VERSION "HNNBNNNYNNNNNNNNNNNNNNNNNNNNNNNNNNNNNNNNNN/4/%%%/4/'%**4NNN///"

NS_ :

BS_:

BU_: BAP_Tester BedienDisp_mi BedienDisp_vo_mi CDI ConMod_CD DashCAM Gateway_Max ICC_IO_Node LSH OCU RDK_RS3 Sound_MIB_ab_Gen3 STH ZR_MIB_EINSTIEG_ab_Gen3 ZR_MIB_OPTION_ab_Gen3 ZR_MIB_TOP_ab_Gen3

BO_ 2536735504 BAP_SecEvents2_FSG_01: 8 ZR_MIB_EINSTIEG_ab_Gen3
 SG_ BAP_SecEvents2_FSG_01_Header : 0|64@1+ (1.0,0.0) [0.0|18446744073709551615] ""  Gateway_Max,OCU

BO_ 2536706560 BAP_SIA_ASG_01: 8 ZR_MIB_EINSTIEG_ab_Gen3
 SG_ BAP_SIA_ASG_01_Header : 0|8@1+ (1.0,0.0) [0.0|255] ""  Gateway_Max

BO_ 2536706561 BAP_SIA_ASG_02: 8 OCU
 SG_ BAP_SIA_ASG_02_Header : 0|8@1+ (1.0,0.0) [0.0|255] ""  Gateway_Max

BO_ 2536706576 BAP_SIA_FSG_01: 8 Gateway_Max
 SG_ BAP_SIA_FSG_01_Header : 0|8@1+ (1.0,0.0) [0.0|255] ""  OCU,ZR_MIB_EINSTIEG_ab_Gen3,ZR_MIB_OPTION_ab_Gen3,ZR_MIB_TOP_ab_Gen3

BO_ 2536706048 BAP_Sitz1_ASG_01: 8 ZR_MIB_EINSTIEG_ab_Gen3
 SG_ BAP_Sitz1_ASG_01_Header : 0|64@1+ (1.0,0.0) [0.0|18446744073709551615] ""  Gateway_Max

BO_ 2536706049 BAP_Sitz1_ASG_02: 8 OCU
 SG_ BAP_Sitz1_ASG_02_Header : 0|8@1+ (1,0) [0|255] "Unit_None"  Gateway_Max

BO_ 2536706064 BAP_Sitz1_FSG_01: 8 Gateway_Max
 SG_ BAP_Sitz1_FSG_01_Header : 0|8@1+ (1.0,0.0) [0.0|255] ""  OCU,ZR_MIB_EINSTIEG_ab_Gen3,ZR_MIB_OPTION_ab_Gen3,ZR_MIB_TOP_ab_Gen3

BO_ 2536710144 BAP_Sitz2_ASG_01: 8 ZR_MIB_EINSTIEG_ab_Gen3
 SG_ BAP_Sitz2_ASG_01_Header : 0|8@1+ (1.0,0.0) [0.0|255] ""  Gateway_Max

BO_ 2536710160 BAP_Sitz2_FSG_01: 8 Gateway_Max
 SG_ BAP_Sitz2_FSG_01_Header : 0|8@1+ (1.0,0.0) [0.0|255] ""  ZR_MIB_EINSTIEG_ab_Gen3,ZR_MIB_OPTION_ab_Gen3,ZR_MIB_TOP_ab_Gen3

BO_ 2536736000 BAP_SLCView_ASG_01: 8 ZR_MIB_EINSTIEG_ab_Gen3
 SG_ BAP_SLCView_ASG_01_Header : 0|64@1+ (1.0,0.0) [0.0|18446744073709551615] ""  Gateway_Max

BO_ 2536736016 BAP_SLCView_FSG_01: 8 Gateway_Max
 SG_ BAP_SLCView_FSG_01_Header : 0|64@1+ (1.0,0.0) [0.0|18446744073709551615] ""  ZR_MIB_EINSTIEG_ab_Gen3,ZR_MIB_OPTION_ab_Gen3

BO_ 2536720896 BAP_Statistics_ASG_01: 8 ZR_MIB_EINSTIEG_ab_Gen3
 SG_ BAP_Statistics_ASG_01_Header : 0|8@1+ (1,0) [0|255] "Unit_None"  Gateway_Max

BO_ 2536720912 BAP_Statistics_FSG_01: 8 Gateway_Max
 SG_ BAP_Statistics_FSG_01_Header : 0|8@1+ (1,0) [0|255] "Unit_None"  ZR_MIB_EINSTIEG_ab_Gen3,ZR_MIB_OPTION_ab_Gen3,ZR_MIB_TOP_ab_Gen3

BO_ 2536721152 BAP_Sunroof_ASG_01: 8 ZR_MIB_OPTION_ab_Gen3
 SG_ BAP_Sunroof_ASG_01_Header : 0|8@1+ (1,0) [0|255] "Unit_None"  Gateway_Max

BO_ 2536721168 BAP_Sunroof_FSG_01: 8 Gateway_Max
 SG_ BAP_Sunroof_FSG_01_Header : 0|8@1+ (1,0) [0|255] "Unit_None"  ZR_MIB_OPTION_ab_Gen3

BO_ 2536708608 BAP_SWA_ASG_01: 8 ZR_MIB_EINSTIEG_ab_Gen3
 SG_ BAP_SWA_ASG_01_Header : 0|8@1+ (1.0,0.0) [0.0|255] ""  Gateway_Max

BO_ 2536708610 BAP_SWA_ASG_03: 8 OCU
 SG_ BAP_SWA_ASG_03_Header : 0|8@1+ (1,0) [0|255] "Unit_None"  Gateway_Max

BO_ 2536708624 BAP_SWA_FSG_01: 8 Gateway_Max
 SG_ BAP_SWA_FSG_01_Header : 0|8@1+ (1.0,0.0) [0.0|255] ""  OCU,ZR_MIB_EINSTIEG_ab_Gen3,ZR_MIB_OPTION_ab_Gen3,ZR_MIB_TOP_ab_Gen3

BO_ 2536712448 BAP_Telefon2_ASG_01: 8 Gateway_Max
 SG_ BAP_Telefon2_ASG_01_Header : 0|8@1+ (1.0,0.0) [0.0|255] ""  ZR_MIB_OPTION_ab_Gen3,ZR_MIB_TOP_ab_Gen3

BO_ 2536712449 BAP_Telefon2_ASG_02: 8 Gateway_Max
 SG_ BAP_Telefon2_ASG_02_Header : 0|8@1+ (1,0) [0|255] "Unit_None"  ZR_MIB_OPTION_ab_Gen3

BO_ 2536712464 BAP_Telefon2_FSG_01: 8 ZR_MIB_OPTION_ab_Gen3
 SG_ BAP_Telefon2_FSG_01_Header : 0|8@1+ (1.0,0.0) [0.0|255] ""  Gateway_Max

BO_ 2536712465 BAP_Telefon2_FSG_02: 8 ZR_MIB_OPTION_ab_Gen3
 SG_ BAP_Telefon2_FSG_02_Header : 0|8@1+ (1,0) [0|255] "Unit_None"  Gateway_Max

BO_ 2536712192 BAP_Telefon_ASG_01: 8 Gateway_Max
 SG_ BAP_Telefon_ASG_01_Header : 0|8@1+ (1.0,0.0) [0.0|255] ""  ZR_MIB_EINSTIEG_ab_Gen3,ZR_MIB_OPTION_ab_Gen3,ZR_MIB_TOP_ab_Gen3

BO_ 2536712193 BAP_Telefon_ASG_02: 8 Gateway_Max
 SG_ BAP_Telefon_ASG_02_Header : 0|8@1+ (1.0,0.0) [0.0|255] ""  ZR_MIB_EINSTIEG_ab_Gen3,ZR_MIB_OPTION_ab_Gen3,ZR_MIB_TOP_ab_Gen3

BO_ 2536712194 BAP_Telefon_ASG_03: 8 Gateway_Max
 SG_ BAP_Telefon_ASG_03_Header : 0|8@1+ (1,0) [0|255] "Unit_None"  ZR_MIB_EINSTIEG_ab_Gen3,ZR_MIB_OPTION_ab_Gen3,ZR_MIB_TOP_ab_Gen3

BO_ 2536712195 BAP_Telefon_ASG_04: 8 Gateway_Max
 SG_ BAP_Telefon_ASG_04_Header : 0|8@1+ (1,0) [0|255] "Unit_None"  ZR_MIB_EINSTIEG_ab_Gen3,ZR_MIB_OPTION_ab_Gen3,ZR_MIB_TOP_ab_Gen3

BO_ 2536712208 BAP_Telefon_FSG_01: 8 ZR_MIB_EINSTIEG_ab_Gen3
 SG_ BAP_Telefon_FSG_01_Header : 0|8@1+ (1.0,0.0) [0.0|255] ""  Gateway_Max

BO_ 2536712209 BAP_Telefon_FSG_02: 8 ZR_MIB_EINSTIEG_ab_Gen3
 SG_ BAP_Telefon_FSG_02_Header : 0|8@1+ (1.0,0.0) [0.0|255] ""  Gateway_Max

BO_ 2536726273 BAP_TPA_ASG_02: 8 ZR_MIB_EINSTIEG_ab_Gen3
 SG_ BAP_TPA_ASG_02_Header : 0|64@1+ (1.0,0.0) [0.0|18446744073709551615] ""  Gateway_Max

BO_ 2536726288 BAP_TPA_FSG_01: 8 Gateway_Max
 SG_ BAP_TPA_FSG_01_Header : 0|64@1+ (1.0,0.0) [0.0|18446744073709551615] ""  ZR_MIB_EINSTIEG_ab_Gen3,ZR_MIB_OPTION_ab_Gen3,ZR_MIB_TOP_ab_Gen3

BO_ 2536715776 BAP_TrailerAssist_ASG_01: 8 ZR_MIB_EINSTIEG_ab_Gen3
 SG_ BAP_TrailerAssist_ASG_01_Header : 0|8@1+ (1.0,0.0) [0.0|255] ""  Gateway_Max

BO_ 2536715792 BAP_TrailerAssist_FSG_01: 8 Gateway_Max
 SG_ BAP_TrailerAssist_FSG_01_Header : 0|8@1+ (1.0,0.0) [0.0|255] ""  ZR_MIB_EINSTIEG_ab_Gen3,ZR_MIB_OPTION_ab_Gen3

BO_ 2536706304 BAP_Uhrzeit_ASG_01: 8 ZR_MIB_EINSTIEG_ab_Gen3
 SG_ BAP_Uhrzeit_ASG_01_Header : 0|8@1+ (1.0,0.0) [0.0|255] ""  Gateway_Max

BO_ 2536706308 BAP_Uhrzeit_ASG_05: 8 OCU
 SG_ BAP_Uhrzeit_ASG_05_Header : 0|8@1+ (1.0,0.0) [0.0|255] ""  Gateway_Max

BO_ 2536706320 BAP_Uhrzeit_FSG_01: 8 Gateway_Max
 SG_ BAP_Uhrzeit_FSG_01_Header : 0|8@1+ (1.0,0.0) [0.0|255] ""  OCU,ZR_MIB_EINSTIEG_ab_Gen3,ZR_MIB_OPTION_ab_Gen3,ZR_MIB_TOP_ab_Gen3

BO_ 2536710400 BAP_VZA_ASG_01: 8 ZR_MIB_EINSTIEG_ab_Gen3
 SG_ BAP_VZA_ASG_01_Header : 0|8@1+ (1.0,0.0) [0.0|255] ""  Gateway_Max

BO_ 2536710403 BAP_VZA_ASG_04: 8 OCU
 SG_ BAP_VZA_ASG_04_Header : 0|8@1+ (1,0) [0|255] "Unit_None"  Gateway_Max

BO_ 2536710416 BAP_VZA_FSG_01: 8 Gateway_Max
 SG_ BAP_VZA_FSG_01_Header : 0|8@1+ (1.0,0.0) [0.0|255] ""  OCU,ZR_MIB_EINSTIEG_ab_Gen3,ZR_MIB_OPTION_ab_Gen3,ZR_MIB_TOP_ab_Gen3

BO_ 2536705024 BAP_Wiper_ASG_01: 8 ZR_MIB_EINSTIEG_ab_Gen3
 SG_ BAP_Wiper_ASG_01_Header : 0|8@1+ (1.0,0.0) [0.0|255] ""  Gateway_Max

BO_ 2536705025 BAP_Wiper_ASG_02: 8 OCU
 SG_ BAP_Wiper_ASG_02_Header : 0|8@1+ (1,0) [0|255] "Unit_None"  Gateway_Max

BO_ 2536705040 BAP_Wiper_FSG_01: 8 Gateway_Max
 SG_ BAP_Wiper_FSG_01_Header : 0|8@1+ (1.0,0.0) [0.0|255] ""  OCU,ZR_MIB_EINSTIEG_ab_Gen3,ZR_MIB_OPTION_ab_Gen3,ZR_MIB_TOP_ab_Gen3

BO_ 1626 BCM_01: 8 Gateway_Max
 SG_ BCM_Bremsbelag_Sensor : 12|1@1+ (1.0,0.0) [0.0|1] ""  OCU
 SG_ BCM_Bremsfluessigkeit_Sensor : 13|1@1+ (1.0,0.0) [0.0|1] ""  OCU
 SG_ BCM1_Licht_Warn : 14|1@1+ (1.0,0.0) [0.0|1] ""  BedienDisp_vo_mi,OCU
 SG_ BCM_Waschwasser_Sensor : 15|1@1+ (1.0,0.0) [0.0|1] ""  OCU
 SG_ BCM_Kuehlmittel_Sensor : 16|1@1+ (1.0,0.0) [0.0|1] ""  OCU
 SG_ BCM1_Kl_15_HW_erkannt : 17|1@1+ (1.0,0.0) [0.0|1] ""  Vector__XXX
 SG_ BCM1_Kl_15_Sig_HW_erkannt : 18|1@1+ (1.0,0.0) [0.0|1] ""  Vector__XXX
 SG_ BCM_Kuehlmittel_Sensor_02 : 19|1@1+ (1.0,0.0) [0.0|1] ""  Vector__XXX
 SG_ BCM1_Hinweis_Lichtnachlauf : 20|1@1+ (1.0,0.0) [0.0|1] ""  Vector__XXX
 SG_ BCM_Offroad_Taste : 21|1@1+ (1.0,0.0) [0.0|1] ""  Vector__XXX
 SG_ BCM_Charisma_Taste2 : 22|1@1+ (1.0,0.0) [0.0|1] ""  Vector__XXX
 SG_ BCM_Hybrid_StSt_Taste_Fehler : 23|1@1+ (1.0,0.0) [0.0|1] ""  Vector__XXX
 SG_ BCM_Hybrid_StartStopp_Taste : 24|1@1+ (1.0,0.0) [0.0|1] ""  Vector__XXX
 SG_ BCM1_Warnblink_Taster : 25|1@1+ (1.0,0.0) [0.0|1] ""  Vector__XXX
 SG_ BCM1_Valet_Parking_Taster : 26|1@1+ (1.0,0.0) [0.0|1] ""  Vector__XXX
 SG_ BCM1_LDS_Stellung : 27|3@1+ (1.0,0.0) [0.0|7] ""  OCU
 SG_ BCM1_Rueckfahrlicht_Schalter : 30|1@1+ (1.0,0.0) [0.0|1] ""  OCU
 SG_ BCM1_MH_Schalter : 31|1@1+ (1.0,0.0) [0.0|1] ""  OCU,ZR_MIB_EINSTIEG_ab_Gen3,ZR_MIB_OPTION_ab_Gen3
 SG_ BCM1_MH_WIV_Schalter : 32|1@1+ (1.0,0.0) [0.0|1] ""  Vector__XXX
 SG_ BCM_Eco_Charisma_Taste : 33|1@1+ (1.0,0.0) [0.0|1] ""  Vector__XXX
 SG_ BCM1_NV_Taster : 34|1@1+ (1.0,0.0) [0.0|1] ""  Vector__XXX
 SG_ BCM1_AFS_Lampe : 35|1@1+ (1.0,0.0) [0.0|1] ""  Vector__XXX
 SG_ BCM1_Reisemodus_Texte : 36|2@1+ (1.0,0.0) [0.0|3] ""  Vector__XXX
 SG_ BCM1_Lichtwarn_Texte : 38|2@1+ (1.0,0.0) [0.0|3] ""  Vector__XXX
 SG_ Gong_TFL_Umschaltung : 40|1@1+ (1.0,0.0) [0.0|1] ""  Vector__XXX
 SG_ BCM_ValetTaster_Fkts_LED : 42|1@1+ (1.0,0.0) [0.0|1] ""  ZR_MIB_EINSTIEG_ab_Gen3,ZR_MIB_OPTION_ab_Gen3,ZR_MIB_TOP_ab_Gen3
 SG_ LRH_Taster : 43|1@1+ (1.0,0.0) [0.0|1] ""  OCU
 SG_ APS_Tongeber_defekt : 44|1@1+ (1.0,0.0) [0.0|1] ""  Vector__XXX
 SG_ BCM1_EasyEntry_Status : 45|1@1+ (1.0,0.0) [0.0|1] ""  Vector__XXX
 SG_ BCM1_Lenksaeule_aktiv : 46|1@1+ (1.0,0.0) [0.0|1] ""  Vector__XXX
 SG_ BCM1_Spannungs_Anf : 47|2@1+ (1.0,0.0) [0.0|3] ""  Vector__XXX
 SG_ DWA_Alarmquelle : 49|5@1+ (1.0,0.0) [0.0|31] ""  OCU
 SG_ DWA_Einschraenkung : 54|1@1+ (1.0,0.0) [0.0|1] ""  Vector__XXX
 SG_ BCM_HBFS_EOE_aktiv : 56|1@1+ (1.0,0.0) [0.0|1] ""  Vector__XXX
 SG_ BCM_HFS_EOE_aktiv : 57|1@1+ (1.0,0.0) [0.0|1] ""  Vector__XXX
 SG_ BCM_Anf_AAW_MoLaWa : 58|2@1+ (1.0,0.0) [0.0|3] ""  Vector__XXX
 SG_ BCM_Handbremse_Hinweis : 60|1@1+ (1.0,0.0) [0.0|1] ""  Vector__XXX
 SG_ BCM_Waehlhebel_P_Hinweis : 61|1@1+ (1.0,0.0) [0.0|1] ""  Vector__XXX
 SG_ BCM1_Fahrlicht_Hinweis : 62|1@1+ (1.0,0.0) [0.0|1] ""  Vector__XXX
 SG_ BCM_HDF_betaetigt : 63|1@1+ (1.0,0.0) [0.0|1] ""  Vector__XXX

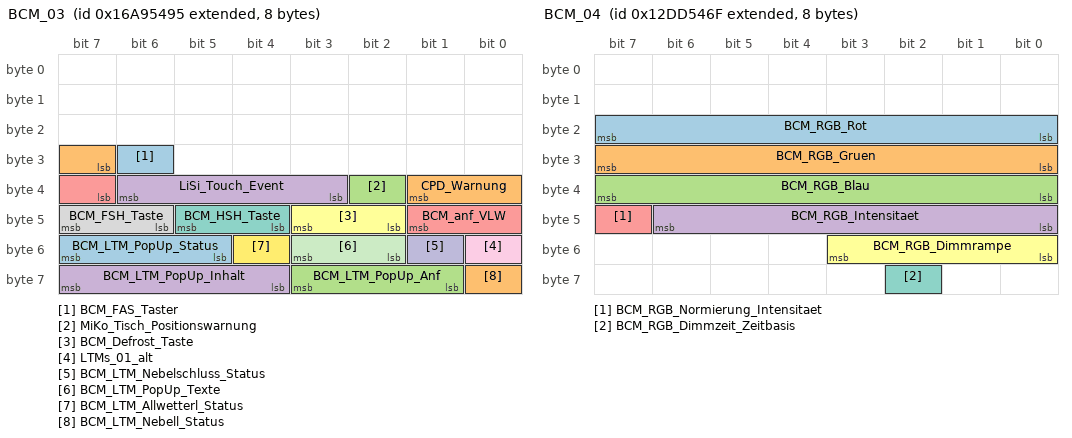
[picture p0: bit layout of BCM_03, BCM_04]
BO_ 2527679637 BCM_03: 8 Gateway_Max
 SG_ BCM_FAS_Taster : 30|1@1+ (1.0,0.0) [0.0|1] ""  ZR_MIB_TOP_ab_Gen3
 SG_ CPD_Warnung : 31|3@1+ (1.0,0.0) [0.0|7] ""  Vector__XXX
 SG_ MiKo_Tisch_Positionswarnung : 34|1@1+ (1.0,0.0) [0.0|1] ""  Vector__XXX
 SG_ LiSi_Touch_Event : 35|4@1+ (1.0,0.0) [0.0|15] ""  ICC_IO_Node,ZR_MIB_EINSTIEG_ab_Gen3,ZR_MIB_OPTION_ab_Gen3,ZR_MIB_TOP_ab_Gen3
 SG_ BCM_anf_VLW : 39|3@1+ (1.0,0.0) [0.0|7] ""  Vector__XXX
 SG_ BCM_Defrost_Taste : 42|2@1+ (1.0,0.0) [0.0|3] ""  Vector__XXX
 SG_ BCM_HSH_Taste : 44|2@1+ (1.0,0.0) [0.0|3] ""  Vector__XXX
 SG_ BCM_FSH_Taste : 46|2@1+ (1.0,0.0) [0.0|3] ""  Vector__XXX
 SG_ LTMs_01_alt : 48|1@1+ (1.0,0.0) [0.0|1] ""  Vector__XXX
 SG_ BCM_LTM_Nebelschluss_Status : 49|1@1+ (1.0,0.0) [0.0|1] ""  Vector__XXX
 SG_ BCM_LTM_PopUp_Texte : 50|2@1+ (1.0,0.0) [0.0|3] ""  Vector__XXX
 SG_ BCM_LTM_Allwetterl_Status : 52|1@1+ (1.0,0.0) [0.0|1] ""  Vector__XXX
 SG_ BCM_LTM_PopUp_Status : 53|3@1+ (1.0,0.0) [0.0|7] ""  Vector__XXX
 SG_ BCM_LTM_Nebell_Status : 56|1@1+ (1.0,0.0) [0.0|1] ""  Vector__XXX
 SG_ BCM_LTM_PopUp_Anf : 57|3@1+ (1.0,0.0) [0.0|7] ""  Vector__XXX
 SG_ BCM_LTM_PopUp_Inhalt : 60|4@1+ (1.0,0.0) [0.0|15] ""  Vector__XXX

BO_ 2463978607 BCM_04: 8 Gateway_Max
 SG_ BCM_RGB_Rot : 16|8@1+ (1,0) [0|255] ""  BedienDisp_mi,BedienDisp_vo_mi,CDI,ZR_MIB_EINSTIEG_ab_Gen3,ZR_MIB_OPTION_ab_Gen3,ZR_MIB_TOP_ab_Gen3
 SG_ BCM_RGB_Gruen : 24|8@1+ (1,0) [0|255] ""  BedienDisp_mi,BedienDisp_vo_mi,CDI,ZR_MIB_EINSTIEG_ab_Gen3,ZR_MIB_OPTION_ab_Gen3,ZR_MIB_TOP_ab_Gen3
 SG_ BCM_RGB_Blau : 32|8@1+ (1,0) [0|255] ""  BedienDisp_mi,BedienDisp_vo_mi,CDI,ZR_MIB_EINSTIEG_ab_Gen3,ZR_MIB_OPTION_ab_Gen3,ZR_MIB_TOP_ab_Gen3
 SG_ BCM_RGB_Intensitaet : 40|7@1+ (1,0) [0|100] "Unit_PerCent"  BedienDisp_mi,BedienDisp_vo_mi
 SG_ BCM_RGB_Normierung_Intensitaet : 47|1@1+ (1.0,0.0) [0.0|1] ""  Vector__XXX
 SG_ BCM_RGB_Dimmrampe : 48|4@1+ (0.25,0) [0.00|3.75] "Unit_Secon"  BedienDisp_mi,BedienDisp_vo_mi
 SG_ BCM_RGB_Dimmzeit_Zeitbasis : 58|1@1+ (1.0,0.0) [0.0|1] ""  BedienDisp_mi,BedienDisp_vo_mi

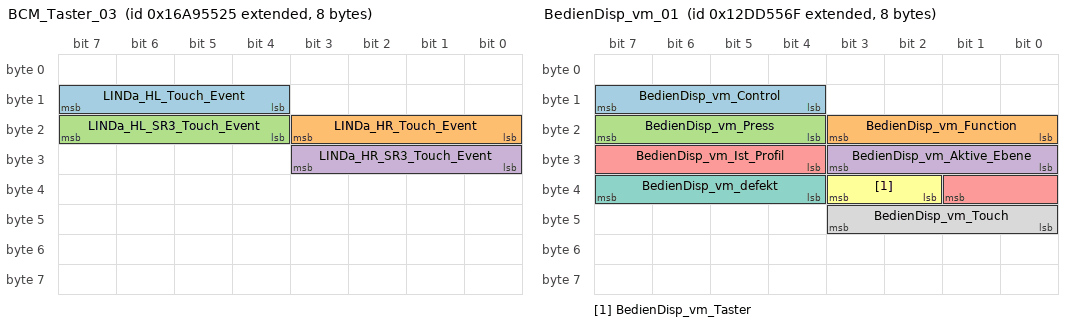
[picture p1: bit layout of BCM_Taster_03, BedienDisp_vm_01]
BO_ 2527679781 BCM_Taster_03: 8 Gateway_Max
 SG_ LINDa_HL_Touch_Event : 12|4@1+ (1.0,0.0) [0.0|15] ""  ICC_IO_Node,ZR_MIB_EINSTIEG_ab_Gen3,ZR_MIB_OPTION_ab_Gen3,ZR_MIB_TOP_ab_Gen3
 SG_ LINDa_HR_Touch_Event : 16|4@1+ (1.0,0.0) [0.0|15] ""  ICC_IO_Node,ZR_MIB_EINSTIEG_ab_Gen3,ZR_MIB_OPTION_ab_Gen3,ZR_MIB_TOP_ab_Gen3
 SG_ LINDa_HL_SR3_Touch_Event : 20|4@1+ (1.0,0.0) [0.0|15] ""  ICC_IO_Node,ZR_MIB_EINSTIEG_ab_Gen3,ZR_MIB_OPTION_ab_Gen3,ZR_MIB_TOP_ab_Gen3
 SG_ LINDa_HR_SR3_Touch_Event : 24|4@1+ (1.0,0.0) [0.0|15] ""  ICC_IO_Node,ZR_MIB_EINSTIEG_ab_Gen3,ZR_MIB_OPTION_ab_Gen3,ZR_MIB_TOP_ab_Gen3

BO_ 2463978882 BedienDisp_hbfs_01: 8 Gateway_Max
 SG_ BedienDisp_hbfs_01_CRC : 0|8@1+ (1,0) [0|255] ""  Vector__XXX
 SG_ BedienDisp_hbfs_01_BZ : 8|4@1+ (1,0) [0|15] ""  Vector__XXX
 SG_ BedienDisp_hbfs_control_vol : 12|4@1+ (1.0,0.0) [0.0|15] ""  ZR_MIB_OPTION_ab_Gen3
 SG_ BedienDisp_hbfs_fader : 16|4@1+ (1.0,0.0) [0.0|15] ""  Vector__XXX
 SG_ BedienDisp_hbfs_surround : 20|4@1+ (1.0,0.0) [0.0|15] ""  ZR_MIB_OPTION_ab_Gen3
 SG_ BedienDisp_hbfs_sound : 24|4@1+ (1.0,0.0) [0.0|15] ""  Vector__XXX
 SG_ BedienDisp_hbfs_Lordose_hoch : 28|1@1+ (1.0,0.0) [0.0|1] ""  Vector__XXX
 SG_ BedienDisp_hbfs_Lordose_runter : 29|1@1+ (1.0,0.0) [0.0|1] ""  Vector__XXX
 SG_ BedienDisp_hbfs_Lordose_vor : 30|1@1+ (1.0,0.0) [0.0|1] ""  Vector__XXX
 SG_ BedienDisp_hbfs_Lordose_zurueck : 31|1@1+ (1.0,0.0) [0.0|1] ""  Vector__XXX
 SG_ BedienDisp_hbfs_touch : 32|4@1+ (1.0,0.0) [0.0|15] ""  ZR_MIB_OPTION_ab_Gen3
 SG_ BedienDisp_hbfs_sound_fokus : 36|4@1+ (1.0,0.0) [0.0|15] ""  ZR_MIB_OPTION_ab_Gen3
 SG_ BedienDisp_hbfs_surround_02 : 40|7@1+ (1,0) [0|100] "Unit_None"  Vector__XXX
 SG_ BedienDisp_hbfs_control_vol_02 : 47|7@1+ (1,0) [0|100] "Unit_None"  ZR_MIB_OPTION_ab_Gen3
 SG_ BedienDisp_HBFSFo_Bestaetigung : 54|2@1+ (1.0,0.0) [0.0|3] ""  Vector__XXX
 SG_ BedienDisp_HBFSFo_Stoerung : 56|2@1+ (1.0,0.0) [0.0|3] ""  Vector__XXX
 SG_ BedienDisp_hbfs_UseCase_Pos : 58|3@1+ (1.0,0.0) [0.0|7] ""  Vector__XXX

BO_ 2463978886 BedienDisp_hbfs_02: 8 Gateway_Max
 SG_ BedienDisp_hbfs_02_CRC : 0|8@1+ (1,0) [0|255] ""  Vector__XXX
 SG_ BedienDisp_hbfs_02_BZ : 8|4@1+ (1,0) [0|15] ""  Vector__XXX
 SG_ BedienDisp_hbfs_Sitz_Laengs : 12|3@1+ (1.0,0.0) [0.0|7] ""  Vector__XXX
 SG_ BedienDisp_hbfs_Sitz_Hoehe : 15|2@1+ (1.0,0.0) [0.0|3] ""  Vector__XXX
 SG_ BedienDisp_hbfs_Sitz_Neigung : 17|3@1+ (1.0,0.0) [0.0|7] ""  Vector__XXX
 SG_ BedienDisp_hbfs_Sitz_Bein : 20|3@1+ (1.0,0.0) [0.0|7] ""  Vector__XXX
 SG_ BedienDisp_hbfs_Sitz_Lehne : 23|3@1+ (1.0,0.0) [0.0|7] ""  Vector__XXX
 SG_ BedienDisp_hbfs_Sitz_Lehnekopf : 26|2@1+ (1.0,0.0) [0.0|3] ""  Vector__XXX
 SG_ BedienDisp_hbfs_Sitz_Kopf : 28|3@1+ (1.0,0.0) [0.0|7] ""  Vector__XXX
 SG_ BedienDisp_hbfs_Sitz_Arm : 31|3@1+ (1.0,0.0) [0.0|7] ""  Vector__XXX
 SG_ BedienDisp_hbfs_Seat_SetReset : 34|2@1+ (1.0,0.0) [0.0|3] ""  Vector__XXX
 SG_ BedienDisp_hbfs_Seat_Storage : 36|3@1+ (1.0,0.0) [0.0|7] ""  Vector__XXX
 SG_ BedienDisp_hbfs_Mem_Start : 39|2@1+ (1.0,0.0) [0.0|3] ""  Vector__XXX
 SG_ BedienDisp_hbfs_Cargo_Pos : 41|2@1+ (1.0,0.0) [0.0|3] ""  Vector__XXX
 SG_ BedienDisp_hbfs_Normal_Pos : 43|2@1+ (1.0,0.0) [0.0|3] ""  Vector__XXX
 SG_ BedienDisp_hbfs_BF_Hoehe : 45|2@1+ (1.0,0.0) [0.0|3] ""  Vector__XXX
 SG_ BedienDisp_hbfs_BF_Laengs : 47|3@1+ (1.0,0.0) [0.0|7] ""  Vector__XXX
 SG_ BedienDisp_hbfs_BF_Lehne : 50|3@1+ (1.0,0.0) [0.0|7] ""  Vector__XXX
 SG_ BedienDisp_hbfs_Memo_Pos : 53|3@1+ (1.0,0.0) [0.0|7] ""  Vector__XXX
 SG_ BedienDisp_hbfs_Sitz_Stop : 56|2@1+ (1.0,0.0) [0.0|3] ""  Vector__XXX
 SG_ BedienDisp_hbfs_Komfor_Pos : 58|3@1+ (1.0,0.0) [0.0|7] ""  Vector__XXX

BO_ 2463978881 BedienDisp_hfs_01: 8 Gateway_Max
 SG_ BedienDisp_hfs_01_CRC : 0|8@1+ (1,0) [0|255] ""  Vector__XXX
 SG_ BedienDisp_hfs_01_BZ : 8|4@1+ (1,0) [0|15] ""  Vector__XXX
 SG_ BedienDisp_hfs_control_vol : 12|4@1+ (1.0,0.0) [0.0|15] ""  ZR_MIB_OPTION_ab_Gen3
 SG_ BedienDisp_hfs_fader : 16|4@1+ (1.0,0.0) [0.0|15] ""  Vector__XXX
 SG_ BedienDisp_hfs_surround : 20|4@1+ (1.0,0.0) [0.0|15] ""  ZR_MIB_OPTION_ab_Gen3
 SG_ BedienDisp_hfs_sound : 24|4@1+ (1.0,0.0) [0.0|15] ""  Vector__XXX
 SG_ BedienDisp_hfs_Lordose_hoch : 28|1@1+ (1.0,0.0) [0.0|1] ""  Vector__XXX
 SG_ BedienDisp_hfs_Lordose_runter : 29|1@1+ (1.0,0.0) [0.0|1] ""  Vector__XXX
 SG_ BedienDisp_hfs_Lordose_vor : 30|1@1+ (1.0,0.0) [0.0|1] ""  Vector__XXX
 SG_ BedienDisp_hfs_Lordose_zurueck : 31|1@1+ (1.0,0.0) [0.0|1] ""  Vector__XXX
 SG_ BedienDisp_hfs_touch : 32|4@1+ (1.0,0.0) [0.0|15] ""  ZR_MIB_OPTION_ab_Gen3
 SG_ BedienDisp_hfs_sound_fokus : 36|4@1+ (1.0,0.0) [0.0|15] ""  ZR_MIB_OPTION_ab_Gen3
 SG_ BedienDisp_hfs_surround_02 : 40|7@1+ (1,0) [0|100] "Unit_None"  Vector__XXX
 SG_ BedienDisp_hfs_control_vol_02 : 47|7@1+ (1,0) [0|100] "Unit_None"  ZR_MIB_OPTION_ab_Gen3
 SG_ BedienDisp_HFSFo_Bestaetigung : 54|2@1+ (1.0,0.0) [0.0|3] ""  Vector__XXX
 SG_ BedienDisp_HFSFo_Stoerung : 56|2@1+ (1.0,0.0) [0.0|3] ""  Vector__XXX
 SG_ BedienDisp_hfs_UseCase_Pos : 58|3@1+ (1.0,0.0) [0.0|7] ""  Vector__XXX

BO_ 2463978885 BedienDisp_hfs_02: 8 Gateway_Max
 SG_ BedienDisp_hfs_02_CRC : 0|8@1+ (1,0) [0|255] ""  Vector__XXX
 SG_ BedienDisp_hfs_02_BZ : 8|4@1+ (1,0) [0|15] ""  Vector__XXX
 SG_ BedienDisp_hfs_Sitz_Laengs : 12|3@1+ (1.0,0.0) [0.0|7] ""  Vector__XXX
 SG_ BedienDisp_hfs_Sitz_Hoehe : 15|2@1+ (1.0,0.0) [0.0|3] ""  Vector__XXX
 SG_ BedienDisp_hfs_Sitz_Neigung : 17|3@1+ (1.0,0.0) [0.0|7] ""  Vector__XXX
 SG_ BedienDisp_hfs_Sitz_Bein : 20|3@1+ (1.0,0.0) [0.0|7] ""  Vector__XXX
 SG_ BedienDisp_hfs_Sitz_Lehne : 23|3@1+ (1.0,0.0) [0.0|7] ""  Vector__XXX
 SG_ BedienDisp_hfs_Sitz_Lehnekopf : 26|2@1+ (1.0,0.0) [0.0|3] ""  Vector__XXX
 SG_ BedienDisp_hfs_Sitz_Kopf : 28|3@1+ (1.0,0.0) [0.0|7] ""  Vector__XXX
 SG_ BedienDisp_hfs_Sitz_Arm : 31|3@1+ (1.0,0.0) [0.0|7] ""  Vector__XXX
 SG_ BedienDisp_hfs_Seat_SetReset : 34|2@1+ (1.0,0.0) [0.0|3] ""  Vector__XXX
 SG_ BedienDisp_hfs_Seat_Storage : 36|3@1+ (1.0,0.0) [0.0|7] ""  Vector__XXX
 SG_ BedienDisp_hfs_Mem_Start : 39|2@1+ (1.0,0.0) [0.0|3] ""  Vector__XXX
 SG_ BedienDisp_hfs_Cargo_Pos : 41|2@1+ (1.0,0.0) [0.0|3] ""  Vector__XXX
 SG_ BedienDisp_hfs_Normal_Pos : 43|2@1+ (1.0,0.0) [0.0|3] ""  Vector__XXX
 SG_ BedienDisp_hfs_BF_Hoehe : 45|2@1+ (1.0,0.0) [0.0|3] ""  Vector__XXX
 SG_ BedienDisp_hfs_BF_Laengs : 47|3@1+ (1.0,0.0) [0.0|7] ""  Vector__XXX
 SG_ BedienDisp_hfs_BF_Lehne : 50|3@1+ (1.0,0.0) [0.0|7] ""  Vector__XXX
 SG_ BedienDisp_hfs_Memo_Pos : 53|3@1+ (1.0,0.0) [0.0|7] ""  Vector__XXX
 SG_ BedienDisp_hfs_Sitz_Stop : 56|2@1+ (1.0,0.0) [0.0|3] ""  Vector__XXX
 SG_ BedienDisp_hfs_Komfor_Pos : 58|3@1+ (1.0,0.0) [0.0|7] ""  Vector__XXX

BO_ 2463978863 BedienDisp_vm_01: 8 BedienDisp_vo_mi
 SG_ BedienDisp_vm_Control : 12|4@1+ (1.0,0.0) [0.0|15] ""  Gateway_Max,ZR_MIB_OPTION_ab_Gen3
 SG_ BedienDisp_vm_Function : 16|4@1+ (1.0,0.0) [0.0|15] ""  Gateway_Max,ZR_MIB_OPTION_ab_Gen3
 SG_ BedienDisp_vm_Press : 20|4@1+ (1.0,0.0) [0.0|15] ""  Gateway_Max,ZR_MIB_OPTION_ab_Gen3
 SG_ BedienDisp_vm_Aktive_Ebene : 24|4@1+ (1.0,0.0) [0.0|15] ""  Gateway_Max
 SG_ BedienDisp_vm_Ist_Profil : 28|6@1+ (1.0,0.0) [0.0|63] ""  Gateway_Max
 SG_ BedienDisp_vm_Taster : 34|2@1+ (1.0,0.0) [0.0|3] ""  Gateway_Max
 SG_ BedienDisp_vm_defekt : 36|4@1+ (1.0,0.0) [0.0|15] ""  Gateway_Max
 SG_ BedienDisp_vm_Touch : 40|4@1+ (1.0,0.0) [0.0|15] ""  Gateway_Max

BO_ 1635 BEM_02: 8 Gateway_Max
 SG_ NVEM_Abschaltstufe : 0|2@1+ (1.0,0.0) [0.0|3] ""  BedienDisp_vo_mi,CDI,ICC_IO_Node,LSH,OCU,STH,ZR_MIB_EINSTIEG_ab_Gen3,ZR_MIB_OPTION_ab_Gen3,ZR_MIB_TOP_ab_Gen3
 SG_ BEM_STH_Zielzeit : 3|4@1+ (5,0) [0|60] "Unit_Minut"  ICC_IO_Node,OCU,ZR_MIB_EINSTIEG_ab_Gen3,ZR_MIB_OPTION_ab_Gen3,ZR_MIB_TOP_ab_Gen3
 SG_ BEM_MMI_Vorwarnung : 7|1@1+ (1.0,0.0) [0.0|1] ""  ICC_IO_Node,ZR_MIB_EINSTIEG_ab_Gen3,ZR_MIB_OPTION_ab_Gen3,ZR_MIB_TOP_ab_Gen3
 SG_ BEM_HL_Kontingentierung : 8|6@1+ (50,-1000) [-1000|1000] "Unit_Watt"  ICC_IO_Node,ZR_MIB_EINSTIEG_ab_Gen3,ZR_MIB_OPTION_ab_Gen3,ZR_MIB_TOP_ab_Gen3
 SG_ NVEM_Freigabe_ZusBatt_Laden : 14|1@1+ (1.0,0.0) [0.0|1] ""  ICC_IO_Node,OCU,ZR_MIB_EINSTIEG_ab_Gen3,ZR_MIB_OPTION_ab_Gen3,ZR_MIB_TOP_ab_Gen3
 SG_ NVEM_Anf_SD_schalten : 15|1@1+ (1.0,0.0) [0.0|1] ""  ICC_IO_Node,ZR_MIB_EINSTIEG_ab_Gen3,ZR_MIB_OPTION_ab_Gen3,ZR_MIB_TOP_ab_Gen3
 SG_ BEM_Generatordiagnose : 16|2@1+ (1.0,0.0) [0.0|3] ""  ICC_IO_Node,ZR_MIB_EINSTIEG_ab_Gen3,ZR_MIB_OPTION_ab_Gen3,ZR_MIB_TOP_ab_Gen3
 SG_ BEM_Red_Innengeblaese : 18|2@1+ (1.0,0.0) [0.0|3] ""  ICC_IO_Node,OCU,ZR_MIB_EINSTIEG_ab_Gen3,ZR_MIB_OPTION_ab_Gen3,ZR_MIB_TOP_ab_Gen3
 SG_ BEM_STH_Einschaltverbot : 20|1@1+ (1.0,0.0) [0.0|1] ""  ICC_IO_Node,LSH,OCU,STH,ZR_MIB_EINSTIEG_ab_Gen3,ZR_MIB_OPTION_ab_Gen3,ZR_MIB_TOP_ab_Gen3
 SG_ BEM_HL_Regelung_Status : 21|3@1+ (1.0,0.0) [0.0|7] ""  ICC_IO_Node,LSH,OCU,STH,ZR_MIB_EINSTIEG_ab_Gen3,ZR_MIB_OPTION_ab_Gen3,ZR_MIB_TOP_ab_Gen3
 SG_ BEM_Ladezustand : 24|4@1+ (10,0) [0|100] "Unit_PerCent"  ICC_IO_Node,OCU,ZR_MIB_EINSTIEG_ab_Gen3,ZR_MIB_OPTION_ab_Gen3,ZR_MIB_TOP_ab_Gen3
 SG_ BEM_Batteriediagnose : 28|3@1+ (1.0,0.0) [0.0|7] ""  ICC_IO_Node,ZR_MIB_EINSTIEG_ab_Gen3,ZR_MIB_OPTION_ab_Gen3,ZR_MIB_TOP_ab_Gen3
 SG_ MIB_Stromsparmodus : 31|1@1+ (1.0,0.0) [0.0|1] ""  ICC_IO_Node,ZR_MIB_EINSTIEG_ab_Gen3,ZR_MIB_OPTION_ab_Gen3,ZR_MIB_TOP_ab_Gen3
 SG_ BEM_DFM : 32|5@1+ (3.225,0.025) [0.025|100.000] ""  ICC_IO_Node,OCU,ZR_MIB_EINSTIEG_ab_Gen3,ZR_MIB_OPTION_ab_Gen3,ZR_MIB_TOP_ab_Gen3
 SG_ BEM_REK_aktiv : 37|1@1+ (1.0,0.0) [0.0|1] ""  ICC_IO_Node,ZR_MIB_EINSTIEG_ab_Gen3,ZR_MIB_OPTION_ab_Gen3,ZR_MIB_TOP_ab_Gen3
 SG_ BEM_EMLIN_ungueltig : 38|1@1+ (1.0,0.0) [0.0|1] ""  ICC_IO_Node,OCU,ZR_MIB_EINSTIEG_ab_Gen3,ZR_MIB_OPTION_ab_Gen3,ZR_MIB_TOP_ab_Gen3
 SG_ BEM_Batt_Ab : 39|1@1+ (1.0,0.0) [0.0|1] ""  ICC_IO_Node,LSH,OCU,STH,ZR_MIB_EINSTIEG_ab_Gen3,ZR_MIB_OPTION_ab_Gen3,ZR_MIB_TOP_ab_Gen3
 SG_ BEM_UBDM : 40|8@1+ (0.05,5) [5.05|17.70] "Unit_Volt"  ICC_IO_Node,OCU,ZR_MIB_EINSTIEG_ab_Gen3,ZR_MIB_OPTION_ab_Gen3,ZR_MIB_TOP_ab_Gen3
 SG_ BEM_UGenSoll : 48|6@1+ (0.1,10.6) [10.6|16.0] "Unit_Volt"  ICC_IO_Node,ZR_MIB_EINSTIEG_ab_Gen3,ZR_MIB_OPTION_ab_Gen3,ZR_MIB_TOP_ab_Gen3
 SG_ BEM_Anf_KL15_schalten : 54|2@1+ (1.0,0.0) [0.0|3] ""  ICC_IO_Node,OCU,ZR_MIB_EINSTIEG_ab_Gen3,ZR_MIB_OPTION_ab_Gen3,ZR_MIB_TOP_ab_Gen3
 SG_ NVEM_Batterie_Service : 56|2@1+ (1.0,0.0) [0.0|3] ""  ICC_IO_Node,ZR_MIB_EINSTIEG_ab_Gen3,ZR_MIB_OPTION_ab_Gen3,ZR_MIB_TOP_ab_Gen3
 SG_ NVEM_Freigabe_OnlineUpdate : 58|1@1+ (1.0,0.0) [0.0|1] ""  ICC_IO_Node,OCU,ZR_MIB_EINSTIEG_ab_Gen3,ZR_MIB_OPTION_ab_Gen3,ZR_MIB_TOP_ab_Gen3
 SG_ NVEM_Freigabe_ORU4 : 59|2@1+ (1.0,0.0) [0.0|3] ""  ICC_IO_Node,ZR_MIB_EINSTIEG_ab_Gen3,ZR_MIB_OPTION_ab_Gen3,ZR_MIB_TOP_ab_Gen3
 SG_ NVEM_Verbraucherabsch_Anz : 61|1@1+ (1.0,0.0) [0.0|1] ""  ICC_IO_Node,ZR_MIB_EINSTIEG_ab_Gen3,ZR_MIB_OPTION_ab_Gen3,ZR_MIB_TOP_ab_Gen3

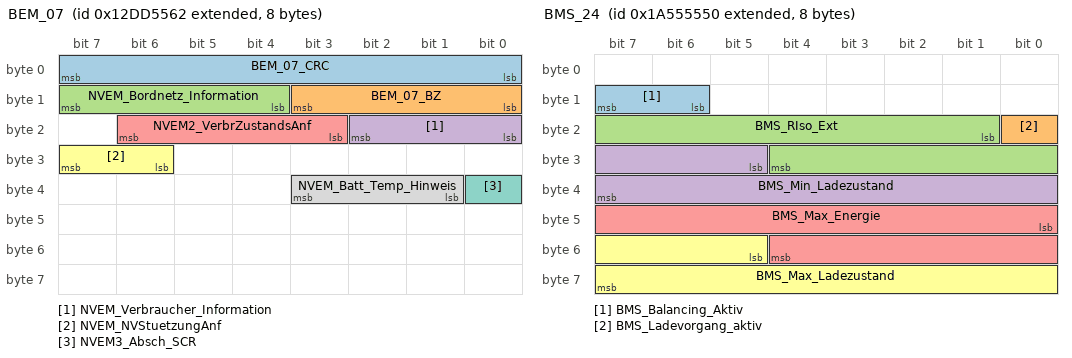
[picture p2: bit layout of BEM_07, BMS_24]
BO_ 2463978850 BEM_07: 8 Gateway_Max
 SG_ BEM_07_CRC : 0|8@1+ (1,0) [0|255] ""  Vector__XXX
 SG_ BEM_07_BZ : 8|4@1+ (1,0) [0|15] ""  Vector__XXX
 SG_ NVEM_Bordnetz_Information : 12|4@1+ (1.0,0.0) [0.0|15] ""  Vector__XXX
 SG_ NVEM_Verbraucher_Information : 16|3@1+ (1.0,0.0) [0.0|7] ""  CDI,OCU,ZR_MIB_EINSTIEG_ab_Gen3,ZR_MIB_OPTION_ab_Gen3,ZR_MIB_TOP_ab_Gen3
 SG_ NVEM2_VerbrZustandsAnf : 19|4@1+ (1.0,0.0) [0.0|15] ""  Vector__XXX
 SG_ NVEM_NVStuetzungAnf : 30|2@1+ (1.0,0.0) [0.0|3] ""  Vector__XXX
 SG_ NVEM3_Absch_SCR : 32|1@1+ (1.0,0.0) [0.0|1] ""  Vector__XXX
 SG_ NVEM_Batt_Temp_Hinweis : 33|3@1+ (1.0,0.0) [0.0|7] ""  Vector__XXX

BO_ 870 Blinkmodi_02: 8 Gateway_Max
 SG_ Blinkmodi_02_CRC : 0|8@1+ (1,0) [0|255] ""  Vector__XXX
 SG_ Blinkmodi_02_BZ : 8|4@1+ (1,0) [0|15] ""  Vector__XXX
 SG_ BM_ZV_auf : 12|1@1+ (1.0,0.0) [0.0|1] ""  Vector__XXX
 SG_ BM_ZV_zu : 13|1@1+ (1.0,0.0) [0.0|1] ""  Vector__XXX
 SG_ BM_DWA_ein : 14|1@1+ (1.0,0.0) [0.0|1] ""  OCU
 SG_ BM_DWA_Alarm : 15|1@1+ (1.0,0.0) [0.0|1] ""  OCU
 SG_ BM_Crash : 16|1@1+ (1.0,0.0) [0.0|1] ""  OCU
 SG_ BM_Panik : 17|1@1+ (1.0,0.0) [0.0|1] ""  OCU
 SG_ BM_Not_Bremsung : 18|1@1+ (1.0,0.0) [0.0|1] ""  OCU
 SG_ BM_GDO : 19|1@1+ (1.0,0.0) [0.0|1] ""  Vector__XXX
 SG_ BM_Warnblinken : 20|1@1+ (1.0,0.0) [0.0|1] ""  OCU
 SG_ BM_Taxi_Notalarm : 21|1@1+ (1.0,0.0) [0.0|1] ""  Vector__XXX
 SG_ BM_Telematik : 22|1@1+ (1.0,0.0) [0.0|1] ""  OCU
 SG_ BM_links : 23|1@1+ (1.0,0.0) [0.0|1] ""  DashCAM,OCU,ZR_MIB_EINSTIEG_ab_Gen3,ZR_MIB_OPTION_ab_Gen3
 SG_ BM_rechts : 24|1@1+ (1.0,0.0) [0.0|1] ""  DashCAM,OCU,ZR_MIB_EINSTIEG_ab_Gen3,ZR_MIB_OPTION_ab_Gen3
 SG_ Blinken_li_Fzg_Takt : 25|1@1+ (1.0,0.0) [0.0|1] ""  ZR_MIB_EINSTIEG_ab_Gen3
 SG_ Blinken_re_Fzg_Takt : 26|1@1+ (1.0,0.0) [0.0|1] ""  ZR_MIB_EINSTIEG_ab_Gen3
 SG_ Blinken_li_Kombi_Takt : 27|1@1+ (1.0,0.0) [0.0|1] ""  ZR_MIB_EINSTIEG_ab_Gen3,ZR_MIB_OPTION_ab_Gen3,ZR_MIB_TOP_ab_Gen3
 SG_ Blinken_re_Kombi_Takt : 28|1@1+ (1.0,0.0) [0.0|1] ""  ZR_MIB_EINSTIEG_ab_Gen3,ZR_MIB_OPTION_ab_Gen3,ZR_MIB_TOP_ab_Gen3
 SG_ BM_NBA_n_codiert_n_aktiv : 29|1@1+ (1.0,0.0) [0.0|1] ""  Vector__XXX
 SG_ BM_NBA_Status : 30|2@1+ (1.0,0.0) [0.0|3] ""  Vector__XXX
 SG_ BM_WBT_Beleuchtung : 32|1@1+ (1.0,0.0) [0.0|1] ""  Vector__XXX
 SG_ BM_HD_Oeffnung_angelernt : 33|1@1+ (1.0,0.0) [0.0|1] ""  Vector__XXX
 SG_ BM_Autobahn : 34|1@1+ (1.0,0.0) [0.0|1] ""  ZR_MIB_EINSTIEG_ab_Gen3,ZR_MIB_OPTION_ab_Gen3,ZR_MIB_TOP_ab_Gen3
 SG_ BM_Rollenmodus_Blinken : 35|1@1+ (1.0,0.0) [0.0|1] ""  Vector__XXX
 SG_ BM_Recas : 36|1@1+ (1.0,0.0) [0.0|1] ""  Vector__XXX
 SG_ BM_Wischblinken : 37|1@1+ (1.0,0.0) [0.0|1] ""  Vector__XXX
 SG_ BM_Telematik_Abbruchgrund : 38|6@1+ (1.0,0.0) [0.0|63] ""  OCU
 SG_ BM_PiloPa : 44|1@1+ (1.0,0.0) [0.0|1] ""  Vector__XXX
 SG_ SAL_TA_Blinken_Status : 45|3@1+ (1.0,0.0) [0.0|7] ""  Vector__XXX
 SG_ BM_WBA_Warnblinken : 48|1@1+ (1.0,0.0) [0.0|1] ""  Vector__XXX
 SG_ SAL_RHP_Blinken_Status : 49|3@1+ (1.0,0.0) [0.0|7] ""  Vector__XXX
 SG_ SAL_RHP_Warnblinken : 52|1@1+ (1.0,0.0) [0.0|1] ""  Vector__XXX

BO_ 2589283664 BMS_24: 8 Gateway_Max
 SG_ BMS_Balancing_Aktiv : 14|2@1+ (1.0,0.0) [0.0|3] ""  Vector__XXX
 SG_ BMS_Ladevorgang_aktiv : 16|1@1+ (1.0,0.0) [0.0|1] ""  ZR_MIB_TOP_ab_Gen3
 SG_ BMS_RIso_Ext : 17|12@1+ (5,0) [0|20465] "Unit_KiloOhm"  Vector__XXX
 SG_ BMS_Min_Ladezustand : 29|11@1+ (0.05,0) [0.00|100.00] "Unit_PerCent"  Vector__XXX
 SG_ BMS_Max_Energie : 40|13@1+ (40,0) [0|327400] "Unit_WattHour"  Vector__XXX
 SG_ BMS_Max_Ladezustand : 53|11@1+ (0.05,0) [0.00|100.00] "Unit_PerCent"  Vector__XXX

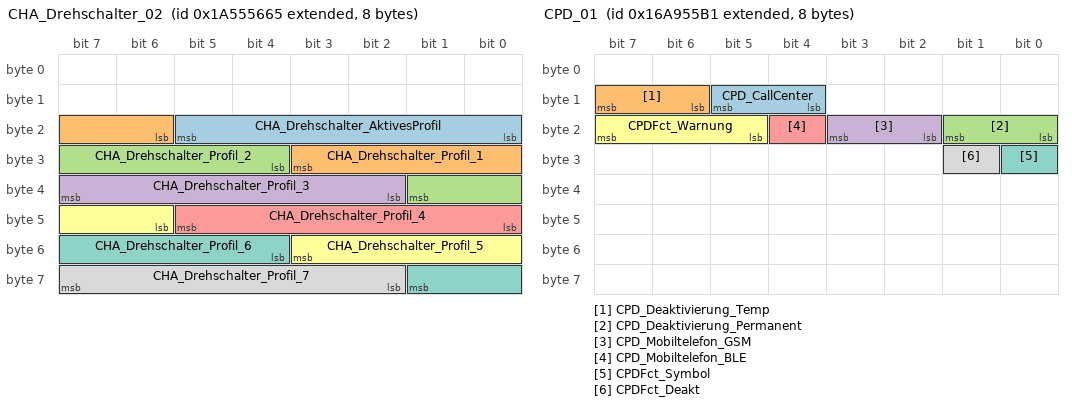
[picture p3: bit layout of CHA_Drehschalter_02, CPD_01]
BO_ 2589283941 CHA_Drehschalter_02: 8 Gateway_Max
 SG_ CHA_Drehschalter_AktivesProfil : 16|6@1+ (1.0,0.0) [0.0|63] ""  BedienDisp_mi,BedienDisp_vo_mi
 SG_ CHA_Drehschalter_Profil_1 : 22|6@1+ (1.0,0.0) [0.0|63] ""  BedienDisp_mi,BedienDisp_vo_mi
 SG_ CHA_Drehschalter_Profil_2 : 28|6@1+ (1.0,0.0) [0.0|63] ""  BedienDisp_mi,BedienDisp_vo_mi
 SG_ CHA_Drehschalter_Profil_3 : 34|6@1+ (1.0,0.0) [0.0|63] ""  BedienDisp_mi,BedienDisp_vo_mi
 SG_ CHA_Drehschalter_Profil_4 : 40|6@1+ (1.0,0.0) [0.0|63] ""  BedienDisp_mi,BedienDisp_vo_mi
 SG_ CHA_Drehschalter_Profil_5 : 46|6@1+ (1.0,0.0) [0.0|63] ""  BedienDisp_mi,BedienDisp_vo_mi
 SG_ CHA_Drehschalter_Profil_6 : 52|6@1+ (1.0,0.0) [0.0|63] ""  BedienDisp_mi,BedienDisp_vo_mi
 SG_ CHA_Drehschalter_Profil_7 : 58|6@1+ (1.0,0.0) [0.0|63] ""  BedienDisp_mi,BedienDisp_vo_mi

BO_ 902 Charisma_03: 8 Gateway_Max
 SG_ CHA_Charisma_Taste2_LED : 0|2@1+ (1.0,0.0) [0.0|3] ""  Vector__XXX
 SG_ CHA_ReqPrgDispSetup : 2|4@1+ (1.0,0.0) [0.0|15] ""  Vector__XXX
 SG_ CHA_Current_Mode_FPA : 6|6@1+ (1.0,0.0) [0.0|63] ""  ZR_MIB_OPTION_ab_Gen3
 SG_ CHA_Eco_Charisma_LED : 12|2@1+ (1.0,0.0) [0.0|3] ""  Vector__XXX
 SG_ CHA_Fahrer_Umschaltung : 14|1@1+ (1.0,0.0) [0.0|1] ""  Vector__XXX
 SG_ CHA_EV_LED : 15|1@1+ (1.0,0.0) [0.0|1] ""  Vector__XXX
 SG_ CHA_Ziel_FahrPr_AMB : 16|4@1+ (1.0,0.0) [0.0|15] ""  Vector__XXX
 SG_ CHA_Ziel_FahrPr_IVB : 20|4@1+ (1.0,0.0) [0.0|15] ""  Vector__XXX
 SG_ CHA_Kombi_Texte : 24|4@1+ (1.0,0.0) [0.0|15] ""  Vector__XXX
 SG_ CHA_Ziel_FahrPr_KL : 28|4@1+ (1.0,0.0) [0.0|15] ""  Vector__XXX
 SG_ CHA_Ziel_FahrPr_HSP : 32|4@1+ (1.0,0.0) [0.0|15] ""  Vector__XXX
 SG_ CHA_StCurProfDft : 36|2@1+ (1.0,0.0) [0.0|3] ""  Vector__XXX
 SG_ CHA_Ziel_FahrPr_RWB : 40|4@1+ (1.0,0.0) [0.0|15] ""  Vector__XXX
 SG_ CHA_Ziel_FahrPr_03_01 : 44|4@1+ (1.0,0.0) [0.0|15] ""  Vector__XXX
 SG_ CHA_Ziel_FahrPr_03_02 : 48|4@1+ (1.0,0.0) [0.0|15] ""  Vector__XXX
 SG_ CHA_Current_Mode : 52|4@1+ (1.0,0.0) [0.0|15] ""  Vector__XXX
 SG_ CHA_Charge_LED : 57|1@1+ (1.0,0.0) [0.0|1] ""  Vector__XXX
 SG_ CHA_Offroad_LED : 58|2@1+ (1.0,0.0) [0.0|3] ""  Vector__XXX
 SG_ CHA_Kombi_Texte_02 : 60|4@1+ (1.0,0.0) [0.0|15] ""  Vector__XXX

BO_ 2527679921 CPD_01: 8 Gateway_Max
 SG_ CPD_CallCenter : 12|2@1+ (1.0,0.0) [0.0|3] ""  Vector__XXX
 SG_ CPD_Deaktivierung_Temp : 14|2@1+ (1.0,0.0) [0.0|3] ""  Vector__XXX
 SG_ CPD_Deaktivierung_Permanent : 16|2@1+ (1.0,0.0) [0.0|3] ""  Vector__XXX
 SG_ CPD_Mobiltelefon_GSM : 18|2@1+ (1.0,0.0) [0.0|3] ""  Vector__XXX
 SG_ CPD_Mobiltelefon_BLE : 20|1@1+ (1.0,0.0) [0.0|1] ""  Vector__XXX
 SG_ CPDFct_Warnung : 21|3@1+ (1.0,0.0) [0.0|7] ""  Vector__XXX
 SG_ CPDFct_Symbol : 24|1@1+ (1.0,0.0) [0.0|1] ""  Vector__XXX
 SG_ CPDFct_Deakt : 25|1@1+ (1.0,0.0) [0.0|1] ""  ZR_MIB_OPTION_ab_Gen3

BO_ 2549880334 DIA_ABT_1_Req: 8 Gateway_Max
 SG_ DIA_ABT_1_Req_Data : 0|64@1+ (1.0,0.0) [0.0|18446744073709551615] ""  ICC_IO_Node,ZR_MIB_EINSTIEG_ab_Gen3,ZR_MIB_OPTION_ab_Gen3

BO_ 2550011406 DIA_ABT_1_Resp: 8 ICC_IO_Node
 SG_ DIA_ABT_1_Resp_Data : 0|64@1+ (1.0,0.0) [0.0|18446744073709551615] ""  Gateway_Max

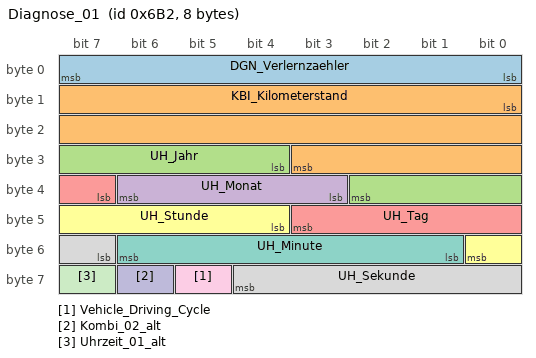
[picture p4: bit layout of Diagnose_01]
BO_ 1714 Diagnose_01: 8 Gateway_Max
 SG_ DGN_Verlernzaehler : 0|8@1+ (1,0) [0|254] ""  BedienDisp_mi,BedienDisp_vo_mi,ConMod_CD,DashCAM,ICC_IO_Node,LSH,OCU,RDK_RS3,STH,ZR_MIB_EINSTIEG_ab_Gen3,ZR_MIB_OPTION_ab_Gen3,ZR_MIB_TOP_ab_Gen3
 SG_ KBI_Kilometerstand : 8|20@1+ (1,0) [0|1048573] "Unit_KiloMeter"  BedienDisp_mi,BedienDisp_vo_mi,ConMod_CD,DashCAM,ICC_IO_Node,LSH,OCU,RDK_RS3,STH,ZR_MIB_EINSTIEG_ab_Gen3,ZR_MIB_OPTION_ab_Gen3,ZR_MIB_TOP_ab_Gen3
 SG_ UH_Jahr : 28|7@1+ (1,2000) [2000|2127] "Unit_Year"  BedienDisp_mi,BedienDisp_vo_mi,ConMod_CD,DashCAM,ICC_IO_Node,LSH,OCU,RDK_RS3,STH,ZR_MIB_EINSTIEG_ab_Gen3,ZR_MIB_OPTION_ab_Gen3,ZR_MIB_TOP_ab_Gen3
 SG_ UH_Monat : 35|4@1+ (1,0) [1|12] "Unit_Month"  BedienDisp_mi,BedienDisp_vo_mi,ConMod_CD,DashCAM,ICC_IO_Node,LSH,OCU,RDK_RS3,STH,ZR_MIB_EINSTIEG_ab_Gen3,ZR_MIB_OPTION_ab_Gen3,ZR_MIB_TOP_ab_Gen3
 SG_ UH_Tag : 39|5@1+ (1,0) [1|31] "Unit_Day"  BedienDisp_mi,BedienDisp_vo_mi,ConMod_CD,DashCAM,ICC_IO_Node,LSH,OCU,RDK_RS3,STH,ZR_MIB_EINSTIEG_ab_Gen3,ZR_MIB_OPTION_ab_Gen3,ZR_MIB_TOP_ab_Gen3
 SG_ UH_Stunde : 44|5@1+ (1,0) [0|23] "Unit_Hours"  BedienDisp_mi,BedienDisp_vo_mi,ConMod_CD,DashCAM,ICC_IO_Node,LSH,OCU,RDK_RS3,STH,ZR_MIB_EINSTIEG_ab_Gen3,ZR_MIB_OPTION_ab_Gen3,ZR_MIB_TOP_ab_Gen3
 SG_ UH_Minute : 49|6@1+ (1,0) [0|59] "Unit_Minut"  BedienDisp_mi,BedienDisp_vo_mi,ConMod_CD,DashCAM,ICC_IO_Node,LSH,OCU,RDK_RS3,STH,ZR_MIB_EINSTIEG_ab_Gen3,ZR_MIB_OPTION_ab_Gen3,ZR_MIB_TOP_ab_Gen3
 SG_ UH_Sekunde : 55|6@1+ (1,0) [0|59] "Unit_Secon"  BedienDisp_mi,BedienDisp_vo_mi,ConMod_CD,DashCAM,ICC_IO_Node,LSH,OCU,RDK_RS3,STH,ZR_MIB_EINSTIEG_ab_Gen3,ZR_MIB_OPTION_ab_Gen3,ZR_MIB_TOP_ab_Gen3
 SG_ Vehicle_Driving_Cycle : 61|1@1+ (1.0,0.0) [0.0|1] ""  ConMod_CD,ICC_IO_Node,OCU,ZR_MIB_EINSTIEG_ab_Gen3,ZR_MIB_OPTION_ab_Gen3,ZR_MIB_TOP_ab_Gen3
 SG_ Kombi_02_alt : 62|1@1+ (1.0,0.0) [0.0|1] ""  ConMod_CD,DashCAM,ICC_IO_Node,LSH,OCU,RDK_RS3,STH,ZR_MIB_EINSTIEG_ab_Gen3,ZR_MIB_OPTION_ab_Gen3,ZR_MIB_TOP_ab_Gen3
 SG_ Uhrzeit_01_alt : 63|1@1+ (1.0,0.0) [0.0|1] ""  ConMod_CD,DashCAM,ICC_IO_Node,LSH,OCU,RDK_RS3,STH,ZR_MIB_EINSTIEG_ab_Gen3,ZR_MIB_OPTION_ab_Gen3,ZR_MIB_TOP_ab_Gen3

BO_ 851 DiETa_01: 8 Gateway_Max
 SG_ DiETas_01_CRC : 0|8@1+ (1,0) [0|255] ""  Vector__XXX
 SG_ DiETas_01_BZ : 8|4@1+ (1,0) [0|15] ""  Vector__XXX
 SG_ DiETa_Reserve_Byte2_4 : 12|1@1+ (1.0,0.0) [0.0|1] ""  Vector__XXX
 SG_ DiETa_Status : 13|2@1+ (1.0,0.0) [0.0|3] ""  Vector__XXX
 SG_ DiETa_ResponseError : 15|1@1+ (1.0,0.0) [0.0|1] ""  Vector__XXX
 SG_ DiETa_Car : 16|2@1+ (1.0,0.0) [0.0|3] ""  ZR_MIB_EINSTIEG_ab_Gen3,ZR_MIB_OPTION_ab_Gen3
 SG_ DiETa_Klima : 18|2@1+ (1.0,0.0) [0.0|3] ""  Vector__XXX
 SG_ DiETa_Mode : 20|2@1+ (1.0,0.0) [0.0|3] ""  Vector__XXX
 SG_ DiETa_Parken : 22|2@1+ (1.0,0.0) [0.0|3] ""  Vector__XXX
 SG_ DiETa_FSH_Taste : 24|2@1+ (1.0,0.0) [0.0|3] ""  Vector__XXX
 SG_ DiETa_HSH_Taste : 26|2@1+ (1.0,0.0) [0.0|3] ""  Vector__XXX
 SG_ DiETa_Warnblink_Taste : 28|2@1+ (1.0,0.0) [0.0|3] ""  Vector__XXX
 SG_ DiETa_FAS_Stufe : 30|2@1+ (1.0,0.0) [0.0|3] ""  Vector__XXX
 SG_ DiETa_PAO_ON_Status : 32|2@1+ (1.0,0.0) [0.0|3] ""  Vector__XXX
 SG_ DiETa_PAO_OFF_Status : 34|2@1+ (1.0,0.0) [0.0|3] ""  Vector__XXX
 SG_ DiETa_Defrost_Taste : 36|2@1+ (1.0,0.0) [0.0|3] ""  Vector__XXX
 SG_ DiETa_Mode2 : 38|2@1+ (1.0,0.0) [0.0|3] ""  Vector__XXX
 SG_ DiETa_Lock_Unlock_Taste : 40|3@1+ (1.0,0.0) [0.0|7] ""  Vector__XXX
 SG_ DiETa_Mode_roh : 43|1@1+ (1.0,0.0) [0.0|1] ""  Vector__XXX
 SG_ ESP_Off_Taster : 44|2@1+ (1.0,0.0) [0.0|3] ""  Vector__XXX
 SG_ DiETa_Reserve_Byte6_6 : 46|2@1+ (1.0,0.0) [0.0|3] ""  Vector__XXX
 SG_ DiETa_Touch_Event : 48|4@1+ (1.0,0.0) [0.0|15] ""  ZR_MIB_EINSTIEG_ab_Gen3,ZR_MIB_OPTION_ab_Gen3,ZR_MIB_TOP_ab_Gen3
 SG_ DiETa_Reserve_Byte7_4 : 52|4@1+ (1.0,0.0) [0.0|15] ""  Vector__XXX
 SG_ DiETa_Reserve_Byte8 : 56|8@1+ (1.0,0.0) [0.0|255] ""  Vector__XXX

BO_TX_BU_ 2536735504 :ZR_MIB_EINSTIEG_ab_Gen3,ZR_MIB_OPTION_ab_Gen3;
BO_TX_BU_ 2536706560 :ZR_MIB_EINSTIEG_ab_Gen3,ZR_MIB_OPTION_ab_Gen3,ZR_MIB_TOP_ab_Gen3;
BO_TX_BU_ 2536706048 :ZR_MIB_EINSTIEG_ab_Gen3,ZR_MIB_OPTION_ab_Gen3,ZR_MIB_TOP_ab_Gen3;
BO_TX_BU_ 2536710144 :ZR_MIB_EINSTIEG_ab_Gen3,ZR_MIB_OPTION_ab_Gen3,ZR_MIB_TOP_ab_Gen3;
BO_TX_BU_ 2536736000 :ZR_MIB_EINSTIEG_ab_Gen3,ZR_MIB_OPTION_ab_Gen3;
BO_TX_BU_ 2536720896 :ZR_MIB_EINSTIEG_ab_Gen3,ZR_MIB_OPTION_ab_Gen3,ZR_MIB_TOP_ab_Gen3;
BO_TX_BU_ 2536708608 :ZR_MIB_EINSTIEG_ab_Gen3,ZR_MIB_OPTION_ab_Gen3,ZR_MIB_TOP_ab_Gen3;
BO_TX_BU_ 2536712464 :ZR_MIB_OPTION_ab_Gen3,ZR_MIB_TOP_ab_Gen3;
BO_TX_BU_ 2536712465 :ZR_MIB_OPTION_ab_Gen3,ZR_MIB_TOP_ab_Gen3;
BO_TX_BU_ 2536712208 :ZR_MIB_EINSTIEG_ab_Gen3,ZR_MIB_OPTION_ab_Gen3,ZR_MIB_TOP_ab_Gen3;
BO_TX_BU_ 2536712209 :ZR_MIB_EINSTIEG_ab_Gen3,ZR_MIB_OPTION_ab_Gen3,ZR_MIB_TOP_ab_Gen3;
BO_TX_BU_ 2536726273 :ZR_MIB_EINSTIEG_ab_Gen3,ZR_MIB_OPTION_ab_Gen3,ZR_MIB_TOP_ab_Gen3;
BO_TX_BU_ 2536715776 :ZR_MIB_EINSTIEG_ab_Gen3,ZR_MIB_OPTION_ab_Gen3;
BO_TX_BU_ 2536706304 :ZR_MIB_EINSTIEG_ab_Gen3,ZR_MIB_OPTION_ab_Gen3,ZR_MIB_TOP_ab_Gen3;
BO_TX_BU_ 2536710400 :ZR_MIB_EINSTIEG_ab_Gen3,ZR_MIB_OPTION_ab_Gen3,ZR_MIB_TOP_ab_Gen3;
BO_TX_BU_ 2536705024 :ZR_MIB_EINSTIEG_ab_Gen3,ZR_MIB_OPTION_ab_Gen3,ZR_MIB_TOP_ab_Gen3;
BO_TX_BU_ 2550011406 :ICC_IO_Node,ZR_MIB_EINSTIEG_ab_Gen3,ZR_MIB_OPTION_ab_Gen3;
CM_ BO_ 1635 "DLC=8 ab D4 gültig";
CM_ BO_ 870 "Nur die Kombination des statischen und toggelnden Signals ergibt den Blinktakt für die Hell & Dunkelphase";
CM_ BO_ 902 "ab MQB 7.2.1";

CM_ SG_ 2536735504 BAP_SecEvents2_FSG_01_Header "Security Events für IDS (Intrusion Detection System)
LSG ID - 131dez (SecurityEvents2)";

CM_ SG_ 2536706048 BAP_Sitz1_ASG_01_Header "Sitz1 Anzeigesteuergeraet";

CM_ SG_ 2536706049 BAP_Sitz1_ASG_02_Header "Sitz1 Anzeigesteuergeraet";

CM_ SG_ 2536736000 BAP_SLCView_ASG_01_Header "SideLeaveCarView Anzeigesteuergeraet
LCU ID - 133dez";

CM_ SG_ 2536736016 BAP_SLCView_FSG_01_Header "SideLeaveCarView Funktionssteuergeraet
LCU ID - 133dez";

CM_ SG_ 2536720896 BAP_Statistics_ASG_01_Header "Statistics Anzeigesteuergeraet";

CM_ SG_ 2536720912 BAP_Statistics_FSG_01_Header "Statistics Funktionssteuergeraet";

CM_ SG_ 2536721152 BAP_Sunroof_ASG_01_Header "BAP Anzeige für SAD vorderes Dachelement.";

CM_ SG_ 2536721168 BAP_Sunroof_FSG_01_Header "BAP Anzeige für SAD vorderes Dachelement.";

CM_ SG_ 2536708610 BAP_SWA_ASG_03_Header "SWA Anzeigesteuergeraet";

CM_ SG_ 2536712448 BAP_Telefon2_ASG_01_Header "MQB AUDI: keine Verwendung im ZR Entry";

CM_ SG_ 2536712449 BAP_Telefon2_ASG_02_Header "Telefon2 Anzeigesteuergeraet
MMI <-> Head-Up Display";

CM_ SG_ 2536712464 BAP_Telefon2_FSG_01_Header "MQB AUDI: keine Verwendung im ZR Entry";

CM_ SG_ 2536712465 BAP_Telefon2_FSG_02_Header "BAP Strecke Telefon zum Kombi";

CM_ SG_ 2536712192 BAP_Telefon_ASG_01_Header "MQB AUDI: keine Verwendung im ZR Entry";

CM_ SG_ 2536712193 BAP_Telefon_ASG_02_Header "MQB AUDI: keine Verwendung im ZR Entry";

CM_ SG_ 2536712194 BAP_Telefon_ASG_03_Header "Telefon Anzeigesteuergeraet
Head-Up";

CM_ SG_ 2536712195 BAP_Telefon_ASG_04_Header "Telefon Anzeigesteuergeraet
MMI<->Head-Up Display";

CM_ SG_ 2536712208 BAP_Telefon_FSG_01_Header "MQB AUDI: keine Verwendung im ZR Entry";

CM_ SG_ 2536712209 BAP_Telefon_FSG_02_Header "MQB AUDI: keine Verwendung im ZR Entry";

CM_ SG_ 2536726273 BAP_TPA_ASG_02_Header "Parktrajektorie Anzeigesteuergerät";

CM_ SG_ 2536726288 BAP_TPA_FSG_01_Header "Parktrajektorie Funktionssteuergeraet";

CM_ SG_ 2536710403 BAP_VZA_ASG_04_Header "VZA Anzeigesteuergeraet";

CM_ SG_ 2536705025 BAP_Wiper_ASG_02_Header "Wiper Anzeigesteuergeraet";

CM_ SG_ 1626 APS_Tongeber_defekt "Status APS-Tongeber zur HMI-Ansteuerng der RCTA-Funktion";
CM_ SG_ 1626 BCM1_AFS_Lampe "Ansteuerung der AFS-Fehlermeldung im Kombi";
CM_ SG_ 1626 BCM1_EasyEntry_Status "Status EasyEntry für Lenksäule (wird auch von IVB verwendet)";
CM_ SG_ 1626 BCM1_Fahrlicht_Hinweis "Signal zum Kombi um den Hinweis 'Bitte Fahrlicht einschalten' anzufordern";
CM_ SG_ 1626 BCM1_Hinweis_Lichtnachlauf "Signal dient der Anzeige eines aktiven Lichtnachlaufes beim automatischen Abschalten der Klemme S und Klemme 15. Der Lichtnachlauf wird gestartet, wenn die Klemme 15 bei aktivem Fahrlicht deaktiviert wird.";
CM_ SG_ 1626 BCM1_Kl_15_HW_erkannt "Erkennung Klemme 15 (Hardware) vom BCM1
";
CM_ SG_ 1626 BCM1_Kl_15_Sig_HW_erkannt "Erkennung Klemme 15 Signal (Hardware) vom BCM1";
CM_ SG_ 1626 BCM1_LDS_Stellung "Das Signal wird vom AFS / LWR Steuergerät empfangen und dient der Verifizierung der Lichtdrehschalterstellung. Intelligente Lichtfunktionen wie dyn. KL und gleitende Leuchtweite (GLW) nur bei LDS = 'AUTO'.";
CM_ SG_ 1626 BCM1_Lenksaeule_aktiv "Lenksaeulenverstellung aktiv";
CM_ SG_ 1626 BCM1_Licht_Warn "Lichtwarnung";
CM_ SG_ 1626 BCM1_Lichtwarn_Texte "Anforderung von Lichtwarnungen vom BCM1 zum Kombi
MLB: nur Werte 0..2";
CM_ SG_ 1626 BCM1_MH_Schalter "Motorhaubenkontakt";
CM_ SG_ 1626 BCM1_MH_WIV_Schalter "Bewerteter Motorhaubenkontakt fuer WIV";
CM_ SG_ 1626 BCM1_NV_Taster "BCM1_NV_Taster gibt an, ob der NightVision-Taster im Lichtdrehschalter-Modul aktuell betaetigt wird.";
CM_ SG_ 1626 BCM1_Reisemodus_Texte "Ansteuerung der Reisemodus-Texte im Kombi";
CM_ SG_ 1626 BCM1_Rueckfahrlicht_Schalter "Rückfahrlichtschalter
ab MQB/ MLBevo: Die Ganginformation wird unentprellt übertragen, im AT-Getriebe wird evtl. kurzzeitig der R-Gang angezeigt. Eine Entprellung muß im Empfänger erfolgen (typisch 400ms).";
CM_ SG_ 1626 BCM1_Spannungs_Anf "Forderung des BCM1-SG's zur Spannungsanhebung.";
CM_ SG_ 1626 BCM1_Valet_Parking_Taster "Valet Parking Taster ";
CM_ SG_ 1626 BCM1_Warnblink_Taster "Warnblinktaster";
CM_ SG_ 1626 BCM_Anf_AAW_MoLaWa "Signal zur Anforderung der Antrieb-Aktiv-Warnung und Motorlaufwarnung. Die Berechnung erfolgt im BCM. Die Ausgabe der Warnungen wird vom Kombiinstrument realisiert";
CM_ SG_ 1626 BCM_Bremsbelag_Sensor "Sensorsignal der Stromschleife  für Bremsbelagverschleiß aktuell, entstört, unbewertet";
CM_ SG_ 1626 BCM_Bremsfluessigkeit_Sensor "Kontaktsignal des Sensorschalters für die Bremsflüssigkeitsreserve aktuell, entstört, unbewertet";
CM_ SG_ 1626 BCM_Charisma_Taste2 "Betätigung der Charisma-Taste 2";
CM_ SG_ 1626 BCM_Eco_Charisma_Taste "Betätigung Taster ECO alias BlueKey oder Charisma";
CM_ SG_ 1626 BCM_Handbremse_Hinweis "Infotext fuer das Kombiinstrument zur Oeffnung der elektr. Heckklappe.";
CM_ SG_ 1626 BCM_HBFS_EOE_aktiv "Elektrisch-Oeffnen-Motor aktiv";
CM_ SG_ 1626 BCM_HDF_betaetigt "Betätigung Taster für Heckdeckelfernentriegelung in Mittelkonsole";
CM_ SG_ 1626 BCM_HFS_EOE_aktiv "Elektrisch-Oeffnen-Motor aktiv";
CM_ SG_ 1626 BCM_Hybrid_StartStopp_Taste "Betaetigung Taster 'Hybrid' oder alternativ Taster 'Start/Stopp Deaktivierung', je nach Verbau";
CM_ SG_ 1626 BCM_Hybrid_StSt_Taste_Fehler "Fehlerflag, wenn Tasterdiagnose im BCM für den StSt-Taster anschlägt.";
CM_ SG_ 1626 BCM_Kuehlmittel_Sensor "Signal der Sensorelektroden für die Kühlmittelreserve aktuell, entstört, bewertet (OK/Mangel)";
CM_ SG_ 1626 BCM_Kuehlmittel_Sensor_02 "Signal der zweiten Sensorelektroden für die Kühlmittelreserve aktuell, entstört, bewertet (OK/Mangel)";
CM_ SG_ 1626 BCM_Offroad_Taste "Betätigung der Offroad-Taste";
CM_ SG_ 1626 BCM_ValetTaster_Fkts_LED "Im MQB beschreibt das Signal nur den Zustand der Funktion Valet Parking (aktiv/ inaktiv)
Im MLBevo wird über das Signal zusätzlich die ValetTaster_Fkts_LED (an/ aus) gesteuert";
CM_ SG_ 1626 BCM_Waehlhebel_P_Hinweis "Infotext NAR für die Vorbedingung 'Waehlhebel in P' für Öffnen der Heckklappe über den Fahrerrauminnentaster.";
CM_ SG_ 1626 BCM_Waschwasser_Sensor "Signal der Sensorelektroden für die Waschwasserreserve aktuell, entstört, bewertet (OK/Mangel)";
CM_ SG_ 1626 DWA_Alarmquelle "Signalisiert den Auslösegrund der DWA";
CM_ SG_ 1626 DWA_Einschraenkung "Signalisiert Fehler der DWA";
CM_ SG_ 1626 Gong_TFL_Umschaltung "Aktivierung / Deaktivierung des TFL per Affengriff wird mit einem Gong im Kombi quittiert.";
CM_ SG_ 1626 LRH_Taster "Tasterbetätigung Lenkradheizung";

CM_ SG_ 2527679637 BCM_anf_VLW "Über dieses Signal wird die vom BCM errechnete Verlassenswarnung sowie die Meldung eines aktiven Rollfaehigkeitsmodus zur Ausgabe durch das Kombinstrument angefordert.";
CM_ SG_ 2527679637 BCM_Defrost_Taste "Defrost AN/AUS und Status";
CM_ SG_ 2527679637 BCM_FAS_Taster "Betätigung des FAS-Tasters Schalterleiste.";
CM_ SG_ 2527679637 BCM_FSH_Taste "Frontscheibenheizung AN/AUS und Status";
CM_ SG_ 2527679637 BCM_HSH_Taste "Heckscheibenheizung AN/AUS und Status";
CM_ SG_ 2527679637 BCM_LTM_Allwetterl_Status "Allwetterlicht Status zur Anzeige im Allwetterlicht-PopUp";
CM_ SG_ 2527679637 BCM_LTM_Nebell_Status "Nebellicht Status zur Anzeige im Nebellicht-PopUp";
CM_ SG_ 2527679637 BCM_LTM_Nebelschluss_Status "Nebelschlusslicht Status zur Anzeige im Nebelschlusslicht-PopUp";
CM_ SG_ 2527679637 BCM_LTM_PopUp_Anf "Anforderung der entsprechenden Anzeige im Kombi bei Aussenlichtsteuerung über LTM (LichtTastenModul)";
CM_ SG_ 2527679637 BCM_LTM_PopUp_Inhalt "Definition Inhalt des PopUps zur Aussenlichtbedienung";
CM_ SG_ 2527679637 BCM_LTM_PopUp_Status "Auswahl der aktiven Aussenlichtfunktion im LTM PopUp";
CM_ SG_ 2527679637 BCM_LTM_PopUp_Texte "Anforderung Kombi-Texte bei Bedienung Aussenlicht über LTM (LichtTastenModul)";
CM_ SG_ 2527679637 CPD_Warnung "Ansteuerung einer Warnung im Kombi/ iID mit Ton oder ohne Ton durch die Fkt. ChildPresenceDetection";
CM_ SG_ 2527679637 LiSi_Touch_Event "Touch_Events für Informationen einer Funktionsauslösung auf der LiSi, welches dann für bspw. ein akustiches Signal zentral umgesetzt werden können.";
CM_ SG_ 2527679637 LTMs_01_alt "Veraltet-Bit für den LIN-Frame LTMs_01";
CM_ SG_ 2527679637 MiKo_Tisch_Positionswarnung "Positionswarnung des Tisches in der Mittelkonsole";

CM_ SG_ 2463978607 BCM_RGB_Blau "Farbanteil 'Blau'";
CM_ SG_ 2463978607 BCM_RGB_Dimmrampe "Vorgabe 'Dimmzeit' für RGB-Slave";
CM_ SG_ 2463978607 BCM_RGB_Dimmzeit_Zeitbasis "Umschaltung der Zeitbasis für die Berechnung der Dimmzeit zwischen 250ms (Altwert, log. Signalwert: 1) und 50ms (log. Signalwert: 0)";
CM_ SG_ 2463978607 BCM_RGB_Gruen "Farbanteil 'Grün'";
CM_ SG_ 2463978607 BCM_RGB_Intensitaet "Intensität für RGB-Slave";
CM_ SG_ 2463978607 BCM_RGB_Normierung_Intensitaet "Normierung der Intensität für die RGB-Slaves:
0 = keine Normierung
1 = Normierung";
CM_ SG_ 2463978607 BCM_RGB_Rot "Farbanteil 'Rot'";

CM_ SG_ 2527679781 LINDa_HL_SR3_Touch_Event "Touch_Events für Informationen einer Funktionsauslösung auf dem LINDa (hinten links SR3) , welches dann für bspw. ein akustisches Signal zentral umgesetzt werden können.";
CM_ SG_ 2527679781 LINDa_HL_Touch_Event "Touch_Events für Informationen einer Funktionsauslösung auf dem LINDa, welches dann für bspw. ein akustisches Signal zentral umgesetzt werden können.";
CM_ SG_ 2527679781 LINDa_HR_SR3_Touch_Event "Touch_Events für Informationen einer Funktionsauslösung auf dem LINDa (hinten rechts SR3), welches dann für bspw. ein akustisches Signal zentral umgesetzt werden können.";
CM_ SG_ 2527679781 LINDa_HR_Touch_Event "Touch_Events für Informationen einer Funktionsauslösung auf dem LINDa, welches dann für bspw. ein akustisches Signal zentral umgesetzt werden können.";

CM_ SG_ 2463978882 BedienDisp_hbfs_01_BZ "4bit Botschaftszähler, wird mit jeder Sendebotschaft inkrementiert";
CM_ SG_ 2463978882 BedienDisp_hbfs_01_CRC "Für MLB:
Berechnung siehe Lastenheft 'Kommunikationsabsicherung für FlexRay und CAN'
Ab MQB und MLBevo:
Berechnung siehe Lastenheft 'End-to-End Kommunikationsabsicherung'

Endwerte siehe Begleitdokument 'S-PDU Kennungsfolgen'";
CM_ SG_ 2463978882 BedienDisp_hbfs_control_vol "HMI Volume Steuerung via MCC4 HBFS Touch Display";
CM_ SG_ 2463978882 BedienDisp_hbfs_control_vol_02 "HMI Volume Wertebereich via MCC4 HBFS Touch Display";
CM_ SG_ 2463978882 BedienDisp_hbfs_fader "HMI Fader/Soundfokus Steuerung via MCC4 HBFS Touch Display

Fader_Front
Fader_Rear";
CM_ SG_ 2463978882 BedienDisp_hbfs_Lordose_hoch "Anforderung MCC4 Lordosenwölbung nach oben zu verschieben.";
CM_ SG_ 2463978882 BedienDisp_hbfs_Lordose_runter "Anforderung MCC4 Lordosenwölbung nach unten zu verschieben.";
CM_ SG_ 2463978882 BedienDisp_hbfs_Lordose_vor "Anforderung MCC4 Lordosenwölbung pneumatisch zu vergrößern.";
CM_ SG_ 2463978882 BedienDisp_hbfs_Lordose_zurueck "Anforderung MCC4 Lordosenwölbung zu verkleinern.";
CM_ SG_ 2463978882 BedienDisp_hbfs_sound "Source of Audio signal";
CM_ SG_ 2463978882 BedienDisp_hbfs_sound_fokus "HMI Sound Fokus Zonen via MCC4 HBFS Touch Display";
CM_ SG_ 2463978882 BedienDisp_hbfs_surround "HMI Surround Steuerung via MCC4 HBFS Touch Display";
CM_ SG_ 2463978882 BedienDisp_hbfs_surround_02 "HMI Surround Wertebereich via MCC4 HBFS Touch Display";
CM_ SG_ 2463978882 BedienDisp_hbfs_touch "Touchsignale MCC4 Toch-ABT HBFS";
CM_ SG_ 2463978882 BedienDisp_hbfs_UseCase_Pos "Anforderung MCC Sitz UseCaseposition zu verstellen";
CM_ SG_ 2463978882 BedienDisp_HBFSFo_Bestaetigung "HMI Bestätigung der Warnung nach Softstop Lehnenverstellung";
CM_ SG_ 2463978882 BedienDisp_HBFSFo_Stoerung "Störung des MCC4-ABT an Kombi und Sitz";

CM_ SG_ 2463978886 BedienDisp_hbfs_02_BZ "4bit Botschaftszähler, wird mit jeder Sendebotschaft inkrementiert";
CM_ SG_ 2463978886 BedienDisp_hbfs_02_CRC "Für MLB:
Berechnung siehe Lastenheft 'Kommunikationsabsicherung für FlexRay und CAN'
Ab MQB und MLBevo:
Berechnung siehe Lastenheft 'End-to-End Kommunikationsabsicherung'

Endwerte siehe Begleitdokument 'S-PDU Kennungsfolgen'";
CM_ SG_ 2463978886 BedienDisp_hbfs_BF_Hoehe "Anforderung MCC4 Sitz Höhenposition Beifahrersitz zu verstellen";
CM_ SG_ 2463978886 BedienDisp_hbfs_BF_Laengs "Anforderung MCC4 Sitz Längsposition Beifahrersitz zu verstellen";
CM_ SG_ 2463978886 BedienDisp_hbfs_BF_Lehne "Anforderung MCC4 Sitz Lehnenposition Beifahrersitz zu verstellen";
CM_ SG_ 2463978886 BedienDisp_hbfs_Cargo_Pos "MCC4 Anforderung Cargoposition anzufahren";
CM_ SG_ 2463978886 BedienDisp_hbfs_Komfor_Pos "Anforderung MCC4 Sitz Komfortposition zu verstellen";
CM_ SG_ 2463978886 BedienDisp_hbfs_Mem_Start "HMI Play Button für Memoryposition MCC4 anfahren";
CM_ SG_ 2463978886 BedienDisp_hbfs_Memo_Pos "Anforderung MCC4 Sitz Memoryposition zu verstellen";
CM_ SG_ 2463978886 BedienDisp_hbfs_Normal_Pos "MCC4 Anforderung Normalposition anzufahren";
CM_ SG_ 2463978886 BedienDisp_hbfs_Seat_SetReset "Anforderung MCC4 Sitz für Set und Reset der Memorybelegungen";
CM_ SG_ 2463978886 BedienDisp_hbfs_Seat_Storage "Angabe der zu speichernden MCC4 Sitzposition oder einzustellenden Memoryposition";
CM_ SG_ 2463978886 BedienDisp_hbfs_Sitz_Arm "Anforderung MCC4 Sitz Armlehnenposition zu verstellen";
CM_ SG_ 2463978886 BedienDisp_hbfs_Sitz_Bein "Anforderung MCC4 Sitz Beinauflageposition zu verstellen";
CM_ SG_ 2463978886 BedienDisp_hbfs_Sitz_Hoehe "Anforderung MCC4 Sitz Höhenposition zu verstellen";
CM_ SG_ 2463978886 BedienDisp_hbfs_Sitz_Kopf "Anforderung MCC4 Sitz Kopfstützenposition zu verstellen";
CM_ SG_ 2463978886 BedienDisp_hbfs_Sitz_Laengs "Anforderung MCC4 Sitz Längsposition zu verstellen";
CM_ SG_ 2463978886 BedienDisp_hbfs_Sitz_Lehne "Anforderung MCC4 Sitz Lehnenposition zu verstellen";
CM_ SG_ 2463978886 BedienDisp_hbfs_Sitz_Lehnekopf "Anforderung MCC4 Sitz Lehnenkopfposition zu verstellen";
CM_ SG_ 2463978886 BedienDisp_hbfs_Sitz_Neigung "Anforderung MCC4 Sitz Neigungsposition zu verstellen";
CM_ SG_ 2463978886 BedienDisp_hbfs_Sitz_Stop "Kapazitiver Stop Button MCC4 für Automatiklauf";

CM_ SG_ 2463978881 BedienDisp_hfs_01_BZ "4bit Botschaftszähler, wird mit jeder Sendebotschaft inkrementiert";
CM_ SG_ 2463978881 BedienDisp_hfs_01_CRC "Für MLB:
Berechnung siehe Lastenheft 'Kommunikationsabsicherung für FlexRay und CAN'
Ab MQB und MLBevo:
Berechnung siehe Lastenheft 'End-to-End Kommunikationsabsicherung'

Endwerte siehe Begleitdokument 'S-PDU Kennungsfolgen'";
CM_ SG_ 2463978881 BedienDisp_hfs_control_vol "HMI Volume Steuerung via MCC4 HFS Touch Display";
CM_ SG_ 2463978881 BedienDisp_hfs_control_vol_02 "HMI Volume Wertebereich via MCC4 HFS Touch Display";
CM_ SG_ 2463978881 BedienDisp_hfs_fader "HMI Fader/Soundfokus Steuerung via MCC4 HFS Touch Display

Fader_Front
Fader_Rear";
CM_ SG_ 2463978881 BedienDisp_hfs_Lordose_hoch "Anforderung MCC4 Lordosenwölbung nach oben zu verschieben.";
CM_ SG_ 2463978881 BedienDisp_hfs_Lordose_runter "Anforderung MCC4 Lordosenwölbung nach unten zu verschieben.";
CM_ SG_ 2463978881 BedienDisp_hfs_Lordose_vor "Anforderung MCC4 Lordosenwölbung pneumatisch zu vergrößern.";
CM_ SG_ 2463978881 BedienDisp_hfs_Lordose_zurueck "Anforderung MCC4 Lordosenwölbung zu verkleinern.";
CM_ SG_ 2463978881 BedienDisp_hfs_sound "Source of Audio signal";
CM_ SG_ 2463978881 BedienDisp_hfs_sound_fokus "HMI Sound Fokus Zonen via MCC4 HFS Touch Display";
CM_ SG_ 2463978881 BedienDisp_hfs_surround "HMI Surround Steuerung via MCC4 HFS Touch Display";
CM_ SG_ 2463978881 BedienDisp_hfs_surround_02 "HMI Surround Wertebereich via MCC4 HFS Touch Display";
CM_ SG_ 2463978881 BedienDisp_hfs_touch "Touchsignale MCC4 Toch-ABT HFS";
CM_ SG_ 2463978881 BedienDisp_hfs_UseCase_Pos "Anforderung MCC Sitz UseCaseposition zu verstellen";
CM_ SG_ 2463978881 BedienDisp_HFSFo_Bestaetigung "HMI Bestätigung der Warnung nach Softstop Lehnenverstellung";
CM_ SG_ 2463978881 BedienDisp_HFSFo_Stoerung "Störung des MCC4-ABT an Kombi und Sitz";

CM_ SG_ 2463978885 BedienDisp_hfs_02_BZ "4bit Botschaftszähler, wird mit jeder Sendebotschaft inkrementiert";
CM_ SG_ 2463978885 BedienDisp_hfs_02_CRC "Für MLB:
Berechnung siehe Lastenheft 'Kommunikationsabsicherung für FlexRay und CAN'
Ab MQB und MLBevo:
Berechnung siehe Lastenheft 'End-to-End Kommunikationsabsicherung'

Endwerte siehe Begleitdokument 'S-PDU Kennungsfolgen'";
CM_ SG_ 2463978885 BedienDisp_hfs_BF_Hoehe "Anforderung MCC4 Sitz Höhenposition Beifahrersitz zu verstellen";
CM_ SG_ 2463978885 BedienDisp_hfs_BF_Laengs "Anforderung MCC4 Sitz Längsposition Beifahrersitz zu verstellen";
CM_ SG_ 2463978885 BedienDisp_hfs_BF_Lehne "Anforderung MCC4 Sitz Lehnenposition Beifahrersitz zu verstellen";
CM_ SG_ 2463978885 BedienDisp_hfs_Cargo_Pos "MCC4 Anforderung Cargoposition anzufahren";
CM_ SG_ 2463978885 BedienDisp_hfs_Komfor_Pos "Anforderung MCC4 Sitz Komfortposition zu verstellen";
CM_ SG_ 2463978885 BedienDisp_hfs_Mem_Start "HMI Play Button für Memoryposition MCC4 anfahren";
CM_ SG_ 2463978885 BedienDisp_hfs_Memo_Pos "Anforderung MCC4 Sitz Memoryposition zu verstellen";
CM_ SG_ 2463978885 BedienDisp_hfs_Normal_Pos "MCC4 Anforderung Normalposition anzufahren";
CM_ SG_ 2463978885 BedienDisp_hfs_Seat_SetReset "Anforderung MCC4 Sitz für Set und Reset der Memorybelegungen";
CM_ SG_ 2463978885 BedienDisp_hfs_Seat_Storage "Angabe der zu speichernden MCC4 Sitzposition oder einzustellenden Memoryposition";
CM_ SG_ 2463978885 BedienDisp_hfs_Sitz_Arm "Anforderung MCC4 Sitz Armlehnenposition zu verstellen";
CM_ SG_ 2463978885 BedienDisp_hfs_Sitz_Bein "Anforderung MCC4 Sitz Beinauflageposition zu verstellen";
CM_ SG_ 2463978885 BedienDisp_hfs_Sitz_Hoehe "Anforderung MCC4 Sitz Höhenposition zu verstellen";
CM_ SG_ 2463978885 BedienDisp_hfs_Sitz_Kopf "Anforderung MCC4 Sitz Kopfstützenposition zu verstellen";
CM_ SG_ 2463978885 BedienDisp_hfs_Sitz_Laengs "Anforderung MCC4 Sitz Längsposition zu verstellen";
CM_ SG_ 2463978885 BedienDisp_hfs_Sitz_Lehne "Anforderung MCC4 Sitz Lehnenposition zu verstellen";
CM_ SG_ 2463978885 BedienDisp_hfs_Sitz_Lehnekopf "Anforderung MCC4 Sitz Lehnenkopfposition zu verstellen";
CM_ SG_ 2463978885 BedienDisp_hfs_Sitz_Neigung "Anforderung MCC4 Sitz Neigungsposition zu verstellen";
CM_ SG_ 2463978885 BedienDisp_hfs_Sitz_Stop "Kapazitiver Stop Button MCC4 für Automatiklauf";

CM_ SG_ 2463978863 BedienDisp_vm_Aktive_Ebene "FES 2.0 gibt die angezeigte Ebene an- Relevant fur SKODA Rotary Knob";
CM_ SG_ 2463978863 BedienDisp_vm_Control "Describes the function (values) when turning the  ring on the rotary knob..

Rotary_Up - knob is turn right side
Rotary_Down knob is turn left side";
CM_ SG_ 2463978863 BedienDisp_vm_defekt "Status vom Rotary Knob";
CM_ SG_ 2463978863 BedienDisp_vm_Function "Describes set function on rotary knob display (active function).";
CM_ SG_ 2463978863 BedienDisp_vm_Ist_Profil "Gibt das momentan dargestellte Profil an - copy for SKODA BedienDisp_vo_mi";
CM_ SG_ 2463978863 BedienDisp_vm_Press "Describes the function (values) when rotary knob is press";
CM_ SG_ 2463978863 BedienDisp_vm_Taster "Betätigungszustand  BedienDisp_vm Rotary Knob";
CM_ SG_ 2463978863 BedienDisp_vm_Touch "Touchsignale des Rotary Knob";

CM_ SG_ 1635 BEM_Anf_KL15_schalten "Abschaltempfehlung bzw. Verhinderung der automatischen Abschaltung Kl15 durch das BCM";
CM_ SG_ 1635 BEM_Batt_Ab "Batterieverbindungskontrolle:
0x0: Batterie am Bordnetz
0x1: Batterie ab erkannt";
CM_ SG_ 1635 BEM_Batteriediagnose "Anzeige von Textwarnungen";
CM_ SG_ 1635 BEM_DFM "Generatorauslastungsgrad, vom Generator über LIN an das Gateway gesandt. Das Motorsteuergerät regelt auf dieses Signal die PTC, das Energiemanagement im BSG/BCM kalkuliert die Bordnetzauslastung";
CM_ SG_ 1635 BEM_EMLIN_ungueltig "Energie-Lin - Signale sind ungültig vom Slave Batteriedatenmodul oder Generator
0 = Signale gültig
1 = Signale ungültig";
CM_ SG_ 1635 BEM_Generatordiagnose "Ansteuerung Generatorwarnleuchte im Kombi
";
CM_ SG_ 1635 BEM_HL_Kontingentierung "Leistungskontingente für Heizsysteme";
CM_ SG_ 1635 BEM_HL_Regelung_Status "Status Regelung Heizleistung
";
CM_ SG_ 1635 BEM_Ladezustand "Ladezustand der Niedervoltbatterie
";
CM_ SG_ 1635 BEM_MMI_Vorwarnung "Anzeige Vorwarnung MMI-Abschaltung (Initialisierungswert aus EEprom)
";
CM_ SG_ 1635 BEM_Red_Innengeblaese "Reduzierung Innengebläse
";
CM_ SG_ 1635 BEM_REK_aktiv "Rekuperationsfreigabe vom Energiemanagement
0x0 = keine Rekuperationsfreigabe
0x1 = Rekuperationsfreigabe";
CM_ SG_ 1635 BEM_STH_Einschaltverbot "Einschränkung Standheizung/-lüftung durch BEM: Setzt der BEM das Bit, dann darf die Standheizung nicht mehr einschalten
(Die Standheizung muss aber nicht abschalten, sondern darf weiterbrennen)
(Initialisierungswert aus EEprom)
";
CM_ SG_ 1635 BEM_STH_Zielzeit "Maximal mögliche Zeit für den Standheizungsbetrieb, um die Startfähigkeit nicht zu gefährden";
CM_ SG_ 1635 BEM_UBDM "Batteriespannung, gemessen vom Batteriedatenmodul";
CM_ SG_ 1635 BEM_UGenSoll "Sollspannungsvorgabe an den Generator, beinhaltet temperaturoptimierte Batterieladung und Rekuperation";
CM_ SG_ 1635 MIB_Stromsparmodus "Signal beschreibt die Aktivierung für den Stromsparmodus beim MIB.
Bei AUS (= 0) gibt es keine weitere Anforderung an die MIB-Komponenten.
Bei EIN (= 1) werden alle MIB Komponenten in einen Stromsparmodus versetzt.";
CM_ SG_ 1635 NVEM_Abschaltstufe "Abschaltstufe aus dem Ruheenergiemanagement
Maßnahmen des Empfängers werden im QLAH Ruhestrommanagement definiert";
CM_ SG_ 1635 NVEM_Anf_SD_schalten "Anforderung Nachlauf für den Steckdosenbetrieb
Initialisierungswert aus EEprom";
CM_ SG_ 1635 NVEM_Batterie_Service "Anforderung einer Batterie-Service - Anzeige / Anforderung an die Werkstatt über MOD";
CM_ SG_ 1635 NVEM_Freigabe_OnlineUpdate "Freigabe für Online-Update durch Energiemanagement";
CM_ SG_ 1635 NVEM_Freigabe_ORU4 "Bestätigung oder Ablehnung eines konkreten, angefragten Online Updates durch das Energiemanagements";
CM_ SG_ 1635 NVEM_Freigabe_ZusBatt_Laden "NVEM gibt die Freigabe zum Schließen des Laderelais im Ruhebetrieb (z.B. bei Verwendung eines Ladegerätes)";
CM_ SG_ 1635 NVEM_Verbraucherabsch_Anz "Information über eine Verbraucherbschaltung durch das Energiemanagement";

CM_ SG_ 2463978850 BEM_07_BZ "4bit Botschaftszähler, wird mit jeder Sendebotschaft inkrementiert";
CM_ SG_ 2463978850 BEM_07_CRC "Für MLB:
Berechnung siehe Lastenheft 'Kommunikationsabsicherung für FlexRay und CAN'
Ab MQB und MLBevo:
Berechnung siehe Lastenheft 'End-to-End Kommunikationsabsicherung'

Endwerte siehe Begleitdokument 'S-PDU Kennungsfolgen'";
CM_ SG_ 2463978850 NVEM2_VerbrZustandsAnf "Dieses Signal soll bei FuSi-relevanten Energienotsituationen die Reaktion bei den Nichtdynamischen Verbrauchern auslösen.";
CM_ SG_ 2463978850 NVEM3_Absch_SCR "Abschaltung der SCR-Heizung durch das NVEM bei energetisch kritischen Zuständen.";
CM_ SG_ 2463978850 NVEM_Batt_Temp_Hinweis "Anforderung Kühlungsunterstützung der NV - Batterie";
CM_ SG_ 2463978850 NVEM_Bordnetz_Information "Informationsanzeigen zum 12V - Bordnetz";
CM_ SG_ 2463978850 NVEM_NVStuetzungAnf "Aktivierung / Deaktivierung Primärenergieversorger";
CM_ SG_ 2463978850 NVEM_Verbraucher_Information "Mit diesem Signal löst Das NVM eine Anzeige bzgl. einer bevorstehenden oder erfolgten Verbraucherabschaltung aus";

CM_ SG_ 870 Blinken_li_Fzg_Takt "Fzg-Takt Blinker links

";
CM_ SG_ 870 Blinken_li_Kombi_Takt "Kombi-Takt Blinker links

";
CM_ SG_ 870 Blinken_re_Fzg_Takt "Fzg-Takt Blinker rechts

";
CM_ SG_ 870 Blinken_re_Kombi_Takt "Kombi-Takt Blinker rechts

";
CM_ SG_ 870 Blinkmodi_02_BZ "4bit Botschaftszähler, wird mit jeder Sendebotschaft inkrementiert";
CM_ SG_ 870 Blinkmodi_02_CRC "Für MLB:
Berechnung siehe Lastenheft 'Kommunikationsabsicherung für FlexRay und CAN'
Ab MQB und MLBevo:
Berechnung siehe Lastenheft 'End-to-End Kommunikationsabsicherung'

Endwerte siehe Begleitdokument 'S-PDU Kennungsfolgen'";
CM_ SG_ 870 BM_Autobahn "Status Autobahnblinken
";
CM_ SG_ 870 BM_Crash "Status Crashblinken
";
CM_ SG_ 870 BM_DWA_Alarm "Status DWA-Alarmblinken
";
CM_ SG_ 870 BM_DWA_ein "Status Quittierungsblinken DWA";
CM_ SG_ 870 BM_GDO "Blinken bei UGDO anlernen

";
CM_ SG_ 870 BM_HD_Oeffnung_angelernt "HD_Rueckmeld_prog eine Blinkerquittierung wird beim BCM2 angefordert.
Wenn die Geschwindigkeit kleiner einer vorgegebenen Schwelle (default 2km/h) ist wird das Signal BM_HD_Öffnung_angelernt versendet und die Blinkerquittierung ausgelöst";
CM_ SG_ 870 BM_links "Richtungsblinken links

";
CM_ SG_ 870 BM_NBA_n_codiert_n_aktiv "Notbremsanzeige nicht codiert/nicht aktiv (Fehler)";
CM_ SG_ 870 BM_NBA_Status "Notbremsanzeige Status nicht aktiv / BRL Dunkelphase / BRL Hellphase";
CM_ SG_ 870 BM_Not_Bremsung "Das Signal BM_Not_Bremsung  zeigt an,  ob ein Warnblinken aufgrund einer vom Bremssystem signalisierten Notbremsung aktiv ist.";
CM_ SG_ 870 BM_Panik "Panikblinken
";
CM_ SG_ 870 BM_PiloPa "Quittierungsblinken bei pilotierten Parkvorgängen";
CM_ SG_ 870 BM_Recas "Blinkermodus RECAS  (RearEndCollisionAlertSignal)";
CM_ SG_ 870 BM_rechts "Richtungsblinken rechts

";
CM_ SG_ 870 BM_Rollenmodus_Blinken "Das Signal wird statisch gesetzt, wenn die Blinkerart Rollenmodus_Blinken aktiv ist.";
CM_ SG_ 870 BM_Taxi_Notalarm "Blinken bei Taxi-Not-Alarm

";
CM_ SG_ 870 BM_Telematik "Telematikblinken
";
CM_ SG_ 870 BM_Telematik_Abbruchgrund "Gibt bei erwaretem aber ausbleibendem Flankenanstieg der BM_Telematik an wieso die Ausführung verhindert wurde. Bei Flankenabfall der BM_Telematik wird angegeben wieso die Ausführung beendet wurde.

Bei nicht bereitem Sender soll 'init' gesendet werden,";
CM_ SG_ 870 BM_Warnblinken "Warnblinken

";
CM_ SG_ 870 BM_WBA_Warnblinken "Rückkanal des durch WBA (Warnen, Bremsen, Ausweichen) angeforderten Warnblinken";
CM_ SG_ 870 BM_WBT_Beleuchtung "Aktivierung Warnblinktasterfunktionsbeleuchtung
Warnblinktasterfunktionsbeleuchtung soll aktiviert werden (statisch auf 1)";
CM_ SG_ 870 BM_Wischblinken "Blinkermodus Wisch_Blinken";
CM_ SG_ 870 BM_ZV_auf "Blinken bei ZV auf

";
CM_ SG_ 870 BM_ZV_zu "Blinken bei ZV zu

";
CM_ SG_ 870 SAL_RHP_Blinken_Status "SAL Rückmeldung Rush Hour Pilot Blinker-Status an Funktion RHP";
CM_ SG_ 870 SAL_RHP_Warnblinken "Rückkanal des durch RHP angeforderten Warnblinken";
CM_ SG_ 870 SAL_TA_Blinken_Status "SAL RückmeldungTravelAssist Blinker-Status an Funktion TA (MFK)";

CM_ SG_ 2589283664 BMS_Balancing_Aktiv "Signal zeigt an, ob mindestens eine Zelle der HV Batterie balanciert wird";
CM_ SG_ 2589283664 BMS_Ladevorgang_aktiv "Signalisiert aktiven Ladevorgang, Ladegerät und DC/DC aktiv.
Signal bleibt nach Kl.15 ein aktiv, bis ESP_Stillstandsflag gelöscht.

Abhängigkeit zu BMS_Energieinhalt";
CM_ SG_ 2589283664 BMS_Max_Energie "Nutzbarer maximaler Entlade-Energieinhalt der vollgeladenen Batterie. 

Projektabhängig kann der Energiewert vom variablen SOC-Fenster (zwischen oberer und unterer SOC-Grenze), dem Alterungszustand, dem aktuellen Lastprofil sowie der Temperatur abhängen";
CM_ SG_ 2589283664 BMS_Max_Ladezustand "Obere Ladezustandsgrenze für das SOC-Fenster in der Betriebsstrategie. 
Der Wert kann sich über Lebensdauer und Alterung des Batteriesystems ändern; 
Erreicht der Wert 'BMS_Ladezustand' den hier übertragenen Wert, darf die Batterie nicht weiter geladen ";
CM_ SG_ 2589283664 BMS_Min_Ladezustand "Untere Ladezustandsgrenze für das SOC-Fenster in der Betriebsstrategie. 
Der Wert kann sich über Lebensdauer und Alterung des Batteriesystems ändern; 
Erreicht der Wert 'BMS_Ladezustand' nach unten hin den hier übertragenen Wert, darf die Batterie nicht";
CM_ SG_ 2589283664 BMS_RIso_Ext "Minimum des Isolationswiderstands zwischen Batteriegehäuse und HV+ bzw. Batteriegehäuse und HV- bei geschlossenen Schützen (externe Iso Messung)";

CM_ SG_ 2589283941 CHA_Drehschalter_AktivesProfil "Gibt das momentan aktive FPA-Profil an";
CM_ SG_ 2589283941 CHA_Drehschalter_Profil_1 "Signal zum Übermitteln der Profilreihenfolge auf dem FES";
CM_ SG_ 2589283941 CHA_Drehschalter_Profil_2 "Signal zum Übermitteln der Profilreihenfolge auf dem FES";
CM_ SG_ 2589283941 CHA_Drehschalter_Profil_3 "Signal zum Übermitteln der Profilreihenfolge auf dem FES";
CM_ SG_ 2589283941 CHA_Drehschalter_Profil_4 "Signal zum Übermitteln der Profilreihenfolge auf dem FES";
CM_ SG_ 2589283941 CHA_Drehschalter_Profil_5 "Signal zum Übermitteln der Profilreihenfolge auf dem FES";
CM_ SG_ 2589283941 CHA_Drehschalter_Profil_6 "Signal zum Übermitteln der Profilreihenfolge auf dem FES";
CM_ SG_ 2589283941 CHA_Drehschalter_Profil_7 "Signal zum Übermitteln der Profilreihenfolge auf dem FES";

CM_ SG_ 902 CHA_Charge_LED "Ansteuerung der LED am Charge-Taster durch Charisma im PHEV";
CM_ SG_ 902 CHA_Charisma_Taste2_LED "Ansteuerung der 2. Charisma-Taste-LED";
CM_ SG_ 902 CHA_Current_Mode "Aktuell eingestelltes Charisma Fahrprogramm";
CM_ SG_ 902 CHA_Current_Mode_FPA "Aktuell eingestelltes Charisma Fahrprogramm";
CM_ SG_ 902 CHA_Eco_Charisma_LED "Ansteuerung der Funktions-LED der ECO alias Bluekey Taste bzw. Charisma-Taste.
Der Master der Fahrmodus-Funktion soll die Funktionsleuchte ansteuern, in der MQB Architektur ist der Master im Gateway untergebracht.";
CM_ SG_ 902 CHA_EV_LED "Ansteuerung der LED am EV-Taster durch Charisma im PHEV";
CM_ SG_ 902 CHA_Fahrer_Umschaltung "Die manuelle Umschaltung durch den Fahrer soll signalisiert werden, um zu automatischen Umschaltungen (z.B. Retries) differenzieren zu können.";
CM_ SG_ 902 CHA_Kombi_Texte "Anzeige des aktuellen Charisma-Fahrprofiles im Kombi.
Die Texte werden HUT-Spezifisch in einem Schnittstellen-LAH definiert.";
CM_ SG_ 902 CHA_Kombi_Texte_02 "Anzeige von Hinweistexten bzgl. Charismaumschaltungen im Kombi.
Die Texte werden HUT-Spezifisch in einem Schnittstellen-LAH definiert.";
CM_ SG_ 902 CHA_Offroad_LED "Ansteuerung der Offroad-LED";
CM_ SG_ 902 CHA_ReqPrgDispSetup "Requested Charisma-programm to Kombi to change display setup.";
CM_ SG_ 902 CHA_StCurProfDft "Signal indicates if the current Charisma-profile";
CM_ SG_ 902 CHA_Ziel_FahrPr_03_01 "reserviert für Anforderung Ziel-Fahrprogramm";
CM_ SG_ 902 CHA_Ziel_FahrPr_03_02 "reserviert für Anforderung Ziel-Fahrprogramm";
CM_ SG_ 902 CHA_Ziel_FahrPr_AMB "Anforderung Ziel-Fahrprogramm Ambientelichtmodul";
CM_ SG_ 902 CHA_Ziel_FahrPr_HSP "Anforderung Ziel-Fahrprogramm Heckspoiler";
CM_ SG_ 902 CHA_Ziel_FahrPr_IVB "Anforderung Ziel-Fahrprogramm IVB";
CM_ SG_ 902 CHA_Ziel_FahrPr_KL "Anforderung Ziel-Fahrprogramm Klima";
CM_ SG_ 902 CHA_Ziel_FahrPr_RWB "Anforderung Zielfahrprogramm Reichweitenberechnung (RWB)";

CM_ SG_ 2527679921 CPD_CallCenter "Trigger an Call Center";
CM_ SG_ 2527679921 CPD_Deaktivierung_Permanent "Status der permanenten Deaktivierung der CPD-Warnung zur Anzeige (z.B. in der App)";
CM_ SG_ 2527679921 CPD_Deaktivierung_Temp "Status der temporären Deaktivierung der CPD-Funktin zur Anzeige  in der App";
CM_ SG_ 2527679921 CPD_Mobiltelefon_BLE "Triggersignal CPD zu Car2Phone-App per Bluetooth";
CM_ SG_ 2527679921 CPD_Mobiltelefon_GSM "Trigger an Mobiltelefon über Mobilfunknetz";
CM_ SG_ 2527679921 CPDFct_Deakt "Anzeige Kombi bei KL15:AUS (Kombi) und Infotainment (während Fahrt) ob Fkt CPD 2.1 temporär oder dauerhaft deaktiviert wurde";
CM_ SG_ 2527679921 CPDFct_Symbol "Status der CPD Kontrollleuchte Fkt CPD 2.1";
CM_ SG_ 2527679921 CPDFct_Warnung "Anzeige Kombi bei KL15:AUS im Warnfall Fkt CPD 2.1";

CM_ SG_ 2549880334 DIA_ABT_1_Req_Data "DK2F Flash Diagnosezugriff";

CM_ SG_ 2550011406 DIA_ABT_1_Resp_Data "DK2F Flash Diagnosezugriff";

CM_ SG_ 1714 DGN_Verlernzaehler "wrap around 254 --> 0";
CM_ SG_ 1714 KBI_Kilometerstand "Fehler wird ausgegeben, falls Kilometerstand nicht restaurierbar
";
CM_ SG_ 1714 UH_Minute "0x3C- 0x3f = Werte ungültig";
CM_ SG_ 1714 UH_Monat "0x0D, 0xF =  Werte ungültig
0x0E = Relatives Datum (nur VW)";
CM_ SG_ 1714 UH_Sekunde "0x3C- 0x3f = Werte ungültig";
CM_ SG_ 1714 UH_Stunde "0x18 - 0x1F = Werte ungültig";
CM_ SG_ 1714 UH_Tag "0x0: reserviert bei VW";
CM_ SG_ 1714 Uhrzeit_01_alt "
";
CM_ SG_ 1714 Vehicle_Driving_Cycle "Optimierung der Inbetriebnahme von Steuergeräten in einem Teilverbau in der Produktion.
Siehe VW80114. Signal bildet (durch eine Gateway-Funktion) den Inhalt des Signals OBD_Driving_Cycle ab.";

CM_ SG_ 851 DiETa_Car "Status Car-Taste";
CM_ SG_ 851 DiETa_Defrost_Taste "Max. Defrost AN/AUS";
CM_ SG_ 851 DiETa_FAS_Stufe "Status FAS-Taste";
CM_ SG_ 851 DiETa_FSH_Taste "Frontscheibenheizung AN/AUS";
CM_ SG_ 851 DiETa_HSH_Taste "Heckscheibenheizung AN/AUS";
CM_ SG_ 851 DiETa_Klima "Status Klimataste";
CM_ SG_ 851 DiETa_Lock_Unlock_Taste "Lock-/Unlock-Taste";
CM_ SG_ 851 DiETa_Mode "Status Modetaste";
CM_ SG_ 851 DiETa_Mode2 "Status Mode2taste (GTE-Taster im VW380 PHEV)";
CM_ SG_ 851 DiETa_Mode_roh "Erweitertes SIgnal zur Erfüllung der OBD-Relevanz für die Funktion Mode auf der DiETa";
CM_ SG_ 851 DiETa_PAO_OFF_Status "Istwert für LED 'OFF' in Anzeige Passenger Airbag On/Off";
CM_ SG_ 851 DiETa_PAO_ON_Status "Istwert für LED 'ON' in Anzeige Passenger Airbag On/Off";
CM_ SG_ 851 DiETa_Parken "Status Parkentaste";
CM_ SG_ 851 DiETa_Reserve_Byte2_4 "Vorhalt, Initialisierung mit '0'";
CM_ SG_ 851 DiETa_Reserve_Byte6_6 "Vorhalt, Initialisierung mit '0'";
CM_ SG_ 851 DiETa_Reserve_Byte7_4 "Vorhalt, Initialisierung mit '0'";
CM_ SG_ 851 DiETa_Reserve_Byte8 "Vorhalt, Initialisierung mit '0'";
CM_ SG_ 851 DiETa_ResponseError "siehe LIN2.0-Specification
(Darf nicht über ein Fehlergueltigkeitsbit abgesichtert werden!)";
CM_ SG_ 851 DiETa_Status "Betriebszustand Direkteinstiegstasten";
CM_ SG_ 851 DiETa_Touch_Event "Touch_Events für Informationen einer Funktionsauslösung auf DiETa, welches dann für bspw. ein akustisches Signal zentral umgesetzt werden können.";
CM_ SG_ 851 DiETa_Warnblink_Taste "Status Warnblinktaster";
CM_ SG_ 851 DiETas_01_BZ "4bit Botschaftszähler, wird mit jeder Sendebotschaft inkrementiert";
CM_ SG_ 851 DiETas_01_CRC "Für MLB:
Berechnung siehe Lastenheft 'Kommunikationsabsicherung für FlexRay und CAN'
Ab MQB und MLBevo:
Berechnung siehe Lastenheft 'End-to-End Kommunikationsabsicherung'

Endwerte siehe Begleitdokument 'S-PDU Kennungsfolgen'";
CM_ SG_ 851 ESP_Off_Taster "Das Signal beschreibt den Zustand der ESP Taste, die im MLBevo vom BCM1 eingelesen wird.
";
BA_DEF_REL_ BU_SG_REL_  "GenSigTimeoutTime" INT 0 65535;
BA_DEF_ BO_  "DiagRequest" ENUM "No", "Yes";
BA_DEF_ BO_  "DiagResponse" ENUM "No", "Yes";
BA_DEF_ BO_  "DiagState" ENUM "No", "Yes";
BA_DEF_ BO_  "GenMsgChkConstant" HEX 0 4095;
BA_DEF_ BO_  "GenMsgCycleTime" INT 0 65535;
BA_DEF_ BO_  "GenMsgCycleTimeFast" INT 0 65535;
BA_DEF_ BO_  "GenMsgDelayTime" INT 0 100000;
BA_DEF_ BO_  "GenMsgILSupport" ENUM "No", "Yes";
BA_DEF_ BO_  "GenMsgNrOfRepetition" INT 0 100;
BA_DEF_ BO_  "GenMsgPDUConstants" STRING;
BA_DEF_ BO_  "GenMsgSendType" ENUM "Cyclic", "not_used", "not_used", "not_used", "not_used", "not_used", "not_used", "IfActive", "NoMsgSendType";
BA_DEF_ BO_  "GenMsgStartDelayTime" INT 0 100000;
BA_DEF_ BO_  "NmMessage" ENUM "No", "Yes";
BA_DEF_ BO_  "NmhMessage" ENUM "No", "Yes";
BA_DEF_ BO_  "MsgType" ENUM "Application", "NM ", "NMH", "TP2.0", "ISO-TP ", "BAP", "EID", "KS", "XCP_PRE_CONFIGURED", "XCP_RUNTIME_CONFIGURED";
BA_DEF_ BO_  "VAGTP20_API" HEX 0 255;
BA_DEF_ BO_  "VAGTP20_DynConnection" ENUM "No", "Yes";
BA_DEF_ BO_  "VAGTP20_DynSetup" ENUM "No", "Yes";
BA_DEF_ BO_  "VAGTP20_StatConnection" ENUM "No", "Yes";
BA_DEF_ SG_  "GenSigActiveRepetitions" INT -2147483648 2147483647;
BA_DEF_ SG_  "GenSigInactiveValue" INT -2147483648 2147483647;
BA_DEF_ SG_  "GenSigSendType" ENUM "Cyclic", "OnWrite", "OnWriteWithRepetition", "OnChange", "OnChangeWithRepetition", "IfActive", "IfActiveWithRepetition", "NoSigSendType", "OnChangeAndIfActive", "OnChangeAndIfActiveWithRepetition";
BA_DEF_ SG_  "GenSigStartValue" INT -2147483648 2147483647;
BA_DEF_ SG_  "NWM-WakeupAllowed" ENUM "No", "Yes";
BA_DEF_ SG_  "GenSigFuncType" ENUM "NoFunction", "MsgCounter", "CRC-8", "XOR", "XOR-2", "DatedBit", "SW-Kl15", "CHK", "Constant", "Protocol", "CRC-8-SAE_J1850", "CRC-32", "DataLength", "DataID", "MsgCounter16", "SOK-Signatur", "Cluster";
BA_DEF_ SG_  "GenSigSwitchedByIgnition" ENUM "No", "Yes";
BA_DEF_ SG_  "Fehlerwert" HEX 0 2147483647;
BA_DEF_ SG_  "GenSigMissingSourceValue" HEX 0 2147483647;
BA_DEF_DEF_REL_  "GenSigTimeoutTime" 0;
BA_DEF_DEF_  "DiagRequest" "No";
BA_DEF_DEF_  "DiagResponse" "No";
BA_DEF_DEF_  "DiagState" "No";
BA_DEF_DEF_  "GenMsgChkConstant" 0;
BA_DEF_DEF_  "GenMsgCycleTime" 0;
BA_DEF_DEF_  "GenMsgCycleTimeFast" 0;
BA_DEF_DEF_  "GenMsgDelayTime" 0;
BA_DEF_DEF_  "GenMsgILSupport" "No";
BA_DEF_DEF_  "GenMsgNrOfRepetition" 0;
BA_DEF_DEF_  "GenMsgPDUConstants" "";
BA_DEF_DEF_  "GenMsgSendType" "NoMsgSendType";
BA_DEF_DEF_  "GenMsgStartDelayTime" 0;
BA_DEF_DEF_  "NmMessage" "No";
BA_DEF_DEF_  "NmhMessage" "No";
BA_DEF_DEF_  "MsgType" "Application";
BA_DEF_DEF_  "VAGTP20_API" 0;
BA_DEF_DEF_  "VAGTP20_DynConnection" "No";
BA_DEF_DEF_  "VAGTP20_DynSetup" "No";
BA_DEF_DEF_  "VAGTP20_StatConnection" "No";
BA_DEF_DEF_  "GenSigActiveRepetitions" 0;
BA_DEF_DEF_  "GenSigInactiveValue" 0;
BA_DEF_DEF_  "GenSigSendType" "NoSigSendType";
BA_DEF_DEF_  "GenSigStartValue" 0;
BA_DEF_DEF_  "NWM-WakeupAllowed" "No";
BA_DEF_DEF_  "GenSigFuncType" "NoFunction";
BA_DEF_DEF_  "GenSigSwitchedByIgnition" "Yes";
BA_DEF_DEF_  "Fehlerwert" 0;
BA_DEF_DEF_  "GenSigMissingSourceValue" 0;
BA_ "GenMsgCycleTime" BO_ 2536735504 1000;
BA_ "GenMsgCycleTimeFast" BO_ 2536735504 50;
BA_ "GenMsgSendType" BO_ 2536735504 7;
BA_ "MsgType" BO_ 2536735504 5;
BA_ "GenMsgCycleTimeFast" BO_ 2536706560 80;
BA_ "GenMsgSendType" BO_ 2536706560 7;
BA_ "MsgType" BO_ 2536706560 5;
BA_ "GenMsgCycleTimeFast" BO_ 2536706561 80;
BA_ "GenMsgSendType" BO_ 2536706561 7;
BA_ "MsgType" BO_ 2536706561 5;
BA_ "GenMsgCycleTime" BO_ 2536706576 1000;
BA_ "GenMsgCycleTimeFast" BO_ 2536706576 50;
BA_ "GenMsgSendType" BO_ 2536706576 7;
BA_ "MsgType" BO_ 2536706576 5;
BA_ "GenMsgCycleTimeFast" BO_ 2536706048 80;
BA_ "GenMsgSendType" BO_ 2536706048 7;
BA_ "MsgType" BO_ 2536706048 5;
BA_ "GenMsgCycleTimeFast" BO_ 2536706049 80;
BA_ "GenMsgSendType" BO_ 2536706049 7;
BA_ "MsgType" BO_ 2536706049 5;
BA_ "GenMsgCycleTime" BO_ 2536706064 1000;
BA_ "GenMsgCycleTimeFast" BO_ 2536706064 50;
BA_ "GenMsgSendType" BO_ 2536706064 7;
BA_ "MsgType" BO_ 2536706064 5;
BA_ "GenMsgCycleTimeFast" BO_ 2536710144 80;
BA_ "GenMsgSendType" BO_ 2536710144 7;
BA_ "MsgType" BO_ 2536710144 5;
BA_ "GenMsgCycleTime" BO_ 2536710160 1000;
BA_ "GenMsgCycleTimeFast" BO_ 2536710160 50;
BA_ "GenMsgSendType" BO_ 2536710160 7;
BA_ "MsgType" BO_ 2536710160 5;
BA_ "GenMsgCycleTimeFast" BO_ 2536736000 80;
BA_ "GenMsgSendType" BO_ 2536736000 7;
BA_ "MsgType" BO_ 2536736000 5;
BA_ "GenMsgCycleTime" BO_ 2536736016 1000;
BA_ "GenMsgCycleTimeFast" BO_ 2536736016 50;
BA_ "GenMsgSendType" BO_ 2536736016 7;
BA_ "MsgType" BO_ 2536736016 5;
BA_ "GenMsgCycleTimeFast" BO_ 2536720896 80;
BA_ "GenMsgSendType" BO_ 2536720896 7;
BA_ "MsgType" BO_ 2536720896 5;
BA_ "GenMsgCycleTime" BO_ 2536720912 1000;
BA_ "GenMsgCycleTimeFast" BO_ 2536720912 50;
BA_ "GenMsgSendType" BO_ 2536720912 7;
BA_ "MsgType" BO_ 2536720912 5;
BA_ "GenMsgCycleTimeFast" BO_ 2536721152 80;
BA_ "GenMsgSendType" BO_ 2536721152 7;
BA_ "MsgType" BO_ 2536721152 5;
BA_ "GenMsgCycleTime" BO_ 2536721168 1000;
BA_ "GenMsgCycleTimeFast" BO_ 2536721168 50;
BA_ "GenMsgSendType" BO_ 2536721168 7;
BA_ "MsgType" BO_ 2536721168 5;
BA_ "GenMsgCycleTimeFast" BO_ 2536708608 80;
BA_ "GenMsgSendType" BO_ 2536708608 7;
BA_ "MsgType" BO_ 2536708608 5;
BA_ "GenMsgCycleTimeFast" BO_ 2536708610 80;
BA_ "GenMsgSendType" BO_ 2536708610 7;
BA_ "MsgType" BO_ 2536708610 5;
BA_ "GenMsgCycleTime" BO_ 2536708624 1000;
BA_ "GenMsgCycleTimeFast" BO_ 2536708624 50;
BA_ "GenMsgSendType" BO_ 2536708624 7;
BA_ "MsgType" BO_ 2536708624 5;
BA_ "GenMsgCycleTimeFast" BO_ 2536712448 80;
BA_ "GenMsgSendType" BO_ 2536712448 7;
BA_ "MsgType" BO_ 2536712448 5;
BA_ "GenMsgCycleTimeFast" BO_ 2536712449 80;
BA_ "GenMsgSendType" BO_ 2536712449 7;
BA_ "MsgType" BO_ 2536712449 5;
BA_ "GenMsgCycleTime" BO_ 2536712464 1000;
BA_ "GenMsgCycleTimeFast" BO_ 2536712464 50;
BA_ "GenMsgSendType" BO_ 2536712464 7;
BA_ "MsgType" BO_ 2536712464 5;
BA_ "GenMsgCycleTime" BO_ 2536712465 1000;
BA_ "GenMsgCycleTimeFast" BO_ 2536712465 50;
BA_ "GenMsgSendType" BO_ 2536712465 7;
BA_ "MsgType" BO_ 2536712465 5;
BA_ "GenMsgCycleTimeFast" BO_ 2536712192 30;
BA_ "GenMsgSendType" BO_ 2536712192 7;
BA_ "MsgType" BO_ 2536712192 5;
BA_ "GenMsgCycleTimeFast" BO_ 2536712193 50;
BA_ "GenMsgSendType" BO_ 2536712193 7;
BA_ "MsgType" BO_ 2536712193 5;
BA_ "GenMsgCycleTimeFast" BO_ 2536712194 30;
BA_ "GenMsgSendType" BO_ 2536712194 7;
BA_ "MsgType" BO_ 2536712194 5;
BA_ "GenMsgCycleTimeFast" BO_ 2536712195 50;
BA_ "GenMsgSendType" BO_ 2536712195 7;
BA_ "MsgType" BO_ 2536712195 5;
BA_ "GenMsgCycleTime" BO_ 2536712208 1000;
BA_ "GenMsgCycleTimeFast" BO_ 2536712208 30;
BA_ "GenMsgSendType" BO_ 2536712208 7;
BA_ "MsgType" BO_ 2536712208 5;
BA_ "GenMsgCycleTime" BO_ 2536712209 1000;
BA_ "GenMsgCycleTimeFast" BO_ 2536712209 10;
BA_ "GenMsgSendType" BO_ 2536712209 7;
BA_ "MsgType" BO_ 2536712209 5;
BA_ "GenMsgCycleTimeFast" BO_ 2536726273 80;
BA_ "GenMsgSendType" BO_ 2536726273 7;
BA_ "MsgType" BO_ 2536726273 5;
BA_ "GenMsgCycleTime" BO_ 2536726288 1000;
BA_ "GenMsgCycleTimeFast" BO_ 2536726288 20;
BA_ "GenMsgSendType" BO_ 2536726288 7;
BA_ "MsgType" BO_ 2536726288 5;
BA_ "GenMsgCycleTimeFast" BO_ 2536715776 80;
BA_ "GenMsgSendType" BO_ 2536715776 7;
BA_ "MsgType" BO_ 2536715776 5;
BA_ "GenMsgCycleTime" BO_ 2536715792 1000;
BA_ "GenMsgCycleTimeFast" BO_ 2536715792 50;
BA_ "GenMsgSendType" BO_ 2536715792 7;
BA_ "MsgType" BO_ 2536715792 5;
BA_ "GenMsgCycleTimeFast" BO_ 2536706304 80;
BA_ "GenMsgSendType" BO_ 2536706304 7;
BA_ "MsgType" BO_ 2536706304 5;
BA_ "GenMsgCycleTimeFast" BO_ 2536706308 80;
BA_ "GenMsgSendType" BO_ 2536706308 7;
BA_ "MsgType" BO_ 2536706308 5;
BA_ "GenMsgCycleTime" BO_ 2536706320 1000;
BA_ "GenMsgCycleTimeFast" BO_ 2536706320 50;
BA_ "GenMsgSendType" BO_ 2536706320 7;
BA_ "MsgType" BO_ 2536706320 5;
BA_ "GenMsgCycleTimeFast" BO_ 2536710400 80;
BA_ "GenMsgSendType" BO_ 2536710400 7;
BA_ "MsgType" BO_ 2536710400 5;
BA_ "GenMsgCycleTimeFast" BO_ 2536710403 80;
BA_ "GenMsgSendType" BO_ 2536710403 7;
BA_ "MsgType" BO_ 2536710403 5;
BA_ "GenMsgCycleTime" BO_ 2536710416 1000;
BA_ "GenMsgCycleTimeFast" BO_ 2536710416 50;
BA_ "GenMsgSendType" BO_ 2536710416 7;
BA_ "MsgType" BO_ 2536710416 5;
BA_ "GenMsgCycleTimeFast" BO_ 2536705024 80;
BA_ "GenMsgSendType" BO_ 2536705024 7;
BA_ "MsgType" BO_ 2536705024 5;
BA_ "GenMsgCycleTimeFast" BO_ 2536705025 80;
BA_ "GenMsgSendType" BO_ 2536705025 7;
BA_ "MsgType" BO_ 2536705025 5;
BA_ "GenMsgCycleTime" BO_ 2536705040 1000;
BA_ "GenMsgCycleTimeFast" BO_ 2536705040 50;
BA_ "GenMsgSendType" BO_ 2536705040 7;
BA_ "MsgType" BO_ 2536705040 5;
BA_ "GenMsgCycleTime" BO_ 1626 1000;
BA_ "GenMsgCycleTimeFast" BO_ 1626 100;
BA_ "GenMsgDelayTime" BO_ 1626 30;
BA_ "GenMsgILSupport" BO_ 1626 1;
BA_ "GenMsgNrOfRepetition" BO_ 1626 5;
BA_ "GenMsgSendType" BO_ 1626 0;
BA_ "GenMsgCycleTime" BO_ 2527679637 1000;
BA_ "GenMsgCycleTimeFast" BO_ 2527679637 100;
BA_ "GenMsgDelayTime" BO_ 2527679637 50;
BA_ "GenMsgILSupport" BO_ 2527679637 1;
BA_ "GenMsgNrOfRepetition" BO_ 2527679637 5;
BA_ "GenMsgSendType" BO_ 2527679637 0;
BA_ "GenMsgCycleTime" BO_ 2463978607 200;
BA_ "GenMsgDelayTime" BO_ 2463978607 20;
BA_ "GenMsgILSupport" BO_ 2463978607 1;
BA_ "GenMsgSendType" BO_ 2463978607 0;
BA_ "GenMsgCycleTime" BO_ 2527679781 1000;
BA_ "GenMsgDelayTime" BO_ 2527679781 20;
BA_ "GenMsgILSupport" BO_ 2527679781 1;
BA_ "GenMsgSendType" BO_ 2527679781 0;
BA_ "GenMsgCycleTime" BO_ 2463978882 1000;
BA_ "GenMsgCycleTimeFast" BO_ 2463978882 30;
BA_ "GenMsgDelayTime" BO_ 2463978882 30;
BA_ "GenMsgILSupport" BO_ 2463978882 1;
BA_ "GenMsgNrOfRepetition" BO_ 2463978882 5;
BA_ "GenMsgPDUConstants" BO_ 2463978882 "0x12,0x06,0x44,0x35,0x6a,0x54,0x88,0xaa,0x80,0xe0,0xbc,0x53,0x70,0x45,0x71,0x0e";
BA_ "GenMsgSendType" BO_ 2463978882 0;
BA_ "GenMsgCycleTime" BO_ 2463978886 200;
BA_ "GenMsgCycleTimeFast" BO_ 2463978886 30;
BA_ "GenMsgDelayTime" BO_ 2463978886 30;
BA_ "GenMsgILSupport" BO_ 2463978886 1;
BA_ "GenMsgNrOfRepetition" BO_ 2463978886 5;
BA_ "GenMsgPDUConstants" BO_ 2463978886 "0x5b,0x3e,0xa2,0x06,0x68,0xa5,0x04,0xdf,0x90,0xdd,0x87,0xf9,0x52,0x1c,0x12,0x15";
BA_ "GenMsgSendType" BO_ 2463978886 0;
BA_ "GenMsgCycleTime" BO_ 2463978881 1000;
BA_ "GenMsgCycleTimeFast" BO_ 2463978881 30;
BA_ "GenMsgDelayTime" BO_ 2463978881 30;
BA_ "GenMsgILSupport" BO_ 2463978881 1;
BA_ "GenMsgNrOfRepetition" BO_ 2463978881 5;
BA_ "GenMsgPDUConstants" BO_ 2463978881 "0xfb,0xbc,0xed,0x2c,0xda,0x67,0xd6,0xd8,0xe1,0x85,0x96,0x69,0x4e,0xea,0x63,0x31";
BA_ "GenMsgSendType" BO_ 2463978881 0;
BA_ "GenMsgCycleTime" BO_ 2463978885 200;
BA_ "GenMsgCycleTimeFast" BO_ 2463978885 30;
BA_ "GenMsgDelayTime" BO_ 2463978885 30;
BA_ "GenMsgILSupport" BO_ 2463978885 1;
BA_ "GenMsgNrOfRepetition" BO_ 2463978885 5;
BA_ "GenMsgPDUConstants" BO_ 2463978885 "0x6d,0x6b,0x29,0x84,0x22,0xde,0xd3,0xe7,0x52,0x3f,0x96,0x0e,0xe4,0xce,0xaa,0x0d";
BA_ "GenMsgSendType" BO_ 2463978885 0;
BA_ "GenMsgCycleTime" BO_ 2463978863 1000;
BA_ "GenMsgDelayTime" BO_ 2463978863 30;
BA_ "GenMsgILSupport" BO_ 2463978863 1;
BA_ "GenMsgSendType" BO_ 2463978863 0;
BA_ "GenMsgCycleTime" BO_ 1635 100;
BA_ "GenMsgILSupport" BO_ 1635 1;
BA_ "GenMsgSendType" BO_ 1635 0;
BA_ "GenMsgCycleTime" BO_ 2463978850 100;
BA_ "GenMsgILSupport" BO_ 2463978850 1;
BA_ "GenMsgPDUConstants" BO_ 2463978850 "0xaa,0xa9,0xe6,0xc5,0xc4,0x2b,0x0b,0x8e,0xfb,0x15,0xa4,0x64,0x1e,0x20,0x50,0x95";
BA_ "GenMsgSendType" BO_ 2463978850 0;
BA_ "GenMsgCycleTime" BO_ 870 1000;
BA_ "GenMsgCycleTimeFast" BO_ 870 50;
BA_ "GenMsgDelayTime" BO_ 870 10;
BA_ "GenMsgILSupport" BO_ 870 1;
BA_ "GenMsgNrOfRepetition" BO_ 870 5;
BA_ "GenMsgPDUConstants" BO_ 870 "0xa9,0xbd,0xfb,0x3c,0x95,0x0f,0x75,0x3a,0x4f,0x19,0x59,0x6d,0xb2,0xe9,0xd1,0x97";
BA_ "GenMsgSendType" BO_ 870 0;
BA_ "GenMsgCycleTime" BO_ 2589283664 500;
BA_ "GenMsgILSupport" BO_ 2589283664 1;
BA_ "GenMsgSendType" BO_ 2589283664 0;
BA_ "GenMsgCycleTime" BO_ 2589283941 1000;
BA_ "GenMsgDelayTime" BO_ 2589283941 50;
BA_ "GenMsgILSupport" BO_ 2589283941 1;
BA_ "GenMsgSendType" BO_ 2589283941 0;
BA_ "GenMsgCycleTime" BO_ 902 1000;
BA_ "GenMsgDelayTime" BO_ 902 50;
BA_ "GenMsgILSupport" BO_ 902 1;
BA_ "GenMsgSendType" BO_ 902 0;
BA_ "GenMsgCycleTime" BO_ 2527679921 200;
BA_ "GenMsgDelayTime" BO_ 2527679921 10;
BA_ "GenMsgILSupport" BO_ 2527679921 1;
BA_ "GenMsgSendType" BO_ 2527679921 0;
BA_ "DiagRequest" BO_ 2549880334 1;
BA_ "MsgType" BO_ 2549880334 4;
BA_ "DiagResponse" BO_ 2550011406 1;
BA_ "MsgType" BO_ 2550011406 4;
BA_ "GenMsgCycleTime" BO_ 1714 1000;
BA_ "GenMsgILSupport" BO_ 1714 1;
BA_ "GenMsgSendType" BO_ 1714 0;
BA_ "GenMsgCycleTime" BO_ 851 80;
BA_ "GenMsgILSupport" BO_ 851 1;
BA_ "GenMsgPDUConstants" BO_ 851 "0x3a,0x97,0x6b,0x70,0x1e,0x84,0xe1,0xb4,0xde,0xb8,0x03,0xe7,0x33,0x20,0x3f,0x7c";
BA_ "GenMsgSendType" BO_ 851 0;
BA_ "GenSigSendType" SG_ 2536735504 BAP_SecEvents2_FSG_01_Header 3;
BA_ "GenSigSwitchedByIgnition" SG_ 2536735504 BAP_SecEvents2_FSG_01_Header 0;
BA_ "GenSigSendType" SG_ 2536706560 BAP_SIA_ASG_01_Header 3;
BA_ "GenSigSwitchedByIgnition" SG_ 2536706560 BAP_SIA_ASG_01_Header 0;
BA_ "GenSigSendType" SG_ 2536706561 BAP_SIA_ASG_02_Header 3;
BA_ "GenSigSwitchedByIgnition" SG_ 2536706561 BAP_SIA_ASG_02_Header 0;
BA_ "GenSigSendType" SG_ 2536706576 BAP_SIA_FSG_01_Header 3;
BA_ "GenSigSwitchedByIgnition" SG_ 2536706576 BAP_SIA_FSG_01_Header 0;
BA_ "GenSigSendType" SG_ 2536706048 BAP_Sitz1_ASG_01_Header 3;
BA_ "GenSigSwitchedByIgnition" SG_ 2536706048 BAP_Sitz1_ASG_01_Header 0;
BA_ "GenSigSendType" SG_ 2536706049 BAP_Sitz1_ASG_02_Header 3;
BA_ "GenSigSwitchedByIgnition" SG_ 2536706049 BAP_Sitz1_ASG_02_Header 0;
BA_ "GenSigSendType" SG_ 2536706064 BAP_Sitz1_FSG_01_Header 3;
BA_ "GenSigSwitchedByIgnition" SG_ 2536706064 BAP_Sitz1_FSG_01_Header 0;
BA_ "GenSigSendType" SG_ 2536710144 BAP_Sitz2_ASG_01_Header 3;
BA_ "GenSigSwitchedByIgnition" SG_ 2536710144 BAP_Sitz2_ASG_01_Header 0;
BA_ "GenSigSendType" SG_ 2536710160 BAP_Sitz2_FSG_01_Header 3;
BA_ "GenSigSwitchedByIgnition" SG_ 2536710160 BAP_Sitz2_FSG_01_Header 0;
BA_ "GenSigSendType" SG_ 2536736000 BAP_SLCView_ASG_01_Header 3;
BA_ "GenSigSwitchedByIgnition" SG_ 2536736000 BAP_SLCView_ASG_01_Header 0;
BA_ "GenSigSendType" SG_ 2536736016 BAP_SLCView_FSG_01_Header 3;
BA_ "GenSigSwitchedByIgnition" SG_ 2536736016 BAP_SLCView_FSG_01_Header 0;
BA_ "GenSigSendType" SG_ 2536720896 BAP_Statistics_ASG_01_Header 3;
BA_ "GenSigSwitchedByIgnition" SG_ 2536720896 BAP_Statistics_ASG_01_Header 0;
BA_ "GenSigSendType" SG_ 2536720912 BAP_Statistics_FSG_01_Header 3;
BA_ "GenSigSwitchedByIgnition" SG_ 2536720912 BAP_Statistics_FSG_01_Header 0;
BA_ "GenSigSendType" SG_ 2536721152 BAP_Sunroof_ASG_01_Header 3;
BA_ "GenSigSwitchedByIgnition" SG_ 2536721152 BAP_Sunroof_ASG_01_Header 0;
BA_ "GenSigSendType" SG_ 2536721168 BAP_Sunroof_FSG_01_Header 3;
BA_ "GenSigSwitchedByIgnition" SG_ 2536721168 BAP_Sunroof_FSG_01_Header 0;
BA_ "GenSigSendType" SG_ 2536708608 BAP_SWA_ASG_01_Header 3;
BA_ "GenSigSwitchedByIgnition" SG_ 2536708608 BAP_SWA_ASG_01_Header 0;
BA_ "GenSigSendType" SG_ 2536708610 BAP_SWA_ASG_03_Header 3;
BA_ "GenSigSwitchedByIgnition" SG_ 2536708610 BAP_SWA_ASG_03_Header 0;
BA_ "GenSigSendType" SG_ 2536708624 BAP_SWA_FSG_01_Header 3;
BA_ "GenSigSendType" SG_ 2536712448 BAP_Telefon2_ASG_01_Header 3;
BA_ "GenSigSwitchedByIgnition" SG_ 2536712448 BAP_Telefon2_ASG_01_Header 0;
BA_ "GenSigSendType" SG_ 2536712449 BAP_Telefon2_ASG_02_Header 3;
BA_ "GenSigSwitchedByIgnition" SG_ 2536712449 BAP_Telefon2_ASG_02_Header 0;
BA_ "GenSigSendType" SG_ 2536712464 BAP_Telefon2_FSG_01_Header 3;
BA_ "GenSigSwitchedByIgnition" SG_ 2536712464 BAP_Telefon2_FSG_01_Header 0;
BA_ "GenSigSendType" SG_ 2536712465 BAP_Telefon2_FSG_02_Header 3;
BA_ "GenSigSwitchedByIgnition" SG_ 2536712465 BAP_Telefon2_FSG_02_Header 0;
BA_ "GenSigSendType" SG_ 2536712192 BAP_Telefon_ASG_01_Header 3;
BA_ "GenSigSwitchedByIgnition" SG_ 2536712192 BAP_Telefon_ASG_01_Header 0;
BA_ "GenSigSendType" SG_ 2536712193 BAP_Telefon_ASG_02_Header 3;
BA_ "GenSigSwitchedByIgnition" SG_ 2536712193 BAP_Telefon_ASG_02_Header 0;
BA_ "GenSigSendType" SG_ 2536712194 BAP_Telefon_ASG_03_Header 3;
BA_ "GenSigSwitchedByIgnition" SG_ 2536712194 BAP_Telefon_ASG_03_Header 0;
BA_ "GenSigSendType" SG_ 2536712195 BAP_Telefon_ASG_04_Header 3;
BA_ "GenSigSwitchedByIgnition" SG_ 2536712195 BAP_Telefon_ASG_04_Header 0;
BA_ "GenSigSendType" SG_ 2536712208 BAP_Telefon_FSG_01_Header 3;
BA_ "GenSigSwitchedByIgnition" SG_ 2536712208 BAP_Telefon_FSG_01_Header 0;
BA_ "GenSigSendType" SG_ 2536712209 BAP_Telefon_FSG_02_Header 3;
BA_ "GenSigSwitchedByIgnition" SG_ 2536712209 BAP_Telefon_FSG_02_Header 0;
BA_ "GenSigSendType" SG_ 2536726273 BAP_TPA_ASG_02_Header 3;
BA_ "GenSigSwitchedByIgnition" SG_ 2536726273 BAP_TPA_ASG_02_Header 0;
BA_ "GenSigSendType" SG_ 2536726288 BAP_TPA_FSG_01_Header 3;
BA_ "GenSigSwitchedByIgnition" SG_ 2536726288 BAP_TPA_FSG_01_Header 0;
BA_ "GenSigSendType" SG_ 2536715776 BAP_TrailerAssist_ASG_01_Header 3;
BA_ "GenSigSwitchedByIgnition" SG_ 2536715776 BAP_TrailerAssist_ASG_01_Header 0;
BA_ "GenSigSendType" SG_ 2536715792 BAP_TrailerAssist_FSG_01_Header 3;
BA_ "GenSigSendType" SG_ 2536706304 BAP_Uhrzeit_ASG_01_Header 3;
BA_ "GenSigSwitchedByIgnition" SG_ 2536706304 BAP_Uhrzeit_ASG_01_Header 0;
BA_ "GenSigSendType" SG_ 2536706308 BAP_Uhrzeit_ASG_05_Header 3;
BA_ "GenSigSwitchedByIgnition" SG_ 2536706308 BAP_Uhrzeit_ASG_05_Header 0;
BA_ "GenSigSendType" SG_ 2536706320 BAP_Uhrzeit_FSG_01_Header 3;
BA_ "GenSigSwitchedByIgnition" SG_ 2536706320 BAP_Uhrzeit_FSG_01_Header 0;
BA_ "GenSigSendType" SG_ 2536710400 BAP_VZA_ASG_01_Header 3;
BA_ "GenSigSwitchedByIgnition" SG_ 2536710400 BAP_VZA_ASG_01_Header 0;
BA_ "GenSigSendType" SG_ 2536710403 BAP_VZA_ASG_04_Header 3;
BA_ "GenSigSwitchedByIgnition" SG_ 2536710403 BAP_VZA_ASG_04_Header 0;
BA_ "GenSigSendType" SG_ 2536710416 BAP_VZA_FSG_01_Header 3;
BA_ "GenSigSendType" SG_ 2536705024 BAP_Wiper_ASG_01_Header 3;
BA_ "GenSigSwitchedByIgnition" SG_ 2536705024 BAP_Wiper_ASG_01_Header 0;
BA_ "GenSigSendType" SG_ 2536705025 BAP_Wiper_ASG_02_Header 3;
BA_ "GenSigSwitchedByIgnition" SG_ 2536705025 BAP_Wiper_ASG_02_Header 0;
BA_ "GenSigSendType" SG_ 2536705040 BAP_Wiper_FSG_01_Header 3;
BA_ "GenSigSwitchedByIgnition" SG_ 2536705040 BAP_Wiper_FSG_01_Header 0;
BA_ "GenSigSendType" SG_ 1626 APS_Tongeber_defekt 3;
BA_ "GenSigSwitchedByIgnition" SG_ 1626 APS_Tongeber_defekt 0;
BA_ "GenSigSendType" SG_ 1626 BCM1_AFS_Lampe 3;
BA_ "GenSigSwitchedByIgnition" SG_ 1626 BCM1_AFS_Lampe 0;
BA_ "GenSigSendType" SG_ 1626 BCM1_EasyEntry_Status 3;
BA_ "GenSigSwitchedByIgnition" SG_ 1626 BCM1_EasyEntry_Status 0;
BA_ "GenSigSendType" SG_ 1626 BCM1_Fahrlicht_Hinweis 3;
BA_ "GenSigSwitchedByIgnition" SG_ 1626 BCM1_Fahrlicht_Hinweis 0;
BA_ "GenSigSendType" SG_ 1626 BCM1_Hinweis_Lichtnachlauf 3;
BA_ "GenSigSwitchedByIgnition" SG_ 1626 BCM1_Hinweis_Lichtnachlauf 0;
BA_ "GenSigSendType" SG_ 1626 BCM1_Kl_15_HW_erkannt 3;
BA_ "GenSigSwitchedByIgnition" SG_ 1626 BCM1_Kl_15_HW_erkannt 0;
BA_ "GenSigSendType" SG_ 1626 BCM1_Kl_15_Sig_HW_erkannt 3;
BA_ "GenSigSwitchedByIgnition" SG_ 1626 BCM1_Kl_15_Sig_HW_erkannt 0;
BA_ "GenSigSendType" SG_ 1626 BCM1_LDS_Stellung 3;
BA_ "GenSigSwitchedByIgnition" SG_ 1626 BCM1_LDS_Stellung 0;
BA_ "Fehlerwert" SG_ 1626 BCM1_LDS_Stellung 7;
BA_ "GenSigSendType" SG_ 1626 BCM1_Lenksaeule_aktiv 3;
BA_ "GenSigSwitchedByIgnition" SG_ 1626 BCM1_Lenksaeule_aktiv 0;
BA_ "GenSigSendType" SG_ 1626 BCM1_Licht_Warn 3;
BA_ "GenSigSwitchedByIgnition" SG_ 1626 BCM1_Licht_Warn 0;
BA_ "GenSigSendType" SG_ 1626 BCM1_Lichtwarn_Texte 3;
BA_ "GenSigSwitchedByIgnition" SG_ 1626 BCM1_Lichtwarn_Texte 0;
BA_ "GenSigSendType" SG_ 1626 BCM1_MH_Schalter 3;
BA_ "GenSigSwitchedByIgnition" SG_ 1626 BCM1_MH_Schalter 0;
BA_ "GenSigSendType" SG_ 1626 BCM1_MH_WIV_Schalter 3;
BA_ "GenSigSwitchedByIgnition" SG_ 1626 BCM1_MH_WIV_Schalter 0;
BA_ "GenSigSendType" SG_ 1626 BCM1_NV_Taster 0;
BA_ "GenSigSwitchedByIgnition" SG_ 1626 BCM1_NV_Taster 0;
BA_ "GenSigSendType" SG_ 1626 BCM1_Reisemodus_Texte 3;
BA_ "GenSigSwitchedByIgnition" SG_ 1626 BCM1_Reisemodus_Texte 0;
BA_ "GenSigSendType" SG_ 1626 BCM1_Rueckfahrlicht_Schalter 3;
BA_ "GenSigSwitchedByIgnition" SG_ 1626 BCM1_Rueckfahrlicht_Schalter 0;
BA_ "GenSigSendType" SG_ 1626 BCM1_Spannungs_Anf 3;
BA_ "GenSigSwitchedByIgnition" SG_ 1626 BCM1_Spannungs_Anf 0;
BA_ "GenSigSendType" SG_ 1626 BCM1_Valet_Parking_Taster 0;
BA_ "GenSigSwitchedByIgnition" SG_ 1626 BCM1_Valet_Parking_Taster 0;
BA_ "GenSigSendType" SG_ 1626 BCM1_Warnblink_Taster 3;
BA_ "GenSigSwitchedByIgnition" SG_ 1626 BCM1_Warnblink_Taster 0;
BA_ "GenSigSendType" SG_ 1626 BCM_Anf_AAW_MoLaWa 3;
BA_ "GenSigSwitchedByIgnition" SG_ 1626 BCM_Anf_AAW_MoLaWa 0;
BA_ "GenSigSendType" SG_ 1626 BCM_Bremsbelag_Sensor 3;
BA_ "GenSigSwitchedByIgnition" SG_ 1626 BCM_Bremsbelag_Sensor 0;
BA_ "GenSigSendType" SG_ 1626 BCM_Bremsfluessigkeit_Sensor 3;
BA_ "GenSigSwitchedByIgnition" SG_ 1626 BCM_Bremsfluessigkeit_Sensor 0;
BA_ "GenSigSendType" SG_ 1626 BCM_Charisma_Taste2 3;
BA_ "GenSigSwitchedByIgnition" SG_ 1626 BCM_Charisma_Taste2 0;
BA_ "GenSigSendType" SG_ 1626 BCM_Eco_Charisma_Taste 3;
BA_ "GenSigSwitchedByIgnition" SG_ 1626 BCM_Eco_Charisma_Taste 0;
BA_ "GenSigSendType" SG_ 1626 BCM_Handbremse_Hinweis 4;
BA_ "GenSigSwitchedByIgnition" SG_ 1626 BCM_Handbremse_Hinweis 0;
BA_ "GenSigSendType" SG_ 1626 BCM_HBFS_EOE_aktiv 4;
BA_ "GenSigSwitchedByIgnition" SG_ 1626 BCM_HBFS_EOE_aktiv 0;
BA_ "GenSigSendType" SG_ 1626 BCM_HDF_betaetigt 4;
BA_ "GenSigSwitchedByIgnition" SG_ 1626 BCM_HDF_betaetigt 0;
BA_ "GenSigSendType" SG_ 1626 BCM_HFS_EOE_aktiv 4;
BA_ "GenSigSwitchedByIgnition" SG_ 1626 BCM_HFS_EOE_aktiv 0;
BA_ "GenSigSendType" SG_ 1626 BCM_Hybrid_StartStopp_Taste 3;
BA_ "GenSigSwitchedByIgnition" SG_ 1626 BCM_Hybrid_StartStopp_Taste 0;
BA_ "GenSigSendType" SG_ 1626 BCM_Hybrid_StSt_Taste_Fehler 3;
BA_ "GenSigSwitchedByIgnition" SG_ 1626 BCM_Hybrid_StSt_Taste_Fehler 0;
BA_ "GenSigSendType" SG_ 1626 BCM_Kuehlmittel_Sensor 3;
BA_ "GenSigSwitchedByIgnition" SG_ 1626 BCM_Kuehlmittel_Sensor 0;
BA_ "GenSigSendType" SG_ 1626 BCM_Kuehlmittel_Sensor_02 3;
BA_ "GenSigSwitchedByIgnition" SG_ 1626 BCM_Kuehlmittel_Sensor_02 0;
BA_ "GenSigSendType" SG_ 1626 BCM_Offroad_Taste 3;
BA_ "GenSigSwitchedByIgnition" SG_ 1626 BCM_Offroad_Taste 0;
BA_ "GenSigSendType" SG_ 1626 BCM_ValetTaster_Fkts_LED 4;
BA_ "GenSigSwitchedByIgnition" SG_ 1626 BCM_ValetTaster_Fkts_LED 0;
BA_ "GenSigSendType" SG_ 1626 BCM_Waehlhebel_P_Hinweis 4;
BA_ "GenSigSwitchedByIgnition" SG_ 1626 BCM_Waehlhebel_P_Hinweis 0;
BA_ "GenSigSendType" SG_ 1626 BCM_Waschwasser_Sensor 3;
BA_ "GenSigSwitchedByIgnition" SG_ 1626 BCM_Waschwasser_Sensor 0;
BA_ "GenSigSendType" SG_ 1626 DWA_Alarmquelle 0;
BA_ "GenSigStartValue" SG_ 1626 DWA_Alarmquelle 30;
BA_ "GenSigSwitchedByIgnition" SG_ 1626 DWA_Alarmquelle 0;
BA_ "Fehlerwert" SG_ 1626 DWA_Alarmquelle 31;
BA_ "GenSigSendType" SG_ 1626 DWA_Einschraenkung 0;
BA_ "GenSigSwitchedByIgnition" SG_ 1626 DWA_Einschraenkung 0;
BA_ "Fehlerwert" SG_ 1626 DWA_Einschraenkung 1;
BA_ "GenSigSendType" SG_ 1626 Gong_TFL_Umschaltung 3;
BA_ "GenSigSwitchedByIgnition" SG_ 1626 Gong_TFL_Umschaltung 0;
BA_ "GenSigSendType" SG_ 1626 LRH_Taster 3;
BA_ "GenSigSwitchedByIgnition" SG_ 1626 LRH_Taster 0;
BA_ "GenSigSendType" SG_ 2527679637 BCM_anf_VLW 3;
BA_ "GenSigSwitchedByIgnition" SG_ 2527679637 BCM_anf_VLW 0;
BA_ "GenSigSendType" SG_ 2527679637 BCM_Defrost_Taste 3;
BA_ "GenSigStartValue" SG_ 2527679637 BCM_Defrost_Taste 3;
BA_ "GenSigSwitchedByIgnition" SG_ 2527679637 BCM_Defrost_Taste 0;
BA_ "Fehlerwert" SG_ 2527679637 BCM_Defrost_Taste 2;
BA_ "GenSigSendType" SG_ 2527679637 BCM_FAS_Taster 4;
BA_ "GenSigSwitchedByIgnition" SG_ 2527679637 BCM_FAS_Taster 0;
BA_ "GenSigSendType" SG_ 2527679637 BCM_FSH_Taste 3;
BA_ "GenSigStartValue" SG_ 2527679637 BCM_FSH_Taste 3;
BA_ "GenSigSwitchedByIgnition" SG_ 2527679637 BCM_FSH_Taste 0;
BA_ "Fehlerwert" SG_ 2527679637 BCM_FSH_Taste 2;
BA_ "GenSigSendType" SG_ 2527679637 BCM_HSH_Taste 3;
BA_ "GenSigStartValue" SG_ 2527679637 BCM_HSH_Taste 3;
BA_ "GenSigSwitchedByIgnition" SG_ 2527679637 BCM_HSH_Taste 0;
BA_ "Fehlerwert" SG_ 2527679637 BCM_HSH_Taste 2;
BA_ "GenSigSendType" SG_ 2527679637 BCM_LTM_Allwetterl_Status 3;
BA_ "GenSigSwitchedByIgnition" SG_ 2527679637 BCM_LTM_Allwetterl_Status 0;
BA_ "GenSigSendType" SG_ 2527679637 BCM_LTM_Nebell_Status 3;
BA_ "GenSigSwitchedByIgnition" SG_ 2527679637 BCM_LTM_Nebell_Status 0;
BA_ "GenSigSendType" SG_ 2527679637 BCM_LTM_Nebelschluss_Status 3;
BA_ "GenSigSwitchedByIgnition" SG_ 2527679637 BCM_LTM_Nebelschluss_Status 0;
BA_ "GenSigSendType" SG_ 2527679637 BCM_LTM_PopUp_Anf 3;
BA_ "GenSigSwitchedByIgnition" SG_ 2527679637 BCM_LTM_PopUp_Anf 0;
BA_ "GenSigSendType" SG_ 2527679637 BCM_LTM_PopUp_Inhalt 3;
BA_ "GenSigSwitchedByIgnition" SG_ 2527679637 BCM_LTM_PopUp_Inhalt 0;
BA_ "GenSigSendType" SG_ 2527679637 BCM_LTM_PopUp_Status 3;
BA_ "GenSigSwitchedByIgnition" SG_ 2527679637 BCM_LTM_PopUp_Status 0;
BA_ "GenSigSendType" SG_ 2527679637 BCM_LTM_PopUp_Texte 3;
BA_ "GenSigSwitchedByIgnition" SG_ 2527679637 BCM_LTM_PopUp_Texte 0;
BA_ "GenSigSendType" SG_ 2527679637 CPD_Warnung 3;
BA_ "GenSigSwitchedByIgnition" SG_ 2527679637 CPD_Warnung 0;
BA_ "GenSigSendType" SG_ 2527679637 LiSi_Touch_Event 3;
BA_ "GenSigSwitchedByIgnition" SG_ 2527679637 LiSi_Touch_Event 0;
BA_ "Fehlerwert" SG_ 2527679637 LiSi_Touch_Event 15;
BA_ "GenSigSendType" SG_ 2527679637 LTMs_01_alt 0;
BA_ "GenSigStartValue" SG_ 2527679637 LTMs_01_alt 1;
BA_ "GenSigFuncType" SG_ 2527679637 LTMs_01_alt 5;
BA_ "GenSigSwitchedByIgnition" SG_ 2527679637 LTMs_01_alt 0;
BA_ "GenSigSendType" SG_ 2527679637 MiKo_Tisch_Positionswarnung 3;
BA_ "GenSigSwitchedByIgnition" SG_ 2527679637 MiKo_Tisch_Positionswarnung 0;
BA_ "GenSigSendType" SG_ 2463978607 BCM_RGB_Blau 3;
BA_ "GenSigSwitchedByIgnition" SG_ 2463978607 BCM_RGB_Blau 0;
BA_ "GenSigSendType" SG_ 2463978607 BCM_RGB_Dimmrampe 3;
BA_ "GenSigSwitchedByIgnition" SG_ 2463978607 BCM_RGB_Dimmrampe 0;
BA_ "GenSigSendType" SG_ 2463978607 BCM_RGB_Dimmzeit_Zeitbasis 3;
BA_ "GenSigSwitchedByIgnition" SG_ 2463978607 BCM_RGB_Dimmzeit_Zeitbasis 0;
BA_ "GenSigSendType" SG_ 2463978607 BCM_RGB_Gruen 3;
BA_ "GenSigSwitchedByIgnition" SG_ 2463978607 BCM_RGB_Gruen 0;
BA_ "GenSigSendType" SG_ 2463978607 BCM_RGB_Intensitaet 3;
BA_ "GenSigStartValue" SG_ 2463978607 BCM_RGB_Intensitaet 126;
BA_ "GenSigSwitchedByIgnition" SG_ 2463978607 BCM_RGB_Intensitaet 0;
BA_ "Fehlerwert" SG_ 2463978607 BCM_RGB_Intensitaet 127;
BA_ "GenSigSendType" SG_ 2463978607 BCM_RGB_Normierung_Intensitaet 3;
BA_ "GenSigSwitchedByIgnition" SG_ 2463978607 BCM_RGB_Normierung_Intensitaet 0;
BA_ "GenSigSendType" SG_ 2463978607 BCM_RGB_Rot 3;
BA_ "GenSigSwitchedByIgnition" SG_ 2463978607 BCM_RGB_Rot 0;
BA_ "GenSigSendType" SG_ 2527679781 LINDa_HL_SR3_Touch_Event 3;
BA_ "GenSigSwitchedByIgnition" SG_ 2527679781 LINDa_HL_SR3_Touch_Event 0;
BA_ "Fehlerwert" SG_ 2527679781 LINDa_HL_SR3_Touch_Event 15;
BA_ "GenSigSendType" SG_ 2527679781 LINDa_HL_Touch_Event 3;
BA_ "GenSigSwitchedByIgnition" SG_ 2527679781 LINDa_HL_Touch_Event 0;
BA_ "Fehlerwert" SG_ 2527679781 LINDa_HL_Touch_Event 15;
BA_ "GenSigSendType" SG_ 2527679781 LINDa_HR_SR3_Touch_Event 3;
BA_ "GenSigSwitchedByIgnition" SG_ 2527679781 LINDa_HR_SR3_Touch_Event 0;
BA_ "Fehlerwert" SG_ 2527679781 LINDa_HR_SR3_Touch_Event 15;
BA_ "GenSigSendType" SG_ 2527679781 LINDa_HR_Touch_Event 3;
BA_ "GenSigSwitchedByIgnition" SG_ 2527679781 LINDa_HR_Touch_Event 0;
BA_ "Fehlerwert" SG_ 2527679781 LINDa_HR_Touch_Event 15;
BA_ "GenSigSendType" SG_ 2463978882 BedienDisp_hbfs_01_BZ 0;
BA_ "GenSigFuncType" SG_ 2463978882 BedienDisp_hbfs_01_BZ 1;
BA_ "GenSigSwitchedByIgnition" SG_ 2463978882 BedienDisp_hbfs_01_BZ 0;
BA_ "GenSigSendType" SG_ 2463978882 BedienDisp_hbfs_01_CRC 0;
BA_ "GenSigFuncType" SG_ 2463978882 BedienDisp_hbfs_01_CRC 2;
BA_ "GenSigSwitchedByIgnition" SG_ 2463978882 BedienDisp_hbfs_01_CRC 0;
BA_ "GenSigSendType" SG_ 2463978882 BedienDisp_hbfs_control_vol 4;
BA_ "GenSigSwitchedByIgnition" SG_ 2463978882 BedienDisp_hbfs_control_vol 0;
BA_ "Fehlerwert" SG_ 2463978882 BedienDisp_hbfs_control_vol 15;
BA_ "GenSigSendType" SG_ 2463978882 BedienDisp_hbfs_control_vol_02 4;
BA_ "GenSigStartValue" SG_ 2463978882 BedienDisp_hbfs_control_vol_02 126;
BA_ "GenSigSwitchedByIgnition" SG_ 2463978882 BedienDisp_hbfs_control_vol_02 0;
BA_ "Fehlerwert" SG_ 2463978882 BedienDisp_hbfs_control_vol_02 127;
BA_ "GenSigSendType" SG_ 2463978882 BedienDisp_hbfs_fader 4;
BA_ "GenSigSwitchedByIgnition" SG_ 2463978882 BedienDisp_hbfs_fader 0;
BA_ "Fehlerwert" SG_ 2463978882 BedienDisp_hbfs_fader 15;
BA_ "GenSigSendType" SG_ 2463978882 BedienDisp_hbfs_Lordose_hoch 4;
BA_ "GenSigSwitchedByIgnition" SG_ 2463978882 BedienDisp_hbfs_Lordose_hoch 0;
BA_ "GenSigSendType" SG_ 2463978882 BedienDisp_hbfs_Lordose_runter 4;
BA_ "GenSigSwitchedByIgnition" SG_ 2463978882 BedienDisp_hbfs_Lordose_runter 0;
BA_ "GenSigSendType" SG_ 2463978882 BedienDisp_hbfs_Lordose_vor 4;
BA_ "GenSigSwitchedByIgnition" SG_ 2463978882 BedienDisp_hbfs_Lordose_vor 0;
BA_ "GenSigSendType" SG_ 2463978882 BedienDisp_hbfs_Lordose_zurueck 4;
BA_ "GenSigSwitchedByIgnition" SG_ 2463978882 BedienDisp_hbfs_Lordose_zurueck 0;
BA_ "GenSigSendType" SG_ 2463978882 BedienDisp_hbfs_sound 4;
BA_ "GenSigSwitchedByIgnition" SG_ 2463978882 BedienDisp_hbfs_sound 0;
BA_ "GenSigSendType" SG_ 2463978882 BedienDisp_hbfs_sound_fokus 4;
BA_ "GenSigSwitchedByIgnition" SG_ 2463978882 BedienDisp_hbfs_sound_fokus 0;
BA_ "Fehlerwert" SG_ 2463978882 BedienDisp_hbfs_sound_fokus 15;
BA_ "GenSigSendType" SG_ 2463978882 BedienDisp_hbfs_surround 4;
BA_ "GenSigSwitchedByIgnition" SG_ 2463978882 BedienDisp_hbfs_surround 0;
BA_ "Fehlerwert" SG_ 2463978882 BedienDisp_hbfs_surround 15;
BA_ "GenSigSendType" SG_ 2463978882 BedienDisp_hbfs_surround_02 4;
BA_ "Fehlerwert" SG_ 2463978882 BedienDisp_hbfs_surround_02 127;
BA_ "GenSigSendType" SG_ 2463978882 BedienDisp_hbfs_touch 4;
BA_ "GenSigSwitchedByIgnition" SG_ 2463978882 BedienDisp_hbfs_touch 0;
BA_ "Fehlerwert" SG_ 2463978882 BedienDisp_hbfs_touch 15;
BA_ "GenSigSendType" SG_ 2463978882 BedienDisp_hbfs_UseCase_Pos 3;
BA_ "GenSigSwitchedByIgnition" SG_ 2463978882 BedienDisp_hbfs_UseCase_Pos 0;
BA_ "GenSigSendType" SG_ 2463978882 BedienDisp_HBFSFo_Bestaetigung 3;
BA_ "GenSigSwitchedByIgnition" SG_ 2463978882 BedienDisp_HBFSFo_Bestaetigung 0;
BA_ "Fehlerwert" SG_ 2463978882 BedienDisp_HBFSFo_Bestaetigung 3;
BA_ "GenSigSendType" SG_ 2463978882 BedienDisp_HBFSFo_Stoerung 3;
BA_ "GenSigSwitchedByIgnition" SG_ 2463978882 BedienDisp_HBFSFo_Stoerung 0;
BA_ "GenSigSendType" SG_ 2463978886 BedienDisp_hbfs_02_BZ 0;
BA_ "GenSigFuncType" SG_ 2463978886 BedienDisp_hbfs_02_BZ 1;
BA_ "GenSigSwitchedByIgnition" SG_ 2463978886 BedienDisp_hbfs_02_BZ 0;
BA_ "GenSigSendType" SG_ 2463978886 BedienDisp_hbfs_02_CRC 0;
BA_ "GenSigFuncType" SG_ 2463978886 BedienDisp_hbfs_02_CRC 2;
BA_ "GenSigSwitchedByIgnition" SG_ 2463978886 BedienDisp_hbfs_02_CRC 0;
BA_ "GenSigSendType" SG_ 2463978886 BedienDisp_hbfs_BF_Hoehe 4;
BA_ "GenSigSwitchedByIgnition" SG_ 2463978886 BedienDisp_hbfs_BF_Hoehe 0;
BA_ "Fehlerwert" SG_ 2463978886 BedienDisp_hbfs_BF_Hoehe 3;
BA_ "GenSigSendType" SG_ 2463978886 BedienDisp_hbfs_BF_Laengs 4;
BA_ "GenSigSwitchedByIgnition" SG_ 2463978886 BedienDisp_hbfs_BF_Laengs 0;
BA_ "Fehlerwert" SG_ 2463978886 BedienDisp_hbfs_BF_Laengs 5;
BA_ "GenSigSendType" SG_ 2463978886 BedienDisp_hbfs_BF_Lehne 4;
BA_ "GenSigSwitchedByIgnition" SG_ 2463978886 BedienDisp_hbfs_BF_Lehne 0;
BA_ "Fehlerwert" SG_ 2463978886 BedienDisp_hbfs_BF_Lehne 5;
BA_ "GenSigSendType" SG_ 2463978886 BedienDisp_hbfs_Cargo_Pos 4;
BA_ "GenSigSwitchedByIgnition" SG_ 2463978886 BedienDisp_hbfs_Cargo_Pos 0;
BA_ "Fehlerwert" SG_ 2463978886 BedienDisp_hbfs_Cargo_Pos 3;
BA_ "GenSigSendType" SG_ 2463978886 BedienDisp_hbfs_Komfor_Pos 4;
BA_ "GenSigSwitchedByIgnition" SG_ 2463978886 BedienDisp_hbfs_Komfor_Pos 0;
BA_ "GenSigSendType" SG_ 2463978886 BedienDisp_hbfs_Mem_Start 4;
BA_ "GenSigSwitchedByIgnition" SG_ 2463978886 BedienDisp_hbfs_Mem_Start 0;
BA_ "Fehlerwert" SG_ 2463978886 BedienDisp_hbfs_Mem_Start 3;
BA_ "GenSigSendType" SG_ 2463978886 BedienDisp_hbfs_Memo_Pos 4;
BA_ "GenSigSwitchedByIgnition" SG_ 2463978886 BedienDisp_hbfs_Memo_Pos 0;
BA_ "GenSigSendType" SG_ 2463978886 BedienDisp_hbfs_Normal_Pos 4;
BA_ "GenSigSwitchedByIgnition" SG_ 2463978886 BedienDisp_hbfs_Normal_Pos 0;
BA_ "Fehlerwert" SG_ 2463978886 BedienDisp_hbfs_Normal_Pos 3;
BA_ "GenSigSendType" SG_ 2463978886 BedienDisp_hbfs_Seat_SetReset 4;
BA_ "GenSigSwitchedByIgnition" SG_ 2463978886 BedienDisp_hbfs_Seat_SetReset 0;
BA_ "GenSigSendType" SG_ 2463978886 BedienDisp_hbfs_Seat_Storage 4;
BA_ "GenSigSwitchedByIgnition" SG_ 2463978886 BedienDisp_hbfs_Seat_Storage 0;
BA_ "GenSigSendType" SG_ 2463978886 BedienDisp_hbfs_Sitz_Arm 4;
BA_ "GenSigSwitchedByIgnition" SG_ 2463978886 BedienDisp_hbfs_Sitz_Arm 0;
BA_ "Fehlerwert" SG_ 2463978886 BedienDisp_hbfs_Sitz_Arm 5;
BA_ "GenSigSendType" SG_ 2463978886 BedienDisp_hbfs_Sitz_Bein 4;
BA_ "GenSigSwitchedByIgnition" SG_ 2463978886 BedienDisp_hbfs_Sitz_Bein 0;
BA_ "Fehlerwert" SG_ 2463978886 BedienDisp_hbfs_Sitz_Bein 5;
BA_ "GenSigSendType" SG_ 2463978886 BedienDisp_hbfs_Sitz_Hoehe 4;
BA_ "GenSigSwitchedByIgnition" SG_ 2463978886 BedienDisp_hbfs_Sitz_Hoehe 0;
BA_ "Fehlerwert" SG_ 2463978886 BedienDisp_hbfs_Sitz_Hoehe 3;
BA_ "GenSigSendType" SG_ 2463978886 BedienDisp_hbfs_Sitz_Kopf 4;
BA_ "GenSigSwitchedByIgnition" SG_ 2463978886 BedienDisp_hbfs_Sitz_Kopf 0;
BA_ "Fehlerwert" SG_ 2463978886 BedienDisp_hbfs_Sitz_Kopf 5;
BA_ "GenSigSendType" SG_ 2463978886 BedienDisp_hbfs_Sitz_Laengs 4;
BA_ "GenSigSwitchedByIgnition" SG_ 2463978886 BedienDisp_hbfs_Sitz_Laengs 0;
BA_ "Fehlerwert" SG_ 2463978886 BedienDisp_hbfs_Sitz_Laengs 5;
BA_ "GenSigSendType" SG_ 2463978886 BedienDisp_hbfs_Sitz_Lehne 4;
BA_ "GenSigSwitchedByIgnition" SG_ 2463978886 BedienDisp_hbfs_Sitz_Lehne 0;
BA_ "Fehlerwert" SG_ 2463978886 BedienDisp_hbfs_Sitz_Lehne 5;
BA_ "GenSigSendType" SG_ 2463978886 BedienDisp_hbfs_Sitz_Lehnekopf 4;
BA_ "GenSigSwitchedByIgnition" SG_ 2463978886 BedienDisp_hbfs_Sitz_Lehnekopf 0;
BA_ "Fehlerwert" SG_ 2463978886 BedienDisp_hbfs_Sitz_Lehnekopf 3;
BA_ "GenSigSendType" SG_ 2463978886 BedienDisp_hbfs_Sitz_Neigung 4;
BA_ "GenSigSwitchedByIgnition" SG_ 2463978886 BedienDisp_hbfs_Sitz_Neigung 0;
BA_ "Fehlerwert" SG_ 2463978886 BedienDisp_hbfs_Sitz_Neigung 5;
BA_ "GenSigSendType" SG_ 2463978886 BedienDisp_hbfs_Sitz_Stop 4;
BA_ "GenSigSwitchedByIgnition" SG_ 2463978886 BedienDisp_hbfs_Sitz_Stop 0;
BA_ "Fehlerwert" SG_ 2463978886 BedienDisp_hbfs_Sitz_Stop 3;
BA_ "GenSigSendType" SG_ 2463978881 BedienDisp_hfs_01_BZ 0;
BA_ "GenSigFuncType" SG_ 2463978881 BedienDisp_hfs_01_BZ 1;
BA_ "GenSigSwitchedByIgnition" SG_ 2463978881 BedienDisp_hfs_01_BZ 0;
BA_ "GenSigSendType" SG_ 2463978881 BedienDisp_hfs_01_CRC 0;
BA_ "GenSigFuncType" SG_ 2463978881 BedienDisp_hfs_01_CRC 2;
BA_ "GenSigSwitchedByIgnition" SG_ 2463978881 BedienDisp_hfs_01_CRC 0;
BA_ "GenSigSendType" SG_ 2463978881 BedienDisp_hfs_control_vol 4;
BA_ "GenSigSwitchedByIgnition" SG_ 2463978881 BedienDisp_hfs_control_vol 0;
BA_ "Fehlerwert" SG_ 2463978881 BedienDisp_hfs_control_vol 15;
BA_ "GenSigSendType" SG_ 2463978881 BedienDisp_hfs_control_vol_02 4;
BA_ "GenSigStartValue" SG_ 2463978881 BedienDisp_hfs_control_vol_02 126;
BA_ "GenSigSwitchedByIgnition" SG_ 2463978881 BedienDisp_hfs_control_vol_02 0;
BA_ "Fehlerwert" SG_ 2463978881 BedienDisp_hfs_control_vol_02 127;
BA_ "GenSigSendType" SG_ 2463978881 BedienDisp_hfs_fader 4;
BA_ "GenSigSwitchedByIgnition" SG_ 2463978881 BedienDisp_hfs_fader 0;
BA_ "Fehlerwert" SG_ 2463978881 BedienDisp_hfs_fader 15;
BA_ "GenSigSendType" SG_ 2463978881 BedienDisp_hfs_Lordose_hoch 4;
BA_ "GenSigSwitchedByIgnition" SG_ 2463978881 BedienDisp_hfs_Lordose_hoch 0;
BA_ "GenSigSendType" SG_ 2463978881 BedienDisp_hfs_Lordose_runter 4;
BA_ "GenSigSwitchedByIgnition" SG_ 2463978881 BedienDisp_hfs_Lordose_runter 0;
BA_ "GenSigSendType" SG_ 2463978881 BedienDisp_hfs_Lordose_vor 4;
BA_ "GenSigSwitchedByIgnition" SG_ 2463978881 BedienDisp_hfs_Lordose_vor 0;
BA_ "GenSigSendType" SG_ 2463978881 BedienDisp_hfs_Lordose_zurueck 4;
BA_ "GenSigSwitchedByIgnition" SG_ 2463978881 BedienDisp_hfs_Lordose_zurueck 0;
BA_ "GenSigSendType" SG_ 2463978881 BedienDisp_hfs_sound 4;
BA_ "GenSigSwitchedByIgnition" SG_ 2463978881 BedienDisp_hfs_sound 0;
BA_ "GenSigSendType" SG_ 2463978881 BedienDisp_hfs_sound_fokus 4;
BA_ "GenSigSwitchedByIgnition" SG_ 2463978881 BedienDisp_hfs_sound_fokus 0;
BA_ "Fehlerwert" SG_ 2463978881 BedienDisp_hfs_sound_fokus 15;
BA_ "GenSigSendType" SG_ 2463978881 BedienDisp_hfs_surround 4;
BA_ "GenSigSwitchedByIgnition" SG_ 2463978881 BedienDisp_hfs_surround 0;
BA_ "Fehlerwert" SG_ 2463978881 BedienDisp_hfs_surround 15;
BA_ "GenSigSendType" SG_ 2463978881 BedienDisp_hfs_surround_02 4;
BA_ "Fehlerwert" SG_ 2463978881 BedienDisp_hfs_surround_02 127;
BA_ "GenSigSendType" SG_ 2463978881 BedienDisp_hfs_touch 4;
BA_ "GenSigSwitchedByIgnition" SG_ 2463978881 BedienDisp_hfs_touch 0;
BA_ "Fehlerwert" SG_ 2463978881 BedienDisp_hfs_touch 15;
BA_ "GenSigSendType" SG_ 2463978881 BedienDisp_hfs_UseCase_Pos 3;
BA_ "GenSigSwitchedByIgnition" SG_ 2463978881 BedienDisp_hfs_UseCase_Pos 0;
BA_ "GenSigSendType" SG_ 2463978881 BedienDisp_HFSFo_Bestaetigung 3;
BA_ "GenSigSwitchedByIgnition" SG_ 2463978881 BedienDisp_HFSFo_Bestaetigung 0;
BA_ "Fehlerwert" SG_ 2463978881 BedienDisp_HFSFo_Bestaetigung 3;
BA_ "GenSigSendType" SG_ 2463978881 BedienDisp_HFSFo_Stoerung 3;
BA_ "GenSigSwitchedByIgnition" SG_ 2463978881 BedienDisp_HFSFo_Stoerung 0;
BA_ "GenSigSendType" SG_ 2463978885 BedienDisp_hfs_02_BZ 0;
BA_ "GenSigFuncType" SG_ 2463978885 BedienDisp_hfs_02_BZ 1;
BA_ "GenSigSwitchedByIgnition" SG_ 2463978885 BedienDisp_hfs_02_BZ 0;
BA_ "GenSigSendType" SG_ 2463978885 BedienDisp_hfs_02_CRC 0;
BA_ "GenSigFuncType" SG_ 2463978885 BedienDisp_hfs_02_CRC 2;
BA_ "GenSigSwitchedByIgnition" SG_ 2463978885 BedienDisp_hfs_02_CRC 0;
BA_ "GenSigSendType" SG_ 2463978885 BedienDisp_hfs_BF_Hoehe 4;
BA_ "GenSigSwitchedByIgnition" SG_ 2463978885 BedienDisp_hfs_BF_Hoehe 0;
BA_ "Fehlerwert" SG_ 2463978885 BedienDisp_hfs_BF_Hoehe 3;
BA_ "GenSigSendType" SG_ 2463978885 BedienDisp_hfs_BF_Laengs 4;
BA_ "GenSigSwitchedByIgnition" SG_ 2463978885 BedienDisp_hfs_BF_Laengs 0;
BA_ "Fehlerwert" SG_ 2463978885 BedienDisp_hfs_BF_Laengs 5;
BA_ "GenSigSendType" SG_ 2463978885 BedienDisp_hfs_BF_Lehne 4;
BA_ "GenSigSwitchedByIgnition" SG_ 2463978885 BedienDisp_hfs_BF_Lehne 0;
BA_ "Fehlerwert" SG_ 2463978885 BedienDisp_hfs_BF_Lehne 5;
BA_ "GenSigSendType" SG_ 2463978885 BedienDisp_hfs_Cargo_Pos 4;
BA_ "GenSigSwitchedByIgnition" SG_ 2463978885 BedienDisp_hfs_Cargo_Pos 0;
BA_ "Fehlerwert" SG_ 2463978885 BedienDisp_hfs_Cargo_Pos 3;
BA_ "GenSigSendType" SG_ 2463978885 BedienDisp_hfs_Komfor_Pos 4;
BA_ "GenSigSwitchedByIgnition" SG_ 2463978885 BedienDisp_hfs_Komfor_Pos 0;
BA_ "GenSigSendType" SG_ 2463978885 BedienDisp_hfs_Mem_Start 4;
BA_ "GenSigSwitchedByIgnition" SG_ 2463978885 BedienDisp_hfs_Mem_Start 0;
BA_ "Fehlerwert" SG_ 2463978885 BedienDisp_hfs_Mem_Start 3;
BA_ "GenSigSendType" SG_ 2463978885 BedienDisp_hfs_Memo_Pos 4;
BA_ "GenSigSwitchedByIgnition" SG_ 2463978885 BedienDisp_hfs_Memo_Pos 0;
BA_ "GenSigSendType" SG_ 2463978885 BedienDisp_hfs_Normal_Pos 4;
BA_ "GenSigSwitchedByIgnition" SG_ 2463978885 BedienDisp_hfs_Normal_Pos 0;
BA_ "Fehlerwert" SG_ 2463978885 BedienDisp_hfs_Normal_Pos 3;
BA_ "GenSigSendType" SG_ 2463978885 BedienDisp_hfs_Seat_SetReset 4;
BA_ "GenSigSwitchedByIgnition" SG_ 2463978885 BedienDisp_hfs_Seat_SetReset 0;
BA_ "GenSigSendType" SG_ 2463978885 BedienDisp_hfs_Seat_Storage 4;
BA_ "GenSigSwitchedByIgnition" SG_ 2463978885 BedienDisp_hfs_Seat_Storage 0;
BA_ "GenSigSendType" SG_ 2463978885 BedienDisp_hfs_Sitz_Arm 4;
BA_ "GenSigSwitchedByIgnition" SG_ 2463978885 BedienDisp_hfs_Sitz_Arm 0;
BA_ "Fehlerwert" SG_ 2463978885 BedienDisp_hfs_Sitz_Arm 5;
BA_ "GenSigSendType" SG_ 2463978885 BedienDisp_hfs_Sitz_Bein 4;
BA_ "GenSigSwitchedByIgnition" SG_ 2463978885 BedienDisp_hfs_Sitz_Bein 0;
BA_ "Fehlerwert" SG_ 2463978885 BedienDisp_hfs_Sitz_Bein 5;
BA_ "GenSigSendType" SG_ 2463978885 BedienDisp_hfs_Sitz_Hoehe 4;
BA_ "GenSigSwitchedByIgnition" SG_ 2463978885 BedienDisp_hfs_Sitz_Hoehe 0;
BA_ "Fehlerwert" SG_ 2463978885 BedienDisp_hfs_Sitz_Hoehe 3;
BA_ "GenSigSendType" SG_ 2463978885 BedienDisp_hfs_Sitz_Kopf 4;
BA_ "GenSigSwitchedByIgnition" SG_ 2463978885 BedienDisp_hfs_Sitz_Kopf 0;
BA_ "Fehlerwert" SG_ 2463978885 BedienDisp_hfs_Sitz_Kopf 5;
BA_ "GenSigSendType" SG_ 2463978885 BedienDisp_hfs_Sitz_Laengs 4;
BA_ "GenSigSwitchedByIgnition" SG_ 2463978885 BedienDisp_hfs_Sitz_Laengs 0;
BA_ "Fehlerwert" SG_ 2463978885 BedienDisp_hfs_Sitz_Laengs 5;
BA_ "GenSigSendType" SG_ 2463978885 BedienDisp_hfs_Sitz_Lehne 4;
BA_ "GenSigSwitchedByIgnition" SG_ 2463978885 BedienDisp_hfs_Sitz_Lehne 0;
BA_ "Fehlerwert" SG_ 2463978885 BedienDisp_hfs_Sitz_Lehne 5;
BA_ "GenSigSendType" SG_ 2463978885 BedienDisp_hfs_Sitz_Lehnekopf 4;
BA_ "GenSigSwitchedByIgnition" SG_ 2463978885 BedienDisp_hfs_Sitz_Lehnekopf 0;
BA_ "Fehlerwert" SG_ 2463978885 BedienDisp_hfs_Sitz_Lehnekopf 3;
BA_ "GenSigSendType" SG_ 2463978885 BedienDisp_hfs_Sitz_Neigung 4;
BA_ "GenSigSwitchedByIgnition" SG_ 2463978885 BedienDisp_hfs_Sitz_Neigung 0;
BA_ "Fehlerwert" SG_ 2463978885 BedienDisp_hfs_Sitz_Neigung 5;
BA_ "GenSigSendType" SG_ 2463978885 BedienDisp_hfs_Sitz_Stop 4;
BA_ "GenSigSwitchedByIgnition" SG_ 2463978885 BedienDisp_hfs_Sitz_Stop 0;
BA_ "Fehlerwert" SG_ 2463978885 BedienDisp_hfs_Sitz_Stop 3;
BA_ "GenSigSendType" SG_ 2463978863 BedienDisp_vm_Aktive_Ebene 3;
BA_ "GenSigSwitchedByIgnition" SG_ 2463978863 BedienDisp_vm_Aktive_Ebene 0;
BA_ "GenSigSendType" SG_ 2463978863 BedienDisp_vm_Control 3;
BA_ "GenSigSwitchedByIgnition" SG_ 2463978863 BedienDisp_vm_Control 0;
BA_ "Fehlerwert" SG_ 2463978863 BedienDisp_vm_Control 15;
BA_ "GenSigSendType" SG_ 2463978863 BedienDisp_vm_defekt 3;
BA_ "GenSigSwitchedByIgnition" SG_ 2463978863 BedienDisp_vm_defekt 0;
BA_ "GenSigSendType" SG_ 2463978863 BedienDisp_vm_Function 3;
BA_ "GenSigSwitchedByIgnition" SG_ 2463978863 BedienDisp_vm_Function 0;
BA_ "GenSigSendType" SG_ 2463978863 BedienDisp_vm_Ist_Profil 3;
BA_ "GenSigSwitchedByIgnition" SG_ 2463978863 BedienDisp_vm_Ist_Profil 0;
BA_ "GenSigSendType" SG_ 2463978863 BedienDisp_vm_Press 3;
BA_ "GenSigSwitchedByIgnition" SG_ 2463978863 BedienDisp_vm_Press 0;
BA_ "Fehlerwert" SG_ 2463978863 BedienDisp_vm_Press 15;
BA_ "GenSigSendType" SG_ 2463978863 BedienDisp_vm_Taster 3;
BA_ "GenSigSwitchedByIgnition" SG_ 2463978863 BedienDisp_vm_Taster 0;
BA_ "GenSigSendType" SG_ 2463978863 BedienDisp_vm_Touch 3;
BA_ "GenSigSwitchedByIgnition" SG_ 2463978863 BedienDisp_vm_Touch 0;
BA_ "Fehlerwert" SG_ 2463978863 BedienDisp_vm_Touch 15;
BA_ "GenSigSendType" SG_ 1635 BEM_Anf_KL15_schalten 0;
BA_ "GenSigSwitchedByIgnition" SG_ 1635 BEM_Anf_KL15_schalten 0;
BA_ "GenSigSendType" SG_ 1635 BEM_Batt_Ab 0;
BA_ "GenSigSwitchedByIgnition" SG_ 1635 BEM_Batt_Ab 0;
BA_ "GenSigSendType" SG_ 1635 BEM_Batteriediagnose 0;
BA_ "GenSigSwitchedByIgnition" SG_ 1635 BEM_Batteriediagnose 0;
BA_ "Fehlerwert" SG_ 1635 BEM_Batteriediagnose 7;
BA_ "GenSigSendType" SG_ 1635 BEM_DFM 0;
BA_ "GenSigSwitchedByIgnition" SG_ 1635 BEM_DFM 0;
BA_ "GenSigSendType" SG_ 1635 BEM_EMLIN_ungueltig 0;
BA_ "GenSigSwitchedByIgnition" SG_ 1635 BEM_EMLIN_ungueltig 0;
BA_ "GenSigSendType" SG_ 1635 BEM_Generatordiagnose 0;
BA_ "GenSigSwitchedByIgnition" SG_ 1635 BEM_Generatordiagnose 0;
BA_ "GenSigSendType" SG_ 1635 BEM_HL_Kontingentierung 0;
BA_ "GenSigSwitchedByIgnition" SG_ 1635 BEM_HL_Kontingentierung 0;
BA_ "GenSigSendType" SG_ 1635 BEM_HL_Regelung_Status 0;
BA_ "GenSigSwitchedByIgnition" SG_ 1635 BEM_HL_Regelung_Status 0;
BA_ "GenSigSendType" SG_ 1635 BEM_Ladezustand 0;
BA_ "GenSigStartValue" SG_ 1635 BEM_Ladezustand 14;
BA_ "GenSigSwitchedByIgnition" SG_ 1635 BEM_Ladezustand 0;
BA_ "Fehlerwert" SG_ 1635 BEM_Ladezustand 15;
BA_ "GenSigSendType" SG_ 1635 BEM_MMI_Vorwarnung 0;
BA_ "GenSigSwitchedByIgnition" SG_ 1635 BEM_MMI_Vorwarnung 0;
BA_ "GenSigSendType" SG_ 1635 BEM_Red_Innengeblaese 0;
BA_ "GenSigSwitchedByIgnition" SG_ 1635 BEM_Red_Innengeblaese 0;
BA_ "GenSigSendType" SG_ 1635 BEM_REK_aktiv 0;
BA_ "GenSigSwitchedByIgnition" SG_ 1635 BEM_REK_aktiv 0;
BA_ "GenSigSendType" SG_ 1635 BEM_STH_Einschaltverbot 0;
BA_ "GenSigSwitchedByIgnition" SG_ 1635 BEM_STH_Einschaltverbot 0;
BA_ "GenSigSendType" SG_ 1635 BEM_STH_Zielzeit 0;
BA_ "GenSigStartValue" SG_ 1635 BEM_STH_Zielzeit 14;
BA_ "GenSigSwitchedByIgnition" SG_ 1635 BEM_STH_Zielzeit 0;
BA_ "Fehlerwert" SG_ 1635 BEM_STH_Zielzeit 15;
BA_ "GenSigSendType" SG_ 1635 BEM_UBDM 0;
BA_ "GenSigSwitchedByIgnition" SG_ 1635 BEM_UBDM 0;
BA_ "Fehlerwert" SG_ 1635 BEM_UBDM 255;
BA_ "GenSigSendType" SG_ 1635 BEM_UGenSoll 0;
BA_ "GenSigSwitchedByIgnition" SG_ 1635 BEM_UGenSoll 0;
BA_ "GenSigSendType" SG_ 1635 MIB_Stromsparmodus 0;
BA_ "GenSigSwitchedByIgnition" SG_ 1635 MIB_Stromsparmodus 0;
BA_ "GenSigSendType" SG_ 1635 NVEM_Abschaltstufe 0;
BA_ "GenSigSwitchedByIgnition" SG_ 1635 NVEM_Abschaltstufe 0;
BA_ "GenSigSendType" SG_ 1635 NVEM_Anf_SD_schalten 0;
BA_ "GenSigSwitchedByIgnition" SG_ 1635 NVEM_Anf_SD_schalten 0;
BA_ "GenSigSendType" SG_ 1635 NVEM_Batterie_Service 0;
BA_ "GenSigSwitchedByIgnition" SG_ 1635 NVEM_Batterie_Service 0;
BA_ "GenSigSendType" SG_ 1635 NVEM_Freigabe_OnlineUpdate 0;
BA_ "GenSigSwitchedByIgnition" SG_ 1635 NVEM_Freigabe_OnlineUpdate 0;
BA_ "GenSigSendType" SG_ 1635 NVEM_Freigabe_ORU4 0;
BA_ "GenSigSwitchedByIgnition" SG_ 1635 NVEM_Freigabe_ORU4 0;
BA_ "GenSigSendType" SG_ 1635 NVEM_Freigabe_ZusBatt_Laden 0;
BA_ "GenSigSwitchedByIgnition" SG_ 1635 NVEM_Freigabe_ZusBatt_Laden 0;
BA_ "GenSigSendType" SG_ 1635 NVEM_Verbraucherabsch_Anz 0;
BA_ "GenSigSwitchedByIgnition" SG_ 1635 NVEM_Verbraucherabsch_Anz 0;
BA_ "GenSigSendType" SG_ 2463978850 BEM_07_BZ 0;
BA_ "GenSigFuncType" SG_ 2463978850 BEM_07_BZ 1;
BA_ "GenSigSwitchedByIgnition" SG_ 2463978850 BEM_07_BZ 0;
BA_ "GenSigSendType" SG_ 2463978850 BEM_07_CRC 0;
BA_ "GenSigFuncType" SG_ 2463978850 BEM_07_CRC 2;
BA_ "GenSigSwitchedByIgnition" SG_ 2463978850 BEM_07_CRC 0;
BA_ "GenSigSendType" SG_ 2463978850 NVEM2_VerbrZustandsAnf 0;
BA_ "GenSigStartValue" SG_ 2463978850 NVEM2_VerbrZustandsAnf 14;
BA_ "GenSigSwitchedByIgnition" SG_ 2463978850 NVEM2_VerbrZustandsAnf 0;
BA_ "Fehlerwert" SG_ 2463978850 NVEM2_VerbrZustandsAnf 15;
BA_ "GenSigSendType" SG_ 2463978850 NVEM3_Absch_SCR 0;
BA_ "GenSigSwitchedByIgnition" SG_ 2463978850 NVEM3_Absch_SCR 0;
BA_ "GenSigSendType" SG_ 2463978850 NVEM_Batt_Temp_Hinweis 0;
BA_ "GenSigSwitchedByIgnition" SG_ 2463978850 NVEM_Batt_Temp_Hinweis 0;
BA_ "GenSigSendType" SG_ 2463978850 NVEM_Bordnetz_Information 0;
BA_ "GenSigStartValue" SG_ 2463978850 NVEM_Bordnetz_Information 14;
BA_ "GenSigSwitchedByIgnition" SG_ 2463978850 NVEM_Bordnetz_Information 0;
BA_ "Fehlerwert" SG_ 2463978850 NVEM_Bordnetz_Information 15;
BA_ "GenSigSendType" SG_ 2463978850 NVEM_NVStuetzungAnf 0;
BA_ "GenSigSwitchedByIgnition" SG_ 2463978850 NVEM_NVStuetzungAnf 0;
BA_ "Fehlerwert" SG_ 2463978850 NVEM_NVStuetzungAnf 3;
BA_ "GenSigSendType" SG_ 2463978850 NVEM_Verbraucher_Information 0;
BA_ "GenSigStartValue" SG_ 2463978850 NVEM_Verbraucher_Information 6;
BA_ "GenSigSwitchedByIgnition" SG_ 2463978850 NVEM_Verbraucher_Information 0;
BA_ "Fehlerwert" SG_ 2463978850 NVEM_Verbraucher_Information 7;
BA_ "GenSigSendType" SG_ 870 Blinken_li_Fzg_Takt 4;
BA_ "GenSigSwitchedByIgnition" SG_ 870 Blinken_li_Fzg_Takt 0;
BA_ "GenSigSendType" SG_ 870 Blinken_li_Kombi_Takt 4;
BA_ "GenSigSwitchedByIgnition" SG_ 870 Blinken_li_Kombi_Takt 0;
BA_ "GenSigSendType" SG_ 870 Blinken_re_Fzg_Takt 4;
BA_ "GenSigSwitchedByIgnition" SG_ 870 Blinken_re_Fzg_Takt 0;
BA_ "GenSigSendType" SG_ 870 Blinken_re_Kombi_Takt 4;
BA_ "GenSigSwitchedByIgnition" SG_ 870 Blinken_re_Kombi_Takt 0;
BA_ "GenSigSendType" SG_ 870 Blinkmodi_02_BZ 0;
BA_ "GenSigFuncType" SG_ 870 Blinkmodi_02_BZ 1;
BA_ "GenSigSwitchedByIgnition" SG_ 870 Blinkmodi_02_BZ 0;
BA_ "GenSigSendType" SG_ 870 Blinkmodi_02_CRC 0;
BA_ "GenSigFuncType" SG_ 870 Blinkmodi_02_CRC 2;
BA_ "GenSigSwitchedByIgnition" SG_ 870 Blinkmodi_02_CRC 0;
BA_ "GenSigSendType" SG_ 870 BM_Autobahn 4;
BA_ "GenSigSwitchedByIgnition" SG_ 870 BM_Autobahn 0;
BA_ "GenSigSendType" SG_ 870 BM_Crash 4;
BA_ "GenSigSwitchedByIgnition" SG_ 870 BM_Crash 0;
BA_ "GenSigSendType" SG_ 870 BM_DWA_Alarm 4;
BA_ "GenSigSwitchedByIgnition" SG_ 870 BM_DWA_Alarm 0;
BA_ "GenSigSendType" SG_ 870 BM_DWA_ein 4;
BA_ "GenSigSwitchedByIgnition" SG_ 870 BM_DWA_ein 0;
BA_ "GenSigSendType" SG_ 870 BM_GDO 4;
BA_ "GenSigSwitchedByIgnition" SG_ 870 BM_GDO 0;
BA_ "GenSigSendType" SG_ 870 BM_HD_Oeffnung_angelernt 3;
BA_ "GenSigSwitchedByIgnition" SG_ 870 BM_HD_Oeffnung_angelernt 0;
BA_ "GenSigSendType" SG_ 870 BM_links 4;
BA_ "GenSigSwitchedByIgnition" SG_ 870 BM_links 0;
BA_ "GenSigSendType" SG_ 870 BM_NBA_n_codiert_n_aktiv 3;
BA_ "GenSigStartValue" SG_ 870 BM_NBA_n_codiert_n_aktiv 1;
BA_ "GenSigSwitchedByIgnition" SG_ 870 BM_NBA_n_codiert_n_aktiv 0;
BA_ "GenSigSendType" SG_ 870 BM_NBA_Status 4;
BA_ "GenSigSwitchedByIgnition" SG_ 870 BM_NBA_Status 0;
BA_ "GenSigSendType" SG_ 870 BM_Not_Bremsung 4;
BA_ "GenSigSwitchedByIgnition" SG_ 870 BM_Not_Bremsung 0;
BA_ "GenSigSendType" SG_ 870 BM_Panik 4;
BA_ "GenSigSwitchedByIgnition" SG_ 870 BM_Panik 0;
BA_ "GenSigSendType" SG_ 870 BM_PiloPa 4;
BA_ "GenSigSwitchedByIgnition" SG_ 870 BM_PiloPa 0;
BA_ "GenSigSendType" SG_ 870 BM_Recas 5;
BA_ "GenSigSwitchedByIgnition" SG_ 870 BM_Recas 0;
BA_ "GenSigSendType" SG_ 870 BM_rechts 4;
BA_ "GenSigSwitchedByIgnition" SG_ 870 BM_rechts 0;
BA_ "GenSigSendType" SG_ 870 BM_Rollenmodus_Blinken 5;
BA_ "GenSigSwitchedByIgnition" SG_ 870 BM_Rollenmodus_Blinken 0;
BA_ "GenSigSendType" SG_ 870 BM_Taxi_Notalarm 4;
BA_ "GenSigSwitchedByIgnition" SG_ 870 BM_Taxi_Notalarm 0;
BA_ "GenSigSendType" SG_ 870 BM_Telematik 4;
BA_ "GenSigSwitchedByIgnition" SG_ 870 BM_Telematik 0;
BA_ "GenSigSendType" SG_ 870 BM_Telematik_Abbruchgrund 4;
BA_ "GenSigSwitchedByIgnition" SG_ 870 BM_Telematik_Abbruchgrund 0;
BA_ "GenSigSendType" SG_ 870 BM_Warnblinken 4;
BA_ "GenSigSwitchedByIgnition" SG_ 870 BM_Warnblinken 0;
BA_ "GenSigSendType" SG_ 870 BM_WBA_Warnblinken 4;
BA_ "GenSigSwitchedByIgnition" SG_ 870 BM_WBA_Warnblinken 0;
BA_ "GenSigSendType" SG_ 870 BM_WBT_Beleuchtung 3;
BA_ "GenSigSwitchedByIgnition" SG_ 870 BM_WBT_Beleuchtung 0;
BA_ "GenSigSendType" SG_ 870 BM_Wischblinken 4;
BA_ "GenSigSwitchedByIgnition" SG_ 870 BM_Wischblinken 0;
BA_ "GenSigSendType" SG_ 870 BM_ZV_auf 4;
BA_ "GenSigSwitchedByIgnition" SG_ 870 BM_ZV_auf 0;
BA_ "GenSigSendType" SG_ 870 BM_ZV_zu 4;
BA_ "GenSigSwitchedByIgnition" SG_ 870 BM_ZV_zu 0;
BA_ "GenSigSendType" SG_ 870 SAL_RHP_Blinken_Status 3;
BA_ "GenSigSwitchedByIgnition" SG_ 870 SAL_RHP_Blinken_Status 0;
BA_ "GenSigSendType" SG_ 870 SAL_RHP_Warnblinken 3;
BA_ "GenSigSwitchedByIgnition" SG_ 870 SAL_RHP_Warnblinken 0;
BA_ "GenSigSendType" SG_ 870 SAL_TA_Blinken_Status 4;
BA_ "GenSigSwitchedByIgnition" SG_ 870 SAL_TA_Blinken_Status 0;
BA_ "GenSigSendType" SG_ 2589283664 BMS_Balancing_Aktiv 0;
BA_ "GenSigSwitchedByIgnition" SG_ 2589283664 BMS_Balancing_Aktiv 0;
BA_ "GenSigSendType" SG_ 2589283664 BMS_Ladevorgang_aktiv 0;
BA_ "GenSigSwitchedByIgnition" SG_ 2589283664 BMS_Ladevorgang_aktiv 0;
BA_ "GenSigSendType" SG_ 2589283664 BMS_Max_Energie 0;
BA_ "GenSigStartValue" SG_ 2589283664 BMS_Max_Energie 8190;
BA_ "GenSigSwitchedByIgnition" SG_ 2589283664 BMS_Max_Energie 0;
BA_ "GenSigSendType" SG_ 2589283664 BMS_Max_Ladezustand 0;
BA_ "GenSigStartValue" SG_ 2589283664 BMS_Max_Ladezustand 2046;
BA_ "GenSigSwitchedByIgnition" SG_ 2589283664 BMS_Max_Ladezustand 0;
BA_ "GenSigSendType" SG_ 2589283664 BMS_Min_Ladezustand 0;
BA_ "GenSigStartValue" SG_ 2589283664 BMS_Min_Ladezustand 2046;
BA_ "GenSigSwitchedByIgnition" SG_ 2589283664 BMS_Min_Ladezustand 0;
BA_ "GenSigSendType" SG_ 2589283664 BMS_RIso_Ext 0;
BA_ "GenSigStartValue" SG_ 2589283664 BMS_RIso_Ext 4094;
BA_ "GenSigSwitchedByIgnition" SG_ 2589283664 BMS_RIso_Ext 0;
BA_ "Fehlerwert" SG_ 2589283664 BMS_RIso_Ext 4095;
BA_ "GenSigSendType" SG_ 2589283941 CHA_Drehschalter_AktivesProfil 3;
BA_ "GenSigSwitchedByIgnition" SG_ 2589283941 CHA_Drehschalter_AktivesProfil 0;
BA_ "GenSigSendType" SG_ 2589283941 CHA_Drehschalter_Profil_1 0;
BA_ "GenSigSwitchedByIgnition" SG_ 2589283941 CHA_Drehschalter_Profil_1 0;
BA_ "GenSigSendType" SG_ 2589283941 CHA_Drehschalter_Profil_2 0;
BA_ "GenSigSwitchedByIgnition" SG_ 2589283941 CHA_Drehschalter_Profil_2 0;
BA_ "GenSigSendType" SG_ 2589283941 CHA_Drehschalter_Profil_3 0;
BA_ "GenSigSwitchedByIgnition" SG_ 2589283941 CHA_Drehschalter_Profil_3 0;
BA_ "GenSigSendType" SG_ 2589283941 CHA_Drehschalter_Profil_4 0;
BA_ "GenSigSwitchedByIgnition" SG_ 2589283941 CHA_Drehschalter_Profil_4 0;
BA_ "GenSigSendType" SG_ 2589283941 CHA_Drehschalter_Profil_5 0;
BA_ "GenSigSwitchedByIgnition" SG_ 2589283941 CHA_Drehschalter_Profil_5 0;
BA_ "GenSigSendType" SG_ 2589283941 CHA_Drehschalter_Profil_6 0;
BA_ "GenSigSwitchedByIgnition" SG_ 2589283941 CHA_Drehschalter_Profil_6 0;
BA_ "GenSigSendType" SG_ 2589283941 CHA_Drehschalter_Profil_7 0;
BA_ "GenSigSwitchedByIgnition" SG_ 2589283941 CHA_Drehschalter_Profil_7 0;
BA_ "GenSigSendType" SG_ 902 CHA_Charge_LED 3;
BA_ "GenSigSwitchedByIgnition" SG_ 902 CHA_Charge_LED 0;
BA_ "GenSigSendType" SG_ 902 CHA_Charisma_Taste2_LED 3;
BA_ "GenSigSwitchedByIgnition" SG_ 902 CHA_Charisma_Taste2_LED 0;
BA_ "Fehlerwert" SG_ 902 CHA_Charisma_Taste2_LED 3;
BA_ "GenSigSendType" SG_ 902 CHA_Current_Mode 3;
BA_ "GenSigSwitchedByIgnition" SG_ 902 CHA_Current_Mode 0;
BA_ "GenSigSendType" SG_ 902 CHA_Current_Mode_FPA 3;
BA_ "GenSigSwitchedByIgnition" SG_ 902 CHA_Current_Mode_FPA 0;
BA_ "GenSigSendType" SG_ 902 CHA_Eco_Charisma_LED 3;
BA_ "GenSigSwitchedByIgnition" SG_ 902 CHA_Eco_Charisma_LED 0;
BA_ "GenSigSendType" SG_ 902 CHA_EV_LED 3;
BA_ "GenSigSwitchedByIgnition" SG_ 902 CHA_EV_LED 0;
BA_ "GenSigSendType" SG_ 902 CHA_Fahrer_Umschaltung 3;
BA_ "GenSigSwitchedByIgnition" SG_ 902 CHA_Fahrer_Umschaltung 0;
BA_ "GenSigSendType" SG_ 902 CHA_Kombi_Texte 3;
BA_ "GenSigSwitchedByIgnition" SG_ 902 CHA_Kombi_Texte 0;
BA_ "GenSigSendType" SG_ 902 CHA_Kombi_Texte_02 3;
BA_ "GenSigSwitchedByIgnition" SG_ 902 CHA_Kombi_Texte_02 0;
BA_ "GenSigSendType" SG_ 902 CHA_Offroad_LED 3;
BA_ "GenSigSwitchedByIgnition" SG_ 902 CHA_Offroad_LED 0;
BA_ "Fehlerwert" SG_ 902 CHA_Offroad_LED 3;
BA_ "GenSigSendType" SG_ 902 CHA_ReqPrgDispSetup 3;
BA_ "GenSigSwitchedByIgnition" SG_ 902 CHA_ReqPrgDispSetup 0;
BA_ "GenSigSendType" SG_ 902 CHA_StCurProfDft 3;
BA_ "GenSigSwitchedByIgnition" SG_ 902 CHA_StCurProfDft 0;
BA_ "GenSigSendType" SG_ 902 CHA_Ziel_FahrPr_03_01 3;
BA_ "GenSigSwitchedByIgnition" SG_ 902 CHA_Ziel_FahrPr_03_01 0;
BA_ "GenSigSendType" SG_ 902 CHA_Ziel_FahrPr_03_02 3;
BA_ "GenSigSwitchedByIgnition" SG_ 902 CHA_Ziel_FahrPr_03_02 0;
BA_ "GenSigSendType" SG_ 902 CHA_Ziel_FahrPr_AMB 3;
BA_ "GenSigSwitchedByIgnition" SG_ 902 CHA_Ziel_FahrPr_AMB 0;
BA_ "GenSigSendType" SG_ 902 CHA_Ziel_FahrPr_HSP 3;
BA_ "GenSigSwitchedByIgnition" SG_ 902 CHA_Ziel_FahrPr_HSP 0;
BA_ "GenSigSendType" SG_ 902 CHA_Ziel_FahrPr_IVB 3;
BA_ "GenSigSwitchedByIgnition" SG_ 902 CHA_Ziel_FahrPr_IVB 0;
BA_ "GenSigSendType" SG_ 902 CHA_Ziel_FahrPr_KL 3;
BA_ "GenSigSwitchedByIgnition" SG_ 902 CHA_Ziel_FahrPr_KL 0;
BA_ "GenSigSendType" SG_ 902 CHA_Ziel_FahrPr_RWB 3;
BA_ "GenSigSwitchedByIgnition" SG_ 902 CHA_Ziel_FahrPr_RWB 0;
BA_ "GenSigSendType" SG_ 2527679921 CPD_CallCenter 3;
BA_ "GenSigSwitchedByIgnition" SG_ 2527679921 CPD_CallCenter 0;
BA_ "GenSigSendType" SG_ 2527679921 CPD_Deaktivierung_Permanent 3;
BA_ "GenSigSwitchedByIgnition" SG_ 2527679921 CPD_Deaktivierung_Permanent 0;
BA_ "GenSigSendType" SG_ 2527679921 CPD_Deaktivierung_Temp 3;
BA_ "GenSigSwitchedByIgnition" SG_ 2527679921 CPD_Deaktivierung_Temp 0;
BA_ "GenSigSendType" SG_ 2527679921 CPD_Mobiltelefon_BLE 3;
BA_ "GenSigSwitchedByIgnition" SG_ 2527679921 CPD_Mobiltelefon_BLE 0;
BA_ "GenSigSendType" SG_ 2527679921 CPD_Mobiltelefon_GSM 3;
BA_ "GenSigSwitchedByIgnition" SG_ 2527679921 CPD_Mobiltelefon_GSM 0;
BA_ "GenSigSendType" SG_ 2527679921 CPDFct_Deakt 3;
BA_ "GenSigSwitchedByIgnition" SG_ 2527679921 CPDFct_Deakt 0;
BA_ "GenSigSendType" SG_ 2527679921 CPDFct_Symbol 0;
BA_ "GenSigSwitchedByIgnition" SG_ 2527679921 CPDFct_Symbol 0;
BA_ "GenSigSendType" SG_ 2527679921 CPDFct_Warnung 0;
BA_ "GenSigSwitchedByIgnition" SG_ 2527679921 CPDFct_Warnung 0;
BA_ "GenSigSendType" SG_ 2549880334 DIA_ABT_1_Req_Data 3;
BA_ "GenSigFuncType" SG_ 2549880334 DIA_ABT_1_Req_Data 9;
BA_ "GenSigSwitchedByIgnition" SG_ 2549880334 DIA_ABT_1_Req_Data 0;
BA_ "GenSigSendType" SG_ 2550011406 DIA_ABT_1_Resp_Data 3;
BA_ "GenSigFuncType" SG_ 2550011406 DIA_ABT_1_Resp_Data 9;
BA_ "GenSigSwitchedByIgnition" SG_ 2550011406 DIA_ABT_1_Resp_Data 0;
BA_ "GenSigSendType" SG_ 1714 DGN_Verlernzaehler 0;
BA_ "GenSigSwitchedByIgnition" SG_ 1714 DGN_Verlernzaehler 0;
BA_ "GenSigSendType" SG_ 1714 KBI_Kilometerstand 0;
BA_ "GenSigStartValue" SG_ 1714 KBI_Kilometerstand 1048574;
BA_ "GenSigSwitchedByIgnition" SG_ 1714 KBI_Kilometerstand 0;
BA_ "Fehlerwert" SG_ 1714 KBI_Kilometerstand 1048575;
BA_ "GenSigSendType" SG_ 1714 Kombi_02_alt 0;
BA_ "GenSigStartValue" SG_ 1714 Kombi_02_alt 1;
BA_ "GenSigFuncType" SG_ 1714 Kombi_02_alt 5;
BA_ "GenSigSwitchedByIgnition" SG_ 1714 Kombi_02_alt 0;
BA_ "GenSigSendType" SG_ 1714 UH_Jahr 0;
BA_ "GenSigSwitchedByIgnition" SG_ 1714 UH_Jahr 0;
BA_ "GenSigSendType" SG_ 1714 UH_Minute 0;
BA_ "GenSigSwitchedByIgnition" SG_ 1714 UH_Minute 0;
BA_ "GenSigSendType" SG_ 1714 UH_Monat 0;
BA_ "GenSigSwitchedByIgnition" SG_ 1714 UH_Monat 0;
BA_ "Fehlerwert" SG_ 1714 UH_Monat 15;
BA_ "GenSigSendType" SG_ 1714 UH_Sekunde 0;
BA_ "GenSigSwitchedByIgnition" SG_ 1714 UH_Sekunde 0;
BA_ "GenSigSendType" SG_ 1714 UH_Stunde 0;
BA_ "GenSigSwitchedByIgnition" SG_ 1714 UH_Stunde 0;
BA_ "GenSigSendType" SG_ 1714 UH_Tag 0;
BA_ "GenSigSwitchedByIgnition" SG_ 1714 UH_Tag 0;
BA_ "GenSigSendType" SG_ 1714 Uhrzeit_01_alt 0;
BA_ "GenSigStartValue" SG_ 1714 Uhrzeit_01_alt 1;
BA_ "GenSigFuncType" SG_ 1714 Uhrzeit_01_alt 5;
BA_ "GenSigSwitchedByIgnition" SG_ 1714 Uhrzeit_01_alt 0;
BA_ "GenSigSendType" SG_ 1714 Vehicle_Driving_Cycle 0;
BA_ "GenSigSwitchedByIgnition" SG_ 1714 Vehicle_Driving_Cycle 0;
BA_ "GenSigSendType" SG_ 851 DiETa_Car 0;
BA_ "GenSigSwitchedByIgnition" SG_ 851 DiETa_Car 0;
BA_ "Fehlerwert" SG_ 851 DiETa_Car 3;
BA_ "GenSigSendType" SG_ 851 DiETa_Defrost_Taste 0;
BA_ "GenSigSwitchedByIgnition" SG_ 851 DiETa_Defrost_Taste 0;
BA_ "Fehlerwert" SG_ 851 DiETa_Defrost_Taste 3;
BA_ "GenSigSendType" SG_ 851 DiETa_FAS_Stufe 0;
BA_ "GenSigSwitchedByIgnition" SG_ 851 DiETa_FAS_Stufe 0;
BA_ "Fehlerwert" SG_ 851 DiETa_FAS_Stufe 3;
BA_ "GenSigSendType" SG_ 851 DiETa_FSH_Taste 0;
BA_ "GenSigSwitchedByIgnition" SG_ 851 DiETa_FSH_Taste 0;
BA_ "Fehlerwert" SG_ 851 DiETa_FSH_Taste 3;
BA_ "GenSigSendType" SG_ 851 DiETa_HSH_Taste 0;
BA_ "GenSigSwitchedByIgnition" SG_ 851 DiETa_HSH_Taste 0;
BA_ "Fehlerwert" SG_ 851 DiETa_HSH_Taste 3;
BA_ "GenSigSendType" SG_ 851 DiETa_Klima 0;
BA_ "GenSigSwitchedByIgnition" SG_ 851 DiETa_Klima 0;
BA_ "Fehlerwert" SG_ 851 DiETa_Klima 3;
BA_ "GenSigSendType" SG_ 851 DiETa_Lock_Unlock_Taste 0;
BA_ "GenSigSwitchedByIgnition" SG_ 851 DiETa_Lock_Unlock_Taste 0;
BA_ "Fehlerwert" SG_ 851 DiETa_Lock_Unlock_Taste 7;
BA_ "GenSigSendType" SG_ 851 DiETa_Mode 0;
BA_ "GenSigSwitchedByIgnition" SG_ 851 DiETa_Mode 0;
BA_ "Fehlerwert" SG_ 851 DiETa_Mode 3;
BA_ "GenSigSendType" SG_ 851 DiETa_Mode2 0;
BA_ "GenSigSwitchedByIgnition" SG_ 851 DiETa_Mode2 0;
BA_ "Fehlerwert" SG_ 851 DiETa_Mode2 3;
BA_ "GenSigSendType" SG_ 851 DiETa_Mode_roh 0;
BA_ "GenSigSwitchedByIgnition" SG_ 851 DiETa_Mode_roh 0;
BA_ "GenSigSendType" SG_ 851 DiETa_PAO_OFF_Status 0;
BA_ "GenSigSwitchedByIgnition" SG_ 851 DiETa_PAO_OFF_Status 0;
BA_ "GenSigSendType" SG_ 851 DiETa_PAO_ON_Status 0;
BA_ "GenSigSwitchedByIgnition" SG_ 851 DiETa_PAO_ON_Status 0;
BA_ "GenSigSendType" SG_ 851 DiETa_Parken 0;
BA_ "GenSigSwitchedByIgnition" SG_ 851 DiETa_Parken 0;
BA_ "Fehlerwert" SG_ 851 DiETa_Parken 3;
BA_ "GenSigSendType" SG_ 851 DiETa_Reserve_Byte2_4 0;
BA_ "GenSigSwitchedByIgnition" SG_ 851 DiETa_Reserve_Byte2_4 0;
BA_ "GenSigSendType" SG_ 851 DiETa_Reserve_Byte6_6 0;
BA_ "GenSigSwitchedByIgnition" SG_ 851 DiETa_Reserve_Byte6_6 0;
BA_ "GenSigSendType" SG_ 851 DiETa_Reserve_Byte7_4 0;
BA_ "GenSigSwitchedByIgnition" SG_ 851 DiETa_Reserve_Byte7_4 0;
BA_ "GenSigSendType" SG_ 851 DiETa_Reserve_Byte8 0;
BA_ "GenSigSwitchedByIgnition" SG_ 851 DiETa_Reserve_Byte8 0;
BA_ "GenSigSendType" SG_ 851 DiETa_ResponseError 0;
BA_ "GenSigSwitchedByIgnition" SG_ 851 DiETa_ResponseError 0;
BA_ "Fehlerwert" SG_ 851 DiETa_ResponseError 1;
BA_ "GenSigSendType" SG_ 851 DiETa_Status 0;
BA_ "GenSigStartValue" SG_ 851 DiETa_Status 2;
BA_ "GenSigSwitchedByIgnition" SG_ 851 DiETa_Status 0;
BA_ "GenSigSendType" SG_ 851 DiETa_Touch_Event 0;
BA_ "GenSigSwitchedByIgnition" SG_ 851 DiETa_Touch_Event 0;
BA_ "Fehlerwert" SG_ 851 DiETa_Touch_Event 15;
BA_ "GenSigSendType" SG_ 851 DiETa_Warnblink_Taste 0;
BA_ "GenSigSwitchedByIgnition" SG_ 851 DiETa_Warnblink_Taste 0;
BA_ "Fehlerwert" SG_ 851 DiETa_Warnblink_Taste 3;
BA_ "GenSigSendType" SG_ 851 DiETas_01_BZ 0;
BA_ "GenSigFuncType" SG_ 851 DiETas_01_BZ 1;
BA_ "GenSigSwitchedByIgnition" SG_ 851 DiETas_01_BZ 0;
BA_ "GenSigSendType" SG_ 851 DiETas_01_CRC 0;
BA_ "GenSigFuncType" SG_ 851 DiETas_01_CRC 2;
BA_ "GenSigSwitchedByIgnition" SG_ 851 DiETas_01_CRC 0;
BA_ "GenSigSendType" SG_ 851 ESP_Off_Taster 0;
BA_ "GenSigStartValue" SG_ 851 ESP_Off_Taster 2;
BA_ "GenSigSwitchedByIgnition" SG_ 851 ESP_Off_Taster 0;
BA_ "Fehlerwert" SG_ 851 ESP_Off_Taster 3;
BA_REL_ "GenSigTimeoutTime" BU_SG_REL_ BedienDisp_mi SG_ 2463978607 BCM_RGB_Rot 2000;
BA_REL_ "GenSigTimeoutTime" BU_SG_REL_ BedienDisp_mi SG_ 2463978607 BCM_RGB_Gruen 2000;
BA_REL_ "GenSigTimeoutTime" BU_SG_REL_ BedienDisp_mi SG_ 2463978607 BCM_RGB_Blau 2000;
BA_REL_ "GenSigTimeoutTime" BU_SG_REL_ BedienDisp_mi SG_ 2463978607 BCM_RGB_Intensitaet 2000;
BA_REL_ "GenSigTimeoutTime" BU_SG_REL_ BedienDisp_mi SG_ 2463978607 BCM_RGB_Dimmrampe 2000;
BA_REL_ "GenSigTimeoutTime" BU_SG_REL_ BedienDisp_mi SG_ 2463978607 BCM_RGB_Dimmzeit_Zeitbasis 2000;
BA_REL_ "GenSigTimeoutTime" BU_SG_REL_ BedienDisp_mi SG_ 2589283941 CHA_Drehschalter_AktivesProfil 5000;
BA_REL_ "GenSigTimeoutTime" BU_SG_REL_ BedienDisp_mi SG_ 2589283941 CHA_Drehschalter_Profil_1 5000;
BA_REL_ "GenSigTimeoutTime" BU_SG_REL_ BedienDisp_mi SG_ 2589283941 CHA_Drehschalter_Profil_2 5000;
BA_REL_ "GenSigTimeoutTime" BU_SG_REL_ BedienDisp_mi SG_ 2589283941 CHA_Drehschalter_Profil_3 5000;
BA_REL_ "GenSigTimeoutTime" BU_SG_REL_ BedienDisp_mi SG_ 2589283941 CHA_Drehschalter_Profil_4 5000;
BA_REL_ "GenSigTimeoutTime" BU_SG_REL_ BedienDisp_mi SG_ 2589283941 CHA_Drehschalter_Profil_5 5000;
BA_REL_ "GenSigTimeoutTime" BU_SG_REL_ BedienDisp_mi SG_ 2589283941 CHA_Drehschalter_Profil_6 5000;
BA_REL_ "GenSigTimeoutTime" BU_SG_REL_ BedienDisp_mi SG_ 2589283941 CHA_Drehschalter_Profil_7 5000;
BA_REL_ "GenSigTimeoutTime" BU_SG_REL_ BedienDisp_mi SG_ 1714 DGN_Verlernzaehler 5000;
BA_REL_ "GenSigTimeoutTime" BU_SG_REL_ BedienDisp_mi SG_ 1714 KBI_Kilometerstand 5000;
BA_REL_ "GenSigTimeoutTime" BU_SG_REL_ BedienDisp_mi SG_ 1714 UH_Jahr 5000;
BA_REL_ "GenSigTimeoutTime" BU_SG_REL_ BedienDisp_mi SG_ 1714 UH_Monat 5000;
BA_REL_ "GenSigTimeoutTime" BU_SG_REL_ BedienDisp_mi SG_ 1714 UH_Tag 5000;
BA_REL_ "GenSigTimeoutTime" BU_SG_REL_ BedienDisp_mi SG_ 1714 UH_Stunde 5000;
BA_REL_ "GenSigTimeoutTime" BU_SG_REL_ BedienDisp_mi SG_ 1714 UH_Minute 5000;
BA_REL_ "GenSigTimeoutTime" BU_SG_REL_ BedienDisp_mi SG_ 1714 UH_Sekunde 5000;
BA_REL_ "GenSigTimeoutTime" BU_SG_REL_ BedienDisp_vo_mi SG_ 1626 BCM1_Licht_Warn 5000;
BA_REL_ "GenSigTimeoutTime" BU_SG_REL_ BedienDisp_vo_mi SG_ 2463978607 BCM_RGB_Rot 2000;
BA_REL_ "GenSigTimeoutTime" BU_SG_REL_ BedienDisp_vo_mi SG_ 2463978607 BCM_RGB_Gruen 2000;
BA_REL_ "GenSigTimeoutTime" BU_SG_REL_ BedienDisp_vo_mi SG_ 2463978607 BCM_RGB_Blau 2000;
BA_REL_ "GenSigTimeoutTime" BU_SG_REL_ BedienDisp_vo_mi SG_ 2463978607 BCM_RGB_Intensitaet 2000;
BA_REL_ "GenSigTimeoutTime" BU_SG_REL_ BedienDisp_vo_mi SG_ 2463978607 BCM_RGB_Dimmrampe 2000;
BA_REL_ "GenSigTimeoutTime" BU_SG_REL_ BedienDisp_vo_mi SG_ 2463978607 BCM_RGB_Dimmzeit_Zeitbasis 2000;
BA_REL_ "GenSigTimeoutTime" BU_SG_REL_ BedienDisp_vo_mi SG_ 1635 NVEM_Abschaltstufe 1000;
BA_REL_ "GenSigTimeoutTime" BU_SG_REL_ BedienDisp_vo_mi SG_ 2589283941 CHA_Drehschalter_AktivesProfil 5000;
BA_REL_ "GenSigTimeoutTime" BU_SG_REL_ BedienDisp_vo_mi SG_ 2589283941 CHA_Drehschalter_Profil_1 5000;
BA_REL_ "GenSigTimeoutTime" BU_SG_REL_ BedienDisp_vo_mi SG_ 2589283941 CHA_Drehschalter_Profil_2 5000;
BA_REL_ "GenSigTimeoutTime" BU_SG_REL_ BedienDisp_vo_mi SG_ 2589283941 CHA_Drehschalter_Profil_3 5000;
BA_REL_ "GenSigTimeoutTime" BU_SG_REL_ BedienDisp_vo_mi SG_ 2589283941 CHA_Drehschalter_Profil_4 5000;
BA_REL_ "GenSigTimeoutTime" BU_SG_REL_ BedienDisp_vo_mi SG_ 2589283941 CHA_Drehschalter_Profil_5 5000;
BA_REL_ "GenSigTimeoutTime" BU_SG_REL_ BedienDisp_vo_mi SG_ 2589283941 CHA_Drehschalter_Profil_6 5000;
BA_REL_ "GenSigTimeoutTime" BU_SG_REL_ BedienDisp_vo_mi SG_ 2589283941 CHA_Drehschalter_Profil_7 5000;
BA_REL_ "GenSigTimeoutTime" BU_SG_REL_ BedienDisp_vo_mi SG_ 1714 DGN_Verlernzaehler 5000;
BA_REL_ "GenSigTimeoutTime" BU_SG_REL_ BedienDisp_vo_mi SG_ 1714 KBI_Kilometerstand 5000;
BA_REL_ "GenSigTimeoutTime" BU_SG_REL_ BedienDisp_vo_mi SG_ 1714 UH_Jahr 5000;
BA_REL_ "GenSigTimeoutTime" BU_SG_REL_ BedienDisp_vo_mi SG_ 1714 UH_Monat 5000;
BA_REL_ "GenSigTimeoutTime" BU_SG_REL_ BedienDisp_vo_mi SG_ 1714 UH_Tag 5000;
BA_REL_ "GenSigTimeoutTime" BU_SG_REL_ BedienDisp_vo_mi SG_ 1714 UH_Stunde 5000;
BA_REL_ "GenSigTimeoutTime" BU_SG_REL_ BedienDisp_vo_mi SG_ 1714 UH_Minute 5000;
BA_REL_ "GenSigTimeoutTime" BU_SG_REL_ BedienDisp_vo_mi SG_ 1714 UH_Sekunde 5000;
BA_REL_ "GenSigTimeoutTime" BU_SG_REL_ CDI SG_ 2463978607 BCM_RGB_Rot 2000;
BA_REL_ "GenSigTimeoutTime" BU_SG_REL_ CDI SG_ 2463978607 BCM_RGB_Gruen 2000;
BA_REL_ "GenSigTimeoutTime" BU_SG_REL_ CDI SG_ 2463978607 BCM_RGB_Blau 2000;
BA_REL_ "GenSigTimeoutTime" BU_SG_REL_ CDI SG_ 2463978850 NVEM_Verbraucher_Information 1000;
BA_REL_ "GenSigTimeoutTime" BU_SG_REL_ CDI SG_ 1635 NVEM_Abschaltstufe 1000;
BA_REL_ "GenSigTimeoutTime" BU_SG_REL_ ConMod_CD SG_ 1714 DGN_Verlernzaehler 5000;
BA_REL_ "GenSigTimeoutTime" BU_SG_REL_ ConMod_CD SG_ 1714 KBI_Kilometerstand 5000;
BA_REL_ "GenSigTimeoutTime" BU_SG_REL_ ConMod_CD SG_ 1714 UH_Jahr 5000;
BA_REL_ "GenSigTimeoutTime" BU_SG_REL_ ConMod_CD SG_ 1714 UH_Monat 5000;
BA_REL_ "GenSigTimeoutTime" BU_SG_REL_ ConMod_CD SG_ 1714 UH_Tag 5000;
BA_REL_ "GenSigTimeoutTime" BU_SG_REL_ ConMod_CD SG_ 1714 UH_Stunde 5000;
BA_REL_ "GenSigTimeoutTime" BU_SG_REL_ ConMod_CD SG_ 1714 UH_Minute 5000;
BA_REL_ "GenSigTimeoutTime" BU_SG_REL_ ConMod_CD SG_ 1714 UH_Sekunde 5000;
BA_REL_ "GenSigTimeoutTime" BU_SG_REL_ ConMod_CD SG_ 1714 Vehicle_Driving_Cycle 5000;
BA_REL_ "GenSigTimeoutTime" BU_SG_REL_ ConMod_CD SG_ 1714 Kombi_02_alt 5000;
BA_REL_ "GenSigTimeoutTime" BU_SG_REL_ ConMod_CD SG_ 1714 Uhrzeit_01_alt 5000;
BA_REL_ "GenSigTimeoutTime" BU_SG_REL_ DashCAM SG_ 870 BM_links 5000;
BA_REL_ "GenSigTimeoutTime" BU_SG_REL_ DashCAM SG_ 870 BM_rechts 5000;
BA_REL_ "GenSigTimeoutTime" BU_SG_REL_ DashCAM SG_ 1714 DGN_Verlernzaehler 5000;
BA_REL_ "GenSigTimeoutTime" BU_SG_REL_ DashCAM SG_ 1714 KBI_Kilometerstand 5000;
BA_REL_ "GenSigTimeoutTime" BU_SG_REL_ DashCAM SG_ 1714 UH_Jahr 5000;
BA_REL_ "GenSigTimeoutTime" BU_SG_REL_ DashCAM SG_ 1714 UH_Monat 5000;
BA_REL_ "GenSigTimeoutTime" BU_SG_REL_ DashCAM SG_ 1714 UH_Tag 5000;
BA_REL_ "GenSigTimeoutTime" BU_SG_REL_ DashCAM SG_ 1714 UH_Stunde 5000;
BA_REL_ "GenSigTimeoutTime" BU_SG_REL_ DashCAM SG_ 1714 UH_Minute 5000;
BA_REL_ "GenSigTimeoutTime" BU_SG_REL_ DashCAM SG_ 1714 UH_Sekunde 5000;
BA_REL_ "GenSigTimeoutTime" BU_SG_REL_ DashCAM SG_ 1714 Kombi_02_alt 5000;
BA_REL_ "GenSigTimeoutTime" BU_SG_REL_ DashCAM SG_ 1714 Uhrzeit_01_alt 5000;
BA_REL_ "GenSigTimeoutTime" BU_SG_REL_ Gateway_Max SG_ 2536736000 BAP_SLCView_ASG_01_Header 800;
BA_REL_ "GenSigTimeoutTime" BU_SG_REL_ Gateway_Max SG_ 2463978863 BedienDisp_vm_Aktive_Ebene 5000;
BA_REL_ "GenSigTimeoutTime" BU_SG_REL_ Gateway_Max SG_ 2463978863 BedienDisp_vm_Ist_Profil 5000;
BA_REL_ "GenSigTimeoutTime" BU_SG_REL_ Gateway_Max SG_ 2463978863 BedienDisp_vm_Taster 5000;
BA_REL_ "GenSigTimeoutTime" BU_SG_REL_ Gateway_Max SG_ 2463978863 BedienDisp_vm_defekt 5000;
BA_REL_ "GenSigTimeoutTime" BU_SG_REL_ Gateway_Max SG_ 2463978863 BedienDisp_vm_Touch 5000;
BA_REL_ "GenSigTimeoutTime" BU_SG_REL_ ICC_IO_Node SG_ 2527679637 LiSi_Touch_Event 5000;
BA_REL_ "GenSigTimeoutTime" BU_SG_REL_ ICC_IO_Node SG_ 2527679781 LINDa_HL_Touch_Event 5000;
BA_REL_ "GenSigTimeoutTime" BU_SG_REL_ ICC_IO_Node SG_ 2527679781 LINDa_HR_Touch_Event 5000;
BA_REL_ "GenSigTimeoutTime" BU_SG_REL_ ICC_IO_Node SG_ 2527679781 LINDa_HL_SR3_Touch_Event 5000;
BA_REL_ "GenSigTimeoutTime" BU_SG_REL_ ICC_IO_Node SG_ 2527679781 LINDa_HR_SR3_Touch_Event 5000;
BA_REL_ "GenSigTimeoutTime" BU_SG_REL_ ICC_IO_Node SG_ 1635 NVEM_Abschaltstufe 1000;
BA_REL_ "GenSigTimeoutTime" BU_SG_REL_ ICC_IO_Node SG_ 1714 DGN_Verlernzaehler 5000;
BA_REL_ "GenSigTimeoutTime" BU_SG_REL_ ICC_IO_Node SG_ 1714 KBI_Kilometerstand 5000;
BA_REL_ "GenSigTimeoutTime" BU_SG_REL_ ICC_IO_Node SG_ 1714 UH_Jahr 5000;
BA_REL_ "GenSigTimeoutTime" BU_SG_REL_ ICC_IO_Node SG_ 1714 UH_Monat 5000;
BA_REL_ "GenSigTimeoutTime" BU_SG_REL_ ICC_IO_Node SG_ 1714 UH_Tag 5000;
BA_REL_ "GenSigTimeoutTime" BU_SG_REL_ ICC_IO_Node SG_ 1714 UH_Stunde 5000;
BA_REL_ "GenSigTimeoutTime" BU_SG_REL_ ICC_IO_Node SG_ 1714 UH_Minute 5000;
BA_REL_ "GenSigTimeoutTime" BU_SG_REL_ ICC_IO_Node SG_ 1714 UH_Sekunde 5000;
BA_REL_ "GenSigTimeoutTime" BU_SG_REL_ ICC_IO_Node SG_ 1714 Vehicle_Driving_Cycle 5000;
BA_REL_ "GenSigTimeoutTime" BU_SG_REL_ LSH SG_ 1635 NVEM_Abschaltstufe 1000;
BA_REL_ "GenSigTimeoutTime" BU_SG_REL_ LSH SG_ 1635 BEM_STH_Einschaltverbot 1000;
BA_REL_ "GenSigTimeoutTime" BU_SG_REL_ LSH SG_ 1635 BEM_HL_Regelung_Status 1000;
BA_REL_ "GenSigTimeoutTime" BU_SG_REL_ LSH SG_ 1635 BEM_Batt_Ab 1000;
BA_REL_ "GenSigTimeoutTime" BU_SG_REL_ LSH SG_ 1714 DGN_Verlernzaehler 5000;
BA_REL_ "GenSigTimeoutTime" BU_SG_REL_ LSH SG_ 1714 KBI_Kilometerstand 5000;
BA_REL_ "GenSigTimeoutTime" BU_SG_REL_ LSH SG_ 1714 UH_Jahr 5000;
BA_REL_ "GenSigTimeoutTime" BU_SG_REL_ LSH SG_ 1714 UH_Monat 5000;
BA_REL_ "GenSigTimeoutTime" BU_SG_REL_ LSH SG_ 1714 UH_Tag 5000;
BA_REL_ "GenSigTimeoutTime" BU_SG_REL_ LSH SG_ 1714 UH_Stunde 5000;
BA_REL_ "GenSigTimeoutTime" BU_SG_REL_ LSH SG_ 1714 UH_Minute 5000;
BA_REL_ "GenSigTimeoutTime" BU_SG_REL_ LSH SG_ 1714 UH_Sekunde 5000;
BA_REL_ "GenSigTimeoutTime" BU_SG_REL_ LSH SG_ 1714 Kombi_02_alt 5000;
BA_REL_ "GenSigTimeoutTime" BU_SG_REL_ LSH SG_ 1714 Uhrzeit_01_alt 5000;
BA_REL_ "GenSigTimeoutTime" BU_SG_REL_ OCU SG_ 2536735504 BAP_SecEvents2_FSG_01_Header 5000;
BA_REL_ "GenSigTimeoutTime" BU_SG_REL_ OCU SG_ 2536706576 BAP_SIA_FSG_01_Header 5000;
BA_REL_ "GenSigTimeoutTime" BU_SG_REL_ OCU SG_ 2536706064 BAP_Sitz1_FSG_01_Header 5000;
BA_REL_ "GenSigTimeoutTime" BU_SG_REL_ OCU SG_ 2536708624 BAP_SWA_FSG_01_Header 5000;
BA_REL_ "GenSigTimeoutTime" BU_SG_REL_ OCU SG_ 2536706320 BAP_Uhrzeit_FSG_01_Header 5000;
BA_REL_ "GenSigTimeoutTime" BU_SG_REL_ OCU SG_ 2536710416 BAP_VZA_FSG_01_Header 5000;
BA_REL_ "GenSigTimeoutTime" BU_SG_REL_ OCU SG_ 2536705040 BAP_Wiper_FSG_01_Header 5000;
BA_REL_ "GenSigTimeoutTime" BU_SG_REL_ OCU SG_ 1626 BCM_Bremsbelag_Sensor 5000;
BA_REL_ "GenSigTimeoutTime" BU_SG_REL_ OCU SG_ 1626 BCM_Bremsfluessigkeit_Sensor 5000;
BA_REL_ "GenSigTimeoutTime" BU_SG_REL_ OCU SG_ 1626 BCM1_Licht_Warn 5000;
BA_REL_ "GenSigTimeoutTime" BU_SG_REL_ OCU SG_ 1626 BCM_Waschwasser_Sensor 5000;
BA_REL_ "GenSigTimeoutTime" BU_SG_REL_ OCU SG_ 1626 BCM_Kuehlmittel_Sensor 5000;
BA_REL_ "GenSigTimeoutTime" BU_SG_REL_ OCU SG_ 1626 BCM1_LDS_Stellung 5000;
BA_REL_ "GenSigTimeoutTime" BU_SG_REL_ OCU SG_ 1626 BCM1_Rueckfahrlicht_Schalter 5000;
BA_REL_ "GenSigTimeoutTime" BU_SG_REL_ OCU SG_ 1626 BCM1_MH_Schalter 5000;
BA_REL_ "GenSigTimeoutTime" BU_SG_REL_ OCU SG_ 1626 LRH_Taster 5000;
BA_REL_ "GenSigTimeoutTime" BU_SG_REL_ OCU SG_ 1626 DWA_Alarmquelle 5000;
BA_REL_ "GenSigTimeoutTime" BU_SG_REL_ OCU SG_ 2463978850 NVEM_Verbraucher_Information 1000;
BA_REL_ "GenSigTimeoutTime" BU_SG_REL_ OCU SG_ 1635 NVEM_Abschaltstufe 1000;
BA_REL_ "GenSigTimeoutTime" BU_SG_REL_ OCU SG_ 1635 BEM_STH_Zielzeit 1000;
BA_REL_ "GenSigTimeoutTime" BU_SG_REL_ OCU SG_ 1635 NVEM_Freigabe_ZusBatt_Laden 1000;
BA_REL_ "GenSigTimeoutTime" BU_SG_REL_ OCU SG_ 1635 BEM_Red_Innengeblaese 1000;
BA_REL_ "GenSigTimeoutTime" BU_SG_REL_ OCU SG_ 1635 BEM_STH_Einschaltverbot 1000;
BA_REL_ "GenSigTimeoutTime" BU_SG_REL_ OCU SG_ 1635 BEM_HL_Regelung_Status 1000;
BA_REL_ "GenSigTimeoutTime" BU_SG_REL_ OCU SG_ 1635 BEM_Ladezustand 1000;
BA_REL_ "GenSigTimeoutTime" BU_SG_REL_ OCU SG_ 1635 BEM_DFM 1000;
BA_REL_ "GenSigTimeoutTime" BU_SG_REL_ OCU SG_ 1635 BEM_EMLIN_ungueltig 1000;
BA_REL_ "GenSigTimeoutTime" BU_SG_REL_ OCU SG_ 1635 BEM_Batt_Ab 1000;
BA_REL_ "GenSigTimeoutTime" BU_SG_REL_ OCU SG_ 1635 BEM_UBDM 1000;
BA_REL_ "GenSigTimeoutTime" BU_SG_REL_ OCU SG_ 1635 BEM_Anf_KL15_schalten 1000;
BA_REL_ "GenSigTimeoutTime" BU_SG_REL_ OCU SG_ 1635 NVEM_Freigabe_OnlineUpdate 1000;
BA_REL_ "GenSigTimeoutTime" BU_SG_REL_ OCU SG_ 870 BM_DWA_ein 5000;
BA_REL_ "GenSigTimeoutTime" BU_SG_REL_ OCU SG_ 870 BM_DWA_Alarm 5000;
BA_REL_ "GenSigTimeoutTime" BU_SG_REL_ OCU SG_ 870 BM_Crash 5000;
BA_REL_ "GenSigTimeoutTime" BU_SG_REL_ OCU SG_ 870 BM_Panik 5000;
BA_REL_ "GenSigTimeoutTime" BU_SG_REL_ OCU SG_ 870 BM_Not_Bremsung 5000;
BA_REL_ "GenSigTimeoutTime" BU_SG_REL_ OCU SG_ 870 BM_Warnblinken 5000;
BA_REL_ "GenSigTimeoutTime" BU_SG_REL_ OCU SG_ 870 BM_Telematik 5000;
BA_REL_ "GenSigTimeoutTime" BU_SG_REL_ OCU SG_ 870 BM_links 5000;
BA_REL_ "GenSigTimeoutTime" BU_SG_REL_ OCU SG_ 870 BM_rechts 5000;
BA_REL_ "GenSigTimeoutTime" BU_SG_REL_ OCU SG_ 870 BM_Telematik_Abbruchgrund 5000;
BA_REL_ "GenSigTimeoutTime" BU_SG_REL_ OCU SG_ 1714 DGN_Verlernzaehler 5000;
BA_REL_ "GenSigTimeoutTime" BU_SG_REL_ OCU SG_ 1714 KBI_Kilometerstand 5000;
BA_REL_ "GenSigTimeoutTime" BU_SG_REL_ OCU SG_ 1714 UH_Jahr 5000;
BA_REL_ "GenSigTimeoutTime" BU_SG_REL_ OCU SG_ 1714 UH_Monat 5000;
BA_REL_ "GenSigTimeoutTime" BU_SG_REL_ OCU SG_ 1714 UH_Tag 5000;
BA_REL_ "GenSigTimeoutTime" BU_SG_REL_ OCU SG_ 1714 UH_Stunde 5000;
BA_REL_ "GenSigTimeoutTime" BU_SG_REL_ OCU SG_ 1714 UH_Minute 5000;
BA_REL_ "GenSigTimeoutTime" BU_SG_REL_ OCU SG_ 1714 UH_Sekunde 5000;
BA_REL_ "GenSigTimeoutTime" BU_SG_REL_ OCU SG_ 1714 Vehicle_Driving_Cycle 5000;
BA_REL_ "GenSigTimeoutTime" BU_SG_REL_ OCU SG_ 1714 Kombi_02_alt 5000;
BA_REL_ "GenSigTimeoutTime" BU_SG_REL_ OCU SG_ 1714 Uhrzeit_01_alt 5000;
BA_REL_ "GenSigTimeoutTime" BU_SG_REL_ RDK_RS3 SG_ 1714 DGN_Verlernzaehler 5000;
BA_REL_ "GenSigTimeoutTime" BU_SG_REL_ RDK_RS3 SG_ 1714 KBI_Kilometerstand 5000;
BA_REL_ "GenSigTimeoutTime" BU_SG_REL_ RDK_RS3 SG_ 1714 UH_Jahr 5000;
BA_REL_ "GenSigTimeoutTime" BU_SG_REL_ RDK_RS3 SG_ 1714 UH_Monat 5000;
BA_REL_ "GenSigTimeoutTime" BU_SG_REL_ RDK_RS3 SG_ 1714 UH_Tag 5000;
BA_REL_ "GenSigTimeoutTime" BU_SG_REL_ RDK_RS3 SG_ 1714 UH_Stunde 5000;
BA_REL_ "GenSigTimeoutTime" BU_SG_REL_ RDK_RS3 SG_ 1714 UH_Minute 5000;
BA_REL_ "GenSigTimeoutTime" BU_SG_REL_ RDK_RS3 SG_ 1714 UH_Sekunde 5000;
BA_REL_ "GenSigTimeoutTime" BU_SG_REL_ RDK_RS3 SG_ 1714 Kombi_02_alt 5000;
BA_REL_ "GenSigTimeoutTime" BU_SG_REL_ RDK_RS3 SG_ 1714 Uhrzeit_01_alt 5000;
BA_REL_ "GenSigTimeoutTime" BU_SG_REL_ STH SG_ 1635 NVEM_Abschaltstufe 1000;
BA_REL_ "GenSigTimeoutTime" BU_SG_REL_ STH SG_ 1635 BEM_STH_Einschaltverbot 1000;
BA_REL_ "GenSigTimeoutTime" BU_SG_REL_ STH SG_ 1635 BEM_HL_Regelung_Status 1000;
BA_REL_ "GenSigTimeoutTime" BU_SG_REL_ STH SG_ 1635 BEM_Batt_Ab 1000;
BA_REL_ "GenSigTimeoutTime" BU_SG_REL_ STH SG_ 1714 DGN_Verlernzaehler 5000;
BA_REL_ "GenSigTimeoutTime" BU_SG_REL_ STH SG_ 1714 KBI_Kilometerstand 5000;
BA_REL_ "GenSigTimeoutTime" BU_SG_REL_ STH SG_ 1714 UH_Jahr 5000;
BA_REL_ "GenSigTimeoutTime" BU_SG_REL_ STH SG_ 1714 UH_Monat 5000;
BA_REL_ "GenSigTimeoutTime" BU_SG_REL_ STH SG_ 1714 UH_Tag 5000;
BA_REL_ "GenSigTimeoutTime" BU_SG_REL_ STH SG_ 1714 UH_Stunde 5000;
BA_REL_ "GenSigTimeoutTime" BU_SG_REL_ STH SG_ 1714 UH_Minute 5000;
BA_REL_ "GenSigTimeoutTime" BU_SG_REL_ STH SG_ 1714 UH_Sekunde 5000;
BA_REL_ "GenSigTimeoutTime" BU_SG_REL_ STH SG_ 1714 Kombi_02_alt 5000;
BA_REL_ "GenSigTimeoutTime" BU_SG_REL_ STH SG_ 1714 Uhrzeit_01_alt 5000;
BA_REL_ "GenSigTimeoutTime" BU_SG_REL_ ZR_MIB_EINSTIEG_ab_Gen3 SG_ 2536706576 BAP_SIA_FSG_01_Header 5000;
BA_REL_ "GenSigTimeoutTime" BU_SG_REL_ ZR_MIB_EINSTIEG_ab_Gen3 SG_ 2536706064 BAP_Sitz1_FSG_01_Header 5000;
BA_REL_ "GenSigTimeoutTime" BU_SG_REL_ ZR_MIB_EINSTIEG_ab_Gen3 SG_ 2536710160 BAP_Sitz2_FSG_01_Header 5000;
BA_REL_ "GenSigTimeoutTime" BU_SG_REL_ ZR_MIB_EINSTIEG_ab_Gen3 SG_ 2536736016 BAP_SLCView_FSG_01_Header 5000;
BA_REL_ "GenSigTimeoutTime" BU_SG_REL_ ZR_MIB_EINSTIEG_ab_Gen3 SG_ 2536720912 BAP_Statistics_FSG_01_Header 5000;
BA_REL_ "GenSigTimeoutTime" BU_SG_REL_ ZR_MIB_EINSTIEG_ab_Gen3 SG_ 2536708624 BAP_SWA_FSG_01_Header 5000;
BA_REL_ "GenSigTimeoutTime" BU_SG_REL_ ZR_MIB_EINSTIEG_ab_Gen3 SG_ 2536712192 BAP_Telefon_ASG_01_Header 500;
BA_REL_ "GenSigTimeoutTime" BU_SG_REL_ ZR_MIB_EINSTIEG_ab_Gen3 SG_ 2536712193 BAP_Telefon_ASG_02_Header 500;
BA_REL_ "GenSigTimeoutTime" BU_SG_REL_ ZR_MIB_EINSTIEG_ab_Gen3 SG_ 2536712194 BAP_Telefon_ASG_03_Header 500;
BA_REL_ "GenSigTimeoutTime" BU_SG_REL_ ZR_MIB_EINSTIEG_ab_Gen3 SG_ 2536712195 BAP_Telefon_ASG_04_Header 500;
BA_REL_ "GenSigTimeoutTime" BU_SG_REL_ ZR_MIB_EINSTIEG_ab_Gen3 SG_ 2536726288 BAP_TPA_FSG_01_Header 5000;
BA_REL_ "GenSigTimeoutTime" BU_SG_REL_ ZR_MIB_EINSTIEG_ab_Gen3 SG_ 2536715792 BAP_TrailerAssist_FSG_01_Header 5000;
BA_REL_ "GenSigTimeoutTime" BU_SG_REL_ ZR_MIB_EINSTIEG_ab_Gen3 SG_ 2536706320 BAP_Uhrzeit_FSG_01_Header 5000;
BA_REL_ "GenSigTimeoutTime" BU_SG_REL_ ZR_MIB_EINSTIEG_ab_Gen3 SG_ 2536710416 BAP_VZA_FSG_01_Header 5000;
BA_REL_ "GenSigTimeoutTime" BU_SG_REL_ ZR_MIB_EINSTIEG_ab_Gen3 SG_ 2536705040 BAP_Wiper_FSG_01_Header 5000;
BA_REL_ "GenSigTimeoutTime" BU_SG_REL_ ZR_MIB_EINSTIEG_ab_Gen3 SG_ 1626 BCM1_MH_Schalter 5000;
BA_REL_ "GenSigTimeoutTime" BU_SG_REL_ ZR_MIB_EINSTIEG_ab_Gen3 SG_ 1626 BCM_ValetTaster_Fkts_LED 5000;
BA_REL_ "GenSigTimeoutTime" BU_SG_REL_ ZR_MIB_EINSTIEG_ab_Gen3 SG_ 2527679637 LiSi_Touch_Event 5000;
BA_REL_ "GenSigTimeoutTime" BU_SG_REL_ ZR_MIB_EINSTIEG_ab_Gen3 SG_ 2463978607 BCM_RGB_Rot 2000;
BA_REL_ "GenSigTimeoutTime" BU_SG_REL_ ZR_MIB_EINSTIEG_ab_Gen3 SG_ 2463978607 BCM_RGB_Gruen 2000;
BA_REL_ "GenSigTimeoutTime" BU_SG_REL_ ZR_MIB_EINSTIEG_ab_Gen3 SG_ 2463978607 BCM_RGB_Blau 2000;
BA_REL_ "GenSigTimeoutTime" BU_SG_REL_ ZR_MIB_EINSTIEG_ab_Gen3 SG_ 2527679781 LINDa_HL_Touch_Event 5000;
BA_REL_ "GenSigTimeoutTime" BU_SG_REL_ ZR_MIB_EINSTIEG_ab_Gen3 SG_ 2527679781 LINDa_HR_Touch_Event 5000;
BA_REL_ "GenSigTimeoutTime" BU_SG_REL_ ZR_MIB_EINSTIEG_ab_Gen3 SG_ 2527679781 LINDa_HL_SR3_Touch_Event 5000;
BA_REL_ "GenSigTimeoutTime" BU_SG_REL_ ZR_MIB_EINSTIEG_ab_Gen3 SG_ 2527679781 LINDa_HR_SR3_Touch_Event 5000;
BA_REL_ "GenSigTimeoutTime" BU_SG_REL_ ZR_MIB_EINSTIEG_ab_Gen3 SG_ 2463978850 NVEM_Verbraucher_Information 1000;
BA_REL_ "GenSigTimeoutTime" BU_SG_REL_ ZR_MIB_EINSTIEG_ab_Gen3 SG_ 1635 NVEM_Abschaltstufe 1000;
BA_REL_ "GenSigTimeoutTime" BU_SG_REL_ ZR_MIB_EINSTIEG_ab_Gen3 SG_ 1635 BEM_HL_Regelung_Status 1000;
BA_REL_ "GenSigTimeoutTime" BU_SG_REL_ ZR_MIB_EINSTIEG_ab_Gen3 SG_ 1635 BEM_UBDM 1000;
BA_REL_ "GenSigTimeoutTime" BU_SG_REL_ ZR_MIB_EINSTIEG_ab_Gen3 SG_ 1635 NVEM_Freigabe_OnlineUpdate 1000;
BA_REL_ "GenSigTimeoutTime" BU_SG_REL_ ZR_MIB_EINSTIEG_ab_Gen3 SG_ 870 BM_links 5000;
BA_REL_ "GenSigTimeoutTime" BU_SG_REL_ ZR_MIB_EINSTIEG_ab_Gen3 SG_ 870 BM_rechts 5000;
BA_REL_ "GenSigTimeoutTime" BU_SG_REL_ ZR_MIB_EINSTIEG_ab_Gen3 SG_ 870 Blinken_li_Fzg_Takt 5000;
BA_REL_ "GenSigTimeoutTime" BU_SG_REL_ ZR_MIB_EINSTIEG_ab_Gen3 SG_ 870 Blinken_re_Fzg_Takt 5000;
BA_REL_ "GenSigTimeoutTime" BU_SG_REL_ ZR_MIB_EINSTIEG_ab_Gen3 SG_ 870 Blinken_li_Kombi_Takt 5000;
BA_REL_ "GenSigTimeoutTime" BU_SG_REL_ ZR_MIB_EINSTIEG_ab_Gen3 SG_ 870 Blinken_re_Kombi_Takt 5000;
BA_REL_ "GenSigTimeoutTime" BU_SG_REL_ ZR_MIB_EINSTIEG_ab_Gen3 SG_ 870 BM_Autobahn 5000;
BA_REL_ "GenSigTimeoutTime" BU_SG_REL_ ZR_MIB_EINSTIEG_ab_Gen3 SG_ 1714 DGN_Verlernzaehler 5000;
BA_REL_ "GenSigTimeoutTime" BU_SG_REL_ ZR_MIB_EINSTIEG_ab_Gen3 SG_ 1714 KBI_Kilometerstand 5000;
BA_REL_ "GenSigTimeoutTime" BU_SG_REL_ ZR_MIB_EINSTIEG_ab_Gen3 SG_ 1714 UH_Jahr 5000;
BA_REL_ "GenSigTimeoutTime" BU_SG_REL_ ZR_MIB_EINSTIEG_ab_Gen3 SG_ 1714 UH_Monat 5000;
BA_REL_ "GenSigTimeoutTime" BU_SG_REL_ ZR_MIB_EINSTIEG_ab_Gen3 SG_ 1714 UH_Tag 5000;
BA_REL_ "GenSigTimeoutTime" BU_SG_REL_ ZR_MIB_EINSTIEG_ab_Gen3 SG_ 1714 UH_Stunde 5000;
BA_REL_ "GenSigTimeoutTime" BU_SG_REL_ ZR_MIB_EINSTIEG_ab_Gen3 SG_ 1714 UH_Minute 5000;
BA_REL_ "GenSigTimeoutTime" BU_SG_REL_ ZR_MIB_EINSTIEG_ab_Gen3 SG_ 1714 UH_Sekunde 5000;
BA_REL_ "GenSigTimeoutTime" BU_SG_REL_ ZR_MIB_EINSTIEG_ab_Gen3 SG_ 1714 Vehicle_Driving_Cycle 5000;
BA_REL_ "GenSigTimeoutTime" BU_SG_REL_ ZR_MIB_EINSTIEG_ab_Gen3 SG_ 1714 Kombi_02_alt 5000;
BA_REL_ "GenSigTimeoutTime" BU_SG_REL_ ZR_MIB_EINSTIEG_ab_Gen3 SG_ 1714 Uhrzeit_01_alt 5000;
BA_REL_ "GenSigTimeoutTime" BU_SG_REL_ ZR_MIB_EINSTIEG_ab_Gen3 SG_ 851 DiETa_Car 800;
BA_REL_ "GenSigTimeoutTime" BU_SG_REL_ ZR_MIB_EINSTIEG_ab_Gen3 SG_ 851 DiETa_Touch_Event 800;
BA_REL_ "GenSigTimeoutTime" BU_SG_REL_ ZR_MIB_OPTION_ab_Gen3 SG_ 2536706576 BAP_SIA_FSG_01_Header 5000;
BA_REL_ "GenSigTimeoutTime" BU_SG_REL_ ZR_MIB_OPTION_ab_Gen3 SG_ 2536706064 BAP_Sitz1_FSG_01_Header 5000;
BA_REL_ "GenSigTimeoutTime" BU_SG_REL_ ZR_MIB_OPTION_ab_Gen3 SG_ 2536710160 BAP_Sitz2_FSG_01_Header 5000;
BA_REL_ "GenSigTimeoutTime" BU_SG_REL_ ZR_MIB_OPTION_ab_Gen3 SG_ 2536736016 BAP_SLCView_FSG_01_Header 5000;
BA_REL_ "GenSigTimeoutTime" BU_SG_REL_ ZR_MIB_OPTION_ab_Gen3 SG_ 2536720912 BAP_Statistics_FSG_01_Header 5000;
BA_REL_ "GenSigTimeoutTime" BU_SG_REL_ ZR_MIB_OPTION_ab_Gen3 SG_ 2536721168 BAP_Sunroof_FSG_01_Header 5000;
BA_REL_ "GenSigTimeoutTime" BU_SG_REL_ ZR_MIB_OPTION_ab_Gen3 SG_ 2536708624 BAP_SWA_FSG_01_Header 5000;
BA_REL_ "GenSigTimeoutTime" BU_SG_REL_ ZR_MIB_OPTION_ab_Gen3 SG_ 2536712448 BAP_Telefon2_ASG_01_Header 800;
BA_REL_ "GenSigTimeoutTime" BU_SG_REL_ ZR_MIB_OPTION_ab_Gen3 SG_ 2536712449 BAP_Telefon2_ASG_02_Header 800;
BA_REL_ "GenSigTimeoutTime" BU_SG_REL_ ZR_MIB_OPTION_ab_Gen3 SG_ 2536712192 BAP_Telefon_ASG_01_Header 500;
BA_REL_ "GenSigTimeoutTime" BU_SG_REL_ ZR_MIB_OPTION_ab_Gen3 SG_ 2536712193 BAP_Telefon_ASG_02_Header 500;
BA_REL_ "GenSigTimeoutTime" BU_SG_REL_ ZR_MIB_OPTION_ab_Gen3 SG_ 2536712194 BAP_Telefon_ASG_03_Header 500;
BA_REL_ "GenSigTimeoutTime" BU_SG_REL_ ZR_MIB_OPTION_ab_Gen3 SG_ 2536712195 BAP_Telefon_ASG_04_Header 500;
BA_REL_ "GenSigTimeoutTime" BU_SG_REL_ ZR_MIB_OPTION_ab_Gen3 SG_ 2536726288 BAP_TPA_FSG_01_Header 5000;
BA_REL_ "GenSigTimeoutTime" BU_SG_REL_ ZR_MIB_OPTION_ab_Gen3 SG_ 2536715792 BAP_TrailerAssist_FSG_01_Header 5000;
BA_REL_ "GenSigTimeoutTime" BU_SG_REL_ ZR_MIB_OPTION_ab_Gen3 SG_ 2536706320 BAP_Uhrzeit_FSG_01_Header 5000;
BA_REL_ "GenSigTimeoutTime" BU_SG_REL_ ZR_MIB_OPTION_ab_Gen3 SG_ 2536710416 BAP_VZA_FSG_01_Header 5000;
BA_REL_ "GenSigTimeoutTime" BU_SG_REL_ ZR_MIB_OPTION_ab_Gen3 SG_ 2536705040 BAP_Wiper_FSG_01_Header 5000;
BA_REL_ "GenSigTimeoutTime" BU_SG_REL_ ZR_MIB_OPTION_ab_Gen3 SG_ 1626 BCM1_MH_Schalter 5000;
BA_REL_ "GenSigTimeoutTime" BU_SG_REL_ ZR_MIB_OPTION_ab_Gen3 SG_ 1626 BCM_ValetTaster_Fkts_LED 5000;
BA_REL_ "GenSigTimeoutTime" BU_SG_REL_ ZR_MIB_OPTION_ab_Gen3 SG_ 2527679637 LiSi_Touch_Event 5000;
BA_REL_ "GenSigTimeoutTime" BU_SG_REL_ ZR_MIB_OPTION_ab_Gen3 SG_ 2463978607 BCM_RGB_Rot 2000;
BA_REL_ "GenSigTimeoutTime" BU_SG_REL_ ZR_MIB_OPTION_ab_Gen3 SG_ 2463978607 BCM_RGB_Gruen 2000;
BA_REL_ "GenSigTimeoutTime" BU_SG_REL_ ZR_MIB_OPTION_ab_Gen3 SG_ 2463978607 BCM_RGB_Blau 2000;
BA_REL_ "GenSigTimeoutTime" BU_SG_REL_ ZR_MIB_OPTION_ab_Gen3 SG_ 2527679781 LINDa_HL_Touch_Event 5000;
BA_REL_ "GenSigTimeoutTime" BU_SG_REL_ ZR_MIB_OPTION_ab_Gen3 SG_ 2527679781 LINDa_HR_Touch_Event 5000;
BA_REL_ "GenSigTimeoutTime" BU_SG_REL_ ZR_MIB_OPTION_ab_Gen3 SG_ 2527679781 LINDa_HL_SR3_Touch_Event 5000;
BA_REL_ "GenSigTimeoutTime" BU_SG_REL_ ZR_MIB_OPTION_ab_Gen3 SG_ 2527679781 LINDa_HR_SR3_Touch_Event 5000;
BA_REL_ "GenSigTimeoutTime" BU_SG_REL_ ZR_MIB_OPTION_ab_Gen3 SG_ 2463978882 BedienDisp_hbfs_control_vol 5000;
BA_REL_ "GenSigTimeoutTime" BU_SG_REL_ ZR_MIB_OPTION_ab_Gen3 SG_ 2463978882 BedienDisp_hbfs_surround 5000;
BA_REL_ "GenSigTimeoutTime" BU_SG_REL_ ZR_MIB_OPTION_ab_Gen3 SG_ 2463978882 BedienDisp_hbfs_touch 5000;
BA_REL_ "GenSigTimeoutTime" BU_SG_REL_ ZR_MIB_OPTION_ab_Gen3 SG_ 2463978882 BedienDisp_hbfs_sound_fokus 5000;
BA_REL_ "GenSigTimeoutTime" BU_SG_REL_ ZR_MIB_OPTION_ab_Gen3 SG_ 2463978882 BedienDisp_hbfs_control_vol_02 5000;
BA_REL_ "GenSigTimeoutTime" BU_SG_REL_ ZR_MIB_OPTION_ab_Gen3 SG_ 2463978881 BedienDisp_hfs_control_vol 5000;
BA_REL_ "GenSigTimeoutTime" BU_SG_REL_ ZR_MIB_OPTION_ab_Gen3 SG_ 2463978881 BedienDisp_hfs_surround 5000;
BA_REL_ "GenSigTimeoutTime" BU_SG_REL_ ZR_MIB_OPTION_ab_Gen3 SG_ 2463978881 BedienDisp_hfs_touch 5000;
BA_REL_ "GenSigTimeoutTime" BU_SG_REL_ ZR_MIB_OPTION_ab_Gen3 SG_ 2463978881 BedienDisp_hfs_sound_fokus 5000;
BA_REL_ "GenSigTimeoutTime" BU_SG_REL_ ZR_MIB_OPTION_ab_Gen3 SG_ 2463978881 BedienDisp_hfs_control_vol_02 5000;
BA_REL_ "GenSigTimeoutTime" BU_SG_REL_ ZR_MIB_OPTION_ab_Gen3 SG_ 2463978863 BedienDisp_vm_Control 5000;
BA_REL_ "GenSigTimeoutTime" BU_SG_REL_ ZR_MIB_OPTION_ab_Gen3 SG_ 2463978863 BedienDisp_vm_Function 5000;
BA_REL_ "GenSigTimeoutTime" BU_SG_REL_ ZR_MIB_OPTION_ab_Gen3 SG_ 2463978863 BedienDisp_vm_Press 5000;
BA_REL_ "GenSigTimeoutTime" BU_SG_REL_ ZR_MIB_OPTION_ab_Gen3 SG_ 2463978850 NVEM_Verbraucher_Information 1000;
BA_REL_ "GenSigTimeoutTime" BU_SG_REL_ ZR_MIB_OPTION_ab_Gen3 SG_ 1635 NVEM_Abschaltstufe 1000;
BA_REL_ "GenSigTimeoutTime" BU_SG_REL_ ZR_MIB_OPTION_ab_Gen3 SG_ 1635 BEM_HL_Regelung_Status 1000;
BA_REL_ "GenSigTimeoutTime" BU_SG_REL_ ZR_MIB_OPTION_ab_Gen3 SG_ 1635 BEM_UBDM 1000;
BA_REL_ "GenSigTimeoutTime" BU_SG_REL_ ZR_MIB_OPTION_ab_Gen3 SG_ 1635 NVEM_Freigabe_OnlineUpdate 1000;
BA_REL_ "GenSigTimeoutTime" BU_SG_REL_ ZR_MIB_OPTION_ab_Gen3 SG_ 870 BM_links 5000;
BA_REL_ "GenSigTimeoutTime" BU_SG_REL_ ZR_MIB_OPTION_ab_Gen3 SG_ 870 BM_rechts 5000;
BA_REL_ "GenSigTimeoutTime" BU_SG_REL_ ZR_MIB_OPTION_ab_Gen3 SG_ 870 Blinken_li_Kombi_Takt 5000;
BA_REL_ "GenSigTimeoutTime" BU_SG_REL_ ZR_MIB_OPTION_ab_Gen3 SG_ 870 Blinken_re_Kombi_Takt 5000;
BA_REL_ "GenSigTimeoutTime" BU_SG_REL_ ZR_MIB_OPTION_ab_Gen3 SG_ 870 BM_Autobahn 5000;
BA_REL_ "GenSigTimeoutTime" BU_SG_REL_ ZR_MIB_OPTION_ab_Gen3 SG_ 902 CHA_Current_Mode_FPA 5000;
BA_REL_ "GenSigTimeoutTime" BU_SG_REL_ ZR_MIB_OPTION_ab_Gen3 SG_ 2527679921 CPDFct_Deakt 2000;
BA_REL_ "GenSigTimeoutTime" BU_SG_REL_ ZR_MIB_OPTION_ab_Gen3 SG_ 1714 DGN_Verlernzaehler 5000;
BA_REL_ "GenSigTimeoutTime" BU_SG_REL_ ZR_MIB_OPTION_ab_Gen3 SG_ 1714 KBI_Kilometerstand 5000;
BA_REL_ "GenSigTimeoutTime" BU_SG_REL_ ZR_MIB_OPTION_ab_Gen3 SG_ 1714 UH_Jahr 5000;
BA_REL_ "GenSigTimeoutTime" BU_SG_REL_ ZR_MIB_OPTION_ab_Gen3 SG_ 1714 UH_Monat 5000;
BA_REL_ "GenSigTimeoutTime" BU_SG_REL_ ZR_MIB_OPTION_ab_Gen3 SG_ 1714 UH_Tag 5000;
BA_REL_ "GenSigTimeoutTime" BU_SG_REL_ ZR_MIB_OPTION_ab_Gen3 SG_ 1714 UH_Stunde 5000;
BA_REL_ "GenSigTimeoutTime" BU_SG_REL_ ZR_MIB_OPTION_ab_Gen3 SG_ 1714 UH_Minute 5000;
BA_REL_ "GenSigTimeoutTime" BU_SG_REL_ ZR_MIB_OPTION_ab_Gen3 SG_ 1714 UH_Sekunde 5000;
BA_REL_ "GenSigTimeoutTime" BU_SG_REL_ ZR_MIB_OPTION_ab_Gen3 SG_ 1714 Vehicle_Driving_Cycle 5000;
BA_REL_ "GenSigTimeoutTime" BU_SG_REL_ ZR_MIB_OPTION_ab_Gen3 SG_ 1714 Kombi_02_alt 5000;
BA_REL_ "GenSigTimeoutTime" BU_SG_REL_ ZR_MIB_OPTION_ab_Gen3 SG_ 1714 Uhrzeit_01_alt 5000;
BA_REL_ "GenSigTimeoutTime" BU_SG_REL_ ZR_MIB_OPTION_ab_Gen3 SG_ 851 DiETa_Car 800;
BA_REL_ "GenSigTimeoutTime" BU_SG_REL_ ZR_MIB_OPTION_ab_Gen3 SG_ 851 DiETa_Touch_Event 800;
BA_REL_ "GenSigTimeoutTime" BU_SG_REL_ ZR_MIB_TOP_ab_Gen3 SG_ 2536706576 BAP_SIA_FSG_01_Header 5000;
BA_REL_ "GenSigTimeoutTime" BU_SG_REL_ ZR_MIB_TOP_ab_Gen3 SG_ 2536706064 BAP_Sitz1_FSG_01_Header 5000;
BA_REL_ "GenSigTimeoutTime" BU_SG_REL_ ZR_MIB_TOP_ab_Gen3 SG_ 2536710160 BAP_Sitz2_FSG_01_Header 5000;
BA_REL_ "GenSigTimeoutTime" BU_SG_REL_ ZR_MIB_TOP_ab_Gen3 SG_ 2536720912 BAP_Statistics_FSG_01_Header 5000;
BA_REL_ "GenSigTimeoutTime" BU_SG_REL_ ZR_MIB_TOP_ab_Gen3 SG_ 2536708624 BAP_SWA_FSG_01_Header 5000;
BA_REL_ "GenSigTimeoutTime" BU_SG_REL_ ZR_MIB_TOP_ab_Gen3 SG_ 2536712448 BAP_Telefon2_ASG_01_Header 800;
BA_REL_ "GenSigTimeoutTime" BU_SG_REL_ ZR_MIB_TOP_ab_Gen3 SG_ 2536712192 BAP_Telefon_ASG_01_Header 500;
BA_REL_ "GenSigTimeoutTime" BU_SG_REL_ ZR_MIB_TOP_ab_Gen3 SG_ 2536712193 BAP_Telefon_ASG_02_Header 500;
BA_REL_ "GenSigTimeoutTime" BU_SG_REL_ ZR_MIB_TOP_ab_Gen3 SG_ 2536712194 BAP_Telefon_ASG_03_Header 500;
BA_REL_ "GenSigTimeoutTime" BU_SG_REL_ ZR_MIB_TOP_ab_Gen3 SG_ 2536712195 BAP_Telefon_ASG_04_Header 500;
BA_REL_ "GenSigTimeoutTime" BU_SG_REL_ ZR_MIB_TOP_ab_Gen3 SG_ 2536726288 BAP_TPA_FSG_01_Header 5000;
BA_REL_ "GenSigTimeoutTime" BU_SG_REL_ ZR_MIB_TOP_ab_Gen3 SG_ 2536706320 BAP_Uhrzeit_FSG_01_Header 5000;
BA_REL_ "GenSigTimeoutTime" BU_SG_REL_ ZR_MIB_TOP_ab_Gen3 SG_ 2536710416 BAP_VZA_FSG_01_Header 5000;
BA_REL_ "GenSigTimeoutTime" BU_SG_REL_ ZR_MIB_TOP_ab_Gen3 SG_ 2536705040 BAP_Wiper_FSG_01_Header 5000;
BA_REL_ "GenSigTimeoutTime" BU_SG_REL_ ZR_MIB_TOP_ab_Gen3 SG_ 1626 BCM_ValetTaster_Fkts_LED 5000;
BA_REL_ "GenSigTimeoutTime" BU_SG_REL_ ZR_MIB_TOP_ab_Gen3 SG_ 2527679637 BCM_FAS_Taster 5000;
BA_REL_ "GenSigTimeoutTime" BU_SG_REL_ ZR_MIB_TOP_ab_Gen3 SG_ 2527679637 LiSi_Touch_Event 5000;
BA_REL_ "GenSigTimeoutTime" BU_SG_REL_ ZR_MIB_TOP_ab_Gen3 SG_ 2463978607 BCM_RGB_Rot 2000;
BA_REL_ "GenSigTimeoutTime" BU_SG_REL_ ZR_MIB_TOP_ab_Gen3 SG_ 2463978607 BCM_RGB_Gruen 2000;
BA_REL_ "GenSigTimeoutTime" BU_SG_REL_ ZR_MIB_TOP_ab_Gen3 SG_ 2463978607 BCM_RGB_Blau 2000;
BA_REL_ "GenSigTimeoutTime" BU_SG_REL_ ZR_MIB_TOP_ab_Gen3 SG_ 2527679781 LINDa_HL_Touch_Event 5000;
BA_REL_ "GenSigTimeoutTime" BU_SG_REL_ ZR_MIB_TOP_ab_Gen3 SG_ 2527679781 LINDa_HR_Touch_Event 5000;
BA_REL_ "GenSigTimeoutTime" BU_SG_REL_ ZR_MIB_TOP_ab_Gen3 SG_ 2527679781 LINDa_HL_SR3_Touch_Event 5000;
BA_REL_ "GenSigTimeoutTime" BU_SG_REL_ ZR_MIB_TOP_ab_Gen3 SG_ 2527679781 LINDa_HR_SR3_Touch_Event 5000;
BA_REL_ "GenSigTimeoutTime" BU_SG_REL_ ZR_MIB_TOP_ab_Gen3 SG_ 2463978850 NVEM_Verbraucher_Information 1000;
BA_REL_ "GenSigTimeoutTime" BU_SG_REL_ ZR_MIB_TOP_ab_Gen3 SG_ 870 Blinken_li_Kombi_Takt 5000;
BA_REL_ "GenSigTimeoutTime" BU_SG_REL_ ZR_MIB_TOP_ab_Gen3 SG_ 870 Blinken_re_Kombi_Takt 5000;
BA_REL_ "GenSigTimeoutTime" BU_SG_REL_ ZR_MIB_TOP_ab_Gen3 SG_ 870 BM_Autobahn 5000;
BA_REL_ "GenSigTimeoutTime" BU_SG_REL_ ZR_MIB_TOP_ab_Gen3 SG_ 2589283664 BMS_Ladevorgang_aktiv 5000;
BA_REL_ "GenSigTimeoutTime" BU_SG_REL_ ZR_MIB_TOP_ab_Gen3 SG_ 1714 DGN_Verlernzaehler 5000;
BA_REL_ "GenSigTimeoutTime" BU_SG_REL_ ZR_MIB_TOP_ab_Gen3 SG_ 1714 KBI_Kilometerstand 5000;
BA_REL_ "GenSigTimeoutTime" BU_SG_REL_ ZR_MIB_TOP_ab_Gen3 SG_ 1714 UH_Jahr 5000;
BA_REL_ "GenSigTimeoutTime" BU_SG_REL_ ZR_MIB_TOP_ab_Gen3 SG_ 1714 UH_Monat 5000;
BA_REL_ "GenSigTimeoutTime" BU_SG_REL_ ZR_MIB_TOP_ab_Gen3 SG_ 1714 UH_Tag 5000;
BA_REL_ "GenSigTimeoutTime" BU_SG_REL_ ZR_MIB_TOP_ab_Gen3 SG_ 1714 UH_Stunde 5000;
BA_REL_ "GenSigTimeoutTime" BU_SG_REL_ ZR_MIB_TOP_ab_Gen3 SG_ 1714 UH_Minute 5000;
BA_REL_ "GenSigTimeoutTime" BU_SG_REL_ ZR_MIB_TOP_ab_Gen3 SG_ 1714 UH_Sekunde 5000;
BA_REL_ "GenSigTimeoutTime" BU_SG_REL_ ZR_MIB_TOP_ab_Gen3 SG_ 1714 Vehicle_Driving_Cycle 5000;
BA_REL_ "GenSigTimeoutTime" BU_SG_REL_ ZR_MIB_TOP_ab_Gen3 SG_ 1714 Kombi_02_alt 5000;
BA_REL_ "GenSigTimeoutTime" BU_SG_REL_ ZR_MIB_TOP_ab_Gen3 SG_ 1714 Uhrzeit_01_alt 5000;
BA_REL_ "GenSigTimeoutTime" BU_SG_REL_ ZR_MIB_TOP_ab_Gen3 SG_ 851 DiETa_Touch_Event 800;
VAL_ 1626 BCM_Bremsbelag_Sensor 0 "OK" 1 "Bremsbelag_unter_min" ;
VAL_ 1626 BCM_Bremsfluessigkeit_Sensor 0 "OK" 1 "Bremsfluessigkeit_unter_min" ;
VAL_ 1626 BCM1_Licht_Warn 0 "OK" 1 "Lichtwarnung_aktiv" ;
VAL_ 1626 BCM_Waschwasser_Sensor 0 "OK" 1 "Waschwasser_unter_min" ;
VAL_ 1626 BCM_Kuehlmittel_Sensor 0 "OK" 1 "Kuehlmittel_unter_min" ;
VAL_ 1626 BCM1_Kl_15_HW_erkannt 1 "Klemme 15 erkannt" ;
VAL_ 1626 BCM1_Kl_15_Sig_HW_erkannt 0 "KL15_HW_Signal_von_BCM1_nicht_erkannt" 1 "KL15_HW_Signal_von_BCM1_erkannt" ;
VAL_ 1626 BCM_Kuehlmittel_Sensor_02 0 "OK" 1 "Kuehlmittel_unter_min" ;
VAL_ 1626 BCM1_Hinweis_Lichtnachlauf 0 "inaktiv" 1 "aktiv" ;
VAL_ 1626 BCM_Offroad_Taste 0 "Taster_nicht_betaetigt" 1 "Taster_betaetigt" ;
VAL_ 1626 BCM_Charisma_Taste2 0 "nicht_betaetigt" 1 "betaetigt" ;
VAL_ 1626 BCM_Hybrid_StSt_Taste_Fehler 0 "kein_Fehler_StSt_Taster" 1 "Fehler_StSt_Taster" ;
VAL_ 1626 BCM_Hybrid_StartStopp_Taste 0 "nicht_betaetigt" 1 "betaetigt" ;
VAL_ 1626 BCM1_Warnblink_Taster 0 "nicht_betaetigt" 1 "betaetigt" ;
VAL_ 1626 BCM1_Valet_Parking_Taster 0 "nicht_betaetigt" 1 "betaetigt" ;
VAL_ 1626 BCM1_LDS_Stellung 0 "Init" 1 "Stellung_0" 2 "Auto" 3 "Standlicht" 4 "Abblendlicht" 7 "Fehler" ;
VAL_ 1626 BCM1_Rueckfahrlicht_Schalter 0 "nicht_betaetigt" 1 "betaetigt" ;
VAL_ 1626 BCM1_MH_Schalter 0 "MH_geschlossen" 1 "MH_offen" ;
VAL_ 1626 BCM1_MH_WIV_Schalter 0 "MH_geschlossen" 1 "MH_offen" ;
VAL_ 1626 BCM_Eco_Charisma_Taste 0 "nicht_betaetigt" 1 "betaetigt" ;
VAL_ 1626 BCM1_NV_Taster 0 "Taster_nicht_betaetigt" 1 "Taster_betaetigt" ;
VAL_ 1626 BCM1_AFS_Lampe 0 "Aus" 1 "Ein" ;
VAL_ 1626 BCM1_Reisemodus_Texte 0 "keine_Anzeige" 1 "Umschaltung_auf_Linksverkehr_aktiv" 2 "Umschaltung_auf_Rechtsverkehr_aktiv" ;
VAL_ 1626 BCM1_Lichtwarn_Texte 0 "keine_Warnung" 1 "Standlichtwarnung" 2 "Parklichtwarnung" 3 "Nebelschlusslichtwarnung" ;
VAL_ 1626 Gong_TFL_Umschaltung 0 "kein_Gong" 1 "Gong_einmalig" ;
VAL_ 1626 BCM_ValetTaster_Fkts_LED 0 "LED_aus" 1 "LED_ein" ;
VAL_ 1626 LRH_Taster 0 "nicht_betaetigt" 1 "betaetigt" ;
VAL_ 1626 APS_Tongeber_defekt 0 "iO" 1 "defekt" ;
VAL_ 1626 BCM1_EasyEntry_Status 0 "Aus" 1 "Ein" ;
VAL_ 1626 BCM1_Lenksaeule_aktiv 0 "Lenksaeulenverstellung nicht aktiv" 1 "Lenksaeulenverstellung aktiv" ;
VAL_ 1626 BCM1_Spannungs_Anf 0 "keine_Anforderung" 1 "Anforderung_Stufe_1" 2 "Anforderung_Stufe_2" 3 "Anforderung_Stufe_3" ;
VAL_ 1626 DWA_Alarmquelle 0 "kein_Ausloesegrund" 1 "Tuerkontakt_Fahrertuer" 2 "Tuerkontakt_Beifahrertuer" 3 "Tuerkontakt_hinten_links" 4 "Tuerkontakt_hinten_rechts" 5 "Motorhaubenkontakt_vorne" 6 "Kofferraum_hinten" 7 "Masseschleife_der_Heckscheibe" 8 "Innenraumueberwachung" 9 "Alarm_durch_Noteinstieg" 10 "Sounder" 11 "Neigungssensor" 12 "TSG_FT_am_CAN_Bus" 13 "TSG_BT_am_CAN_Bus" 14 "TSG_HFS_am_CAN_Bus" 15 "TSG_HBFS_am_CAN_Bus" 16 "Klemme_15" 17 "Klemme_15sig" 18 "frei" 19 "Anhaengerueberwachung" 20 "Scheinwerferueberwachung_links" 21 "Scheinwerferueberwachung_rechts" 22 "Handschuhkasten" 23 "Verdeckueberwachung" 24 "OBD_Alarm" 25 "Power_on_Reset" 30 "Init" 31 "Fehler" ;
VAL_ 1626 DWA_Einschraenkung 0 "Init" 1 "Fehler" ;
VAL_ 1626 BCM_HBFS_EOE_aktiv 0 "EOE_inaktiv" 1 "EOE_aktiv" ;
VAL_ 1626 BCM_HFS_EOE_aktiv 0 "EOE_inaktiv" 1 "EOE_aktiv" ;
VAL_ 1626 BCM_Anf_AAW_MoLaWa 0 "Init" 1 "AAW_angefordert" 2 "MoLaWa_angefordert" ;
VAL_ 1626 BCM_Handbremse_Hinweis 0 "inaktiv" 1 "aktiv" ;
VAL_ 1626 BCM_Waehlhebel_P_Hinweis 0 "inaktiv" 1 "aktiv" ;
VAL_ 1626 BCM1_Fahrlicht_Hinweis 0 "kein_Fahrlicht_Hinweis" 1 "Fahrlicht_Hinweis" ;
VAL_ 1626 BCM_HDF_betaetigt 0 "nicht_betaetigt" 1 "betaetigt" ;
VAL_ 2527679637 BCM_FAS_Taster 0 "nicht_betaetigt" 1 "betaetigt" ;
VAL_ 2527679637 CPD_Warnung 0 "keine_Warnung" 1 "Warnung_mit_Ton" 2 "Warnung_ohne_Ton" ;
VAL_ 2527679637 MiKo_Tisch_Positionswarnung 0 "keine_Anzeige_Tisch_unten" 1 "Warnung_Tisch_oben" ;
VAL_ 2527679637 LiSi_Touch_Event 0 "nicht_betaetigt" 1 "Tippen" 2 "Wischen_Slide" 3 "Geste" 4 "Doppeltippen" 5 "Longpress_1" 6 "Longpress_2" 7 "Longpress_3" 8 "Press" 9 "Strongpress" 10 "reserviert" 11 "reserviert" 12 "reserviert" 13 "reserviert" 14 "Taktgeber_Inkrement" 15 "Fehler" ;
VAL_ 2527679637 BCM_anf_VLW 0 "Init" 1 "VLW_angefordert_VLK2_1" 2 "deg_VLW_FT_angefordert" 3 "deg_VLW_Werkstatt_angefordert" 4 "VLW_angefordert_VLK2_2" 5 "Wegrollwarnung_angefordert" 6 "Rollfaehigkeit_ohne_Akustik" 7 "Rollfaehigkeit_mit_Akustik" ;
VAL_ 2527679637 BCM_Defrost_Taste 0 "Taste_nicht_betaetigt" 1 "Taste_betaetigt" 2 "Fehler" 3 "Init_oder_nicht_verbaut" ;
VAL_ 2527679637 BCM_HSH_Taste 0 "Taste_nicht_betaetigt" 1 "Taste_betaetigt" 2 "Fehler" 3 "Init_oder_nicht_verbaut" ;
VAL_ 2527679637 BCM_FSH_Taste 0 "Taste_nicht_betaetigt" 1 "Taste_betaetigt" 2 "Fehler" 3 "Init_oder_nicht_verbaut" ;
VAL_ 2527679637 LTMs_01_alt 0 "aktuell" 1 "veraltet" ;
VAL_ 2527679637 BCM_LTM_Nebelschluss_Status 0 "nicht_aktiv" 1 "aktiv" ;
VAL_ 2527679637 BCM_LTM_PopUp_Texte 0 "keine_Anzeige" 1 "Ausschalt_Hinweis" 2 "Ausschalt_Quittierung" ;
VAL_ 2527679637 BCM_LTM_Allwetterl_Status 0 "nicht_aktiv" 1 "aktiv" ;
VAL_ 2527679637 BCM_LTM_PopUp_Status 0 "Init" 1 "AUTO" 2 "Abblendlicht" 3 "Standlicht" 4 "OFF" ;
VAL_ 2527679637 BCM_LTM_Nebell_Status 0 "nicht_aktiv" 1 "aktiv" ;
VAL_ 2527679637 BCM_LTM_PopUp_Anf 0 "keine_Anforderung" 1 "Licht_PopUp" 2 "Nebellicht_PopUp" 3 "Allwetterlicht_PopUp" 4 "Nebelschlusslicht_PopUp" ;
VAL_ 2527679637 BCM_LTM_PopUp_Inhalt 0 "Init" 1 "AUTO" 2 "Abblendlicht" 4 "Standlicht" 8 "OFF" ;
VAL_ 2463978607 BCM_RGB_Intensitaet 126 "Init" 127 "Fehler" ;
VAL_ 2463978607 BCM_RGB_Normierung_Intensitaet 0 "ohne Normierung" 1 "Normierung der Intensität" ;
VAL_ 2463978607 BCM_RGB_Dimmzeit_Zeitbasis 0 "Zeitbasis_50ms" 1 "Zeitbasis_250ms" ;
VAL_ 2527679781 LINDa_HL_Touch_Event 0 "nicht_betaetigt" 1 "Tippen" 2 "Wischen_Slide" 3 "Geste" 4 "Doppeltippen" 5 "Longpress_1" 6 "Longpress_2" 7 "Longpress_3" 8 "Press" 9 "Strongpress" 10 "reserviert" 11 "reserviert" 12 "reserviert" 13 "reserviert" 14 "Taktgeber_Inkrement" 15 "Fehler" ;
VAL_ 2527679781 LINDa_HR_Touch_Event 0 "nicht_betaetigt" 1 "Tippen" 2 "Wischen_Slide" 3 "Geste" 4 "Doppeltippen" 5 "Longpress_1" 6 "Longpress_2" 7 "Longpress_3" 8 "Press" 9 "Strongpress" 10 "reserviert" 11 "reserviert" 12 "reserviert" 13 "reserviert" 14 "Taktgeber_Inkrement" 15 "Fehler" ;
VAL_ 2527679781 LINDa_HL_SR3_Touch_Event 0 "nicht_betaetigt" 1 "Tippen" 2 "Wischen_Slide" 3 "Geste" 4 "Doppeltippen" 5 "Longpress_1" 6 "Longpress_2" 7 "Longpress_3" 8 "Press" 9 "Strongpress" 10 "reserviert" 11 "reserviert" 12 "reserviert" 13 "reserviert" 14 "Taktgeber_Inkrement" 15 "Fehler" ;
VAL_ 2527679781 LINDa_HR_SR3_Touch_Event 0 "nicht_betaetigt" 1 "Tippen" 2 "Wischen_Slide" 3 "Geste" 4 "Doppeltippen" 5 "Longpress_1" 6 "Longpress_2" 7 "Longpress_3" 8 "Press" 9 "Strongpress" 10 "reserviert" 11 "reserviert" 12 "reserviert" 13 "reserviert" 14 "Taktgeber_Inkrement" 15 "Fehler" ;
VAL_ 2463978882 BedienDisp_hbfs_control_vol 0 "Init" 1 "Mute" 2 "Volume_up" 3 "Volume_down" 4 "Volume_up_relativ" 5 "Volume_down_relativ" 6 "Volume_absolut" 7 "Volume_prozent" 15 "Fehler" ;
VAL_ 2463978882 BedienDisp_hbfs_fader 0 "Init" 1 "Rear_Mute" 2 "Fader_front" 3 "Fader_rear" 4 "Front_Mute" 15 "Fehler" ;
VAL_ 2463978882 BedienDisp_hbfs_surround 0 "Init" 1 "Surround_off" 2 "Surround_up" 3 "Surround_down" 4 "Surround_up_relativ" 5 "Surround_down_relativ" 6 "Surround_absolut" 7 "Surround_prozent" 15 "Fehler" ;
VAL_ 2463978882 BedienDisp_hbfs_sound 0 "Init" 1 "No_function_availible" 2 "NaVi" 3 "SDS" 4 "Audio" 5 "TA" 6 "Phone" 7 "Phone_ringing" 8 "Digital_voice_assistant" ;
VAL_ 2463978882 BedienDisp_hbfs_Lordose_hoch 0 "Aus" 1 "Ein" ;
VAL_ 2463978882 BedienDisp_hbfs_Lordose_runter 0 "Aus" 1 "Ein" ;
VAL_ 2463978882 BedienDisp_hbfs_Lordose_vor 0 "Aus" 1 "Ein" ;
VAL_ 2463978882 BedienDisp_hbfs_Lordose_zurueck 0 "Aus" 1 "Ein" ;
VAL_ 2463978882 BedienDisp_hbfs_touch 0 "nicht_betaetigt" 1 "Tippen" 2 "Wischen_Slide" 3 "Geste" 4 "Doppeltippen_Doppelklick" 5 "Longpress_1_Halten_1" 6 "Longpress_2_Halten_2" 7 "Longpress_3_Halten_3" 8 "Press" 9 "Strong_Press" 10 "reserviert" 11 "reserviert" 12 "reserviert" 13 "reserviert" 14 "Taktgeber_Inkrement" 15 "Fehler" ;
VAL_ 2463978882 BedienDisp_hbfs_sound_fokus 0 "Init" 1 "All" 2 "Front_left" 3 "Front_right" 4 "Front" 5 "Rear_left" 6 "Rear_right" 7 "Rear" 14 "Surround" 15 "Fehler" ;
VAL_ 2463978882 BedienDisp_hbfs_surround_02 126 "Init" 127 "Fehler" ;
VAL_ 2463978882 BedienDisp_hbfs_control_vol_02 126 "Init" 127 "Fehler" ;
VAL_ 2463978882 BedienDisp_HBFSFo_Bestaetigung 0 "keine_Bestaetigung" 1 "Bestaetigung" 2 "Reserve" 3 "Fehler" ;
VAL_ 2463978882 BedienDisp_HBFSFo_Stoerung 0 "kein_Fehler_MCC4ABT" 1 "Fehler_MCC4ABT_aktiv" ;
VAL_ 2463978882 BedienDisp_hbfs_UseCase_Pos 0 "inaktiv_Init" 1 "UseCase_Pos_1" 2 "UseCase_Pos_2" 3 "UseCase_Pos_3" 4 "UseCase_Pos_4" 5 "UseCase_Pos_5" 6 "UseCase_Pos_6" 7 "UseCase_Pos_7" ;
VAL_ 2463978886 BedienDisp_hbfs_Sitz_Laengs 0 "inaktiv_Init" 1 "Laengs_vor" 2 "Laengs_zurueck" 3 "Laengs_vor_schnell" 4 "Laengs_zurueck_schnell" 5 "Fehler" ;
VAL_ 2463978886 BedienDisp_hbfs_Sitz_Hoehe 0 "inaktiv_Init" 1 "Hoehe_rauf" 2 "Hoehe_runter" 3 "Fehler" ;
VAL_ 2463978886 BedienDisp_hbfs_Sitz_Neigung 0 "inaktiv_Init" 1 "Neigung_kippen_vorn" 2 "Neigung_aufrichten_vorn" 3 "Neigung_kippen_hinten" 4 "Neigung_aufrichten_hinten" 5 "Fehler" ;
VAL_ 2463978886 BedienDisp_hbfs_Sitz_Bein 0 "inaktiv_Init" 1 "Beinauflage_ausklappen" 2 "Beinauflage_einklappen" 3 "Beinauflage_ausfahren" 4 "Beinauflage_einfahren" 5 "Fehler" ;
VAL_ 2463978886 BedienDisp_hbfs_Sitz_Lehne 0 "inaktiv_Init" 1 "Lehne_neigen" 2 "Lehne_aufrichten" 3 "Lehne_neigen_schnell" 4 "Lehne_aufrichten_schnell" 5 "Fehler" ;
VAL_ 2463978886 BedienDisp_hbfs_Sitz_Lehnekopf 0 "inaktiv_Init" 1 "Lehnenkopf_beugen" 2 "Lehnenkopf_aufrichten" 3 "Fehler" ;
VAL_ 2463978886 BedienDisp_hbfs_Sitz_Kopf 0 "inaktiv_Init" 1 "Kopfstuetze_rauf" 2 "Kopfstuetze_runter" 3 "Kopfstuetze_vor" 4 "Kopfstuetze_zurueck" 5 "Fehler" ;
VAL_ 2463978886 BedienDisp_hbfs_Sitz_Arm 0 "inaktiv_Init" 1 "Armlehne_ausklappen" 2 "Armlehne_einklappen" 3 "Armlehne_ausklappen_schnell" 4 "Armlehne_einklappen_schnell" 5 "Fehler" ;
VAL_ 2463978886 BedienDisp_hbfs_Seat_SetReset 0 "inaktiv_Init" 1 "Speicher_Aufforderung" 2 "Reset_Aufforderung" 3 "Abbruch" ;
VAL_ 2463978886 BedienDisp_hbfs_Seat_Storage 0 "inaktiv_Init" 1 "Memory_Pos_1" 2 "Memory_Pos_2" 3 "Memory_Pos_3" 4 "Memory_Pos_4" 5 "Arbeit_Pos_1" 6 "Ruhe_Pos_2" 7 "Liege_Pos_3" ;
VAL_ 2463978886 BedienDisp_hbfs_Mem_Start 0 "inaktiv_Init" 1 "Stop_Sitzverstellung" 2 "Start_Sitzverstellung" 3 "Fehler" ;
VAL_ 2463978886 BedienDisp_hbfs_Cargo_Pos 0 "inaktiv_Init" 1 "Cargoposition_anfahren" 2 "Cargoposition_nicht_anfahren" 3 "Fehler" ;
VAL_ 2463978886 BedienDisp_hbfs_Normal_Pos 0 "inaktiv_Init" 1 "Normalposition_anfahren" 2 "Normalposition_nicht_anfahren" 3 "Fehler" ;
VAL_ 2463978886 BedienDisp_hbfs_BF_Hoehe 0 "inaktiv_Init" 1 "Hoehe_BF_rauf" 2 "Hoehe_BF_runter" 3 "Fehler" ;
VAL_ 2463978886 BedienDisp_hbfs_BF_Laengs 0 "inaktiv_Init" 1 "Laengs_BF_vor" 2 "Laengs_BF_zurueck" 3 "Laengs_BF_vor_schnell" 4 "Laengs_BF_zurueck_schnell" 5 "Fehler" ;
VAL_ 2463978886 BedienDisp_hbfs_BF_Lehne 0 "inaktiv_Init" 1 "Lehne_BF_neigen" 2 "Lehne_BF_aufrichten" 3 "Lehne_BF_neigen_schnell" 4 "Lehne_BF_aufrichten_schnell" 5 "Fehler" ;
VAL_ 2463978886 BedienDisp_hbfs_Memo_Pos 0 "inaktiv_Init" 1 "Memory_Pos_1" 2 "Memory_Pos_2" 3 "Memory_Pos_3" 4 "Memory_Pos_4" 5 "Set_Long_Press" 6 "Reset_Long_Press" ;
VAL_ 2463978886 BedienDisp_hbfs_Sitz_Stop 0 "inaktiv_Init" 1 "Stop_Sitzverstellung" 2 "Start_Sitzverstellung" 3 "Fehler" ;
VAL_ 2463978886 BedienDisp_hbfs_Komfor_Pos 0 "inaktiv_Init" 1 "Arbeit_Pos_1" 2 "Ruhe_Pos_2" 3 "Liege_Pos_3" 4 "Set_Long_Press" 5 "Reset_Long_Press" ;
VAL_ 2463978881 BedienDisp_hfs_control_vol 0 "Init" 1 "Mute" 2 "Volume_up" 3 "Volume_down" 4 "Volume_up_relativ" 5 "Volume_down_relativ" 6 "Volume_absolut" 7 "Volume_prozent" 15 "Fehler" ;
VAL_ 2463978881 BedienDisp_hfs_fader 0 "Init" 1 "Rear_Mute" 2 "Fader_front" 3 "Fader_rear" 4 "Front_Mute" 15 "Fehler" ;
VAL_ 2463978881 BedienDisp_hfs_surround 0 "Init" 1 "Surround_off" 2 "Surround_up" 3 "Surround_down" 4 "Surround_up_relativ" 5 "Surround_down_relativ" 6 "Surround_absolut" 7 "Surround_prozent" 15 "Fehler" ;
VAL_ 2463978881 BedienDisp_hfs_sound 0 "Init" 1 "No_function_availible" 2 "NaVi" 3 "SDS" 4 "Audio" 5 "TA" 6 "Phone" 7 "Phone_ringing" 8 "Digital_voice_assistant" ;
VAL_ 2463978881 BedienDisp_hfs_Lordose_hoch 0 "Aus" 1 "Ein" ;
VAL_ 2463978881 BedienDisp_hfs_Lordose_runter 0 "Aus" 1 "Ein" ;
VAL_ 2463978881 BedienDisp_hfs_Lordose_vor 0 "Aus" 1 "Ein" ;
VAL_ 2463978881 BedienDisp_hfs_Lordose_zurueck 0 "Aus" 1 "Ein" ;
VAL_ 2463978881 BedienDisp_hfs_touch 0 "nicht_betaetigt" 1 "Tippen" 2 "Wischen_Slide" 3 "Geste" 4 "Doppeltippen_Doppelklick" 5 "Longpress_1_Halten_1" 6 "Longpress_2_Halten_2" 7 "Longpress_3_Halten_3" 8 "Press" 9 "Strong_Press" 10 "reserviert" 11 "reserviert" 12 "reserviert" 13 "reserviert" 14 "Taktgeber_Inkrement" 15 "Fehler" ;
VAL_ 2463978881 BedienDisp_hfs_sound_fokus 0 "Init" 1 "All" 2 "Front_left" 3 "Front_right" 4 "Front" 5 "Rear_left" 6 "Rear_right" 7 "Rear" 14 "Surround" 15 "Fehler" ;
VAL_ 2463978881 BedienDisp_hfs_surround_02 126 "Init" 127 "Fehler" ;
VAL_ 2463978881 BedienDisp_hfs_control_vol_02 126 "Init" 127 "Fehler" ;
VAL_ 2463978881 BedienDisp_HFSFo_Bestaetigung 0 "keine_Bestaetigung" 1 "Bestaetigung" 2 "Reserve" 3 "Fehler" ;
VAL_ 2463978881 BedienDisp_HFSFo_Stoerung 0 "kein_Fehler_MCC4ABT" 1 "Fehler_MCC4ABT_aktiv" ;
VAL_ 2463978881 BedienDisp_hfs_UseCase_Pos 0 "inaktiv_Init" 1 "UseCase_Pos_1" 2 "UseCase_Pos_2" 3 "UseCase_Pos_3" 4 "UseCase_Pos_4" 5 "UseCase_Pos_5" 6 "UseCase_Pos_6" 7 "UseCase_Pos_7" ;
VAL_ 2463978885 BedienDisp_hfs_Sitz_Laengs 0 "inaktiv_Init" 1 "Laengs_vor" 2 "Laengs_zurueck" 3 "Laengs_vor_schnell" 4 "Laengs_zurueck_schnell" 5 "Fehler" ;
VAL_ 2463978885 BedienDisp_hfs_Sitz_Hoehe 0 "inaktiv_Init" 1 "Hoehe_rauf" 2 "Hoehe_runter" 3 "Fehler" ;
VAL_ 2463978885 BedienDisp_hfs_Sitz_Neigung 0 "inaktiv_Init" 1 "Neigung_kippen_vorn" 2 "Neigung_aufrichten_vorn" 3 "Neigung_kippen_hinten" 4 "Neigung_aufrichten_hinten" 5 "Fehler" ;
VAL_ 2463978885 BedienDisp_hfs_Sitz_Bein 0 "inaktiv_Init" 1 "Beinauflage_ausklappen" 2 "Beinauflage_einklappen" 3 "Beinauflage_ausfahren" 4 "Beinauflage_einfahren" 5 "Fehler" ;
VAL_ 2463978885 BedienDisp_hfs_Sitz_Lehne 0 "inaktiv_Init" 1 "Lehne_neigen" 2 "Lehne_aufrichten" 3 "Lehne_neigen_schnell" 4 "Lehne_aufrichten_schnell" 5 "Fehler" ;
VAL_ 2463978885 BedienDisp_hfs_Sitz_Lehnekopf 0 "inaktiv_Init" 1 "Lehnenkopf_beugen" 2 "Lehnenkopf_aufrichten" 3 "Fehler" ;
VAL_ 2463978885 BedienDisp_hfs_Sitz_Kopf 0 "inaktiv_Init" 1 "Kopfstuetze_rauf" 2 "Kopfstuetze_runter" 3 "Kopfstuetze_vor" 4 "Kopfstuetze_zurueck" 5 "Fehler" ;
VAL_ 2463978885 BedienDisp_hfs_Sitz_Arm 0 "inaktiv_Init" 1 "Armlehne_ausklappen" 2 "Armlehne_einklappen" 3 "Armlehne_ausklappen_schnell" 4 "Armlehne_einklappen_schnell" 5 "Fehler" ;
VAL_ 2463978885 BedienDisp_hfs_Seat_SetReset 0 "inaktiv_Init" 1 "Speicher_Aufforderung" 2 "Reset_Aufforderung" 3 "Abbruch" ;
VAL_ 2463978885 BedienDisp_hfs_Seat_Storage 0 "inaktiv_Init" 1 "Memory_Pos_1" 2 "Memory_Pos_2" 3 "Memory_Pos_3" 4 "Memory_Pos_4" 5 "Arbeit_Pos_1" 6 "Ruhe_Pos_2" 7 "Liege_Pos_3" ;
VAL_ 2463978885 BedienDisp_hfs_Mem_Start 0 "inaktiv_Init" 1 "Start_Tip_Sitzverstellung" 2 "Start_Tast_Sitzverstellung" 3 "Fehler" ;
VAL_ 2463978885 BedienDisp_hfs_Cargo_Pos 0 "inaktiv_Init" 1 "Cargoposition_anfahren" 2 "Cargoposition_nicht_anfahren" 3 "Fehler" ;
VAL_ 2463978885 BedienDisp_hfs_Normal_Pos 0 "inaktiv_Init" 1 "Normalposition_anfahren" 2 "Normalposition_nicht_anfahren" 3 "Fehler" ;
VAL_ 2463978885 BedienDisp_hfs_BF_Hoehe 0 "inaktiv_Init" 1 "Hoehe_BF_rauf" 2 "Hoehe_BF_runter" 3 "Fehler" ;
VAL_ 2463978885 BedienDisp_hfs_BF_Laengs 0 "inaktiv_Init" 1 "Laengs_BF_vor" 2 "Laengs_BF_zurueck" 3 "Laengs_BF_vor_schnell" 4 "Laengs_BF_zurueck_schnell" 5 "Fehler" ;
VAL_ 2463978885 BedienDisp_hfs_BF_Lehne 0 "inaktiv_Init" 1 "Lehne_BF_neigen" 2 "Lehne_BF_aufrichten" 3 "Lehne_BF_neigen_schnell" 4 "Lehne_BF_aufrichten_schnell" 5 "Fehler" ;
VAL_ 2463978885 BedienDisp_hfs_Memo_Pos 0 "inaktiv_Init" 1 "Memory_Pos_1" 2 "Memory_Pos_2" 3 "Memory_Pos_3" 4 "Memory_Pos_4" 5 "Set_Long_Press" 6 "Reset_Long_Press" ;
VAL_ 2463978885 BedienDisp_hfs_Sitz_Stop 0 "inaktiv_Init" 1 "Stop_Sitzverstellung" 2 "Start_Sitzverstellung" 3 "Fehler" ;
VAL_ 2463978885 BedienDisp_hfs_Komfor_Pos 0 "inaktiv_Init" 1 "Arbeit_Pos_1" 2 "Ruhe_Pos_2" 3 "Liege_Pos_3" 4 "Set_Long_Press" 5 "Reset_Long_Press" ;
VAL_ 2463978863 BedienDisp_vm_Control 0 "Init" 1 "Mute" 2 "Rotary_up" 3 "Rotary_down" 15 "Fehler" ;
VAL_ 2463978863 BedienDisp_vm_Function 0 "Init" 1 "No_function_availible" 2 "Volume" 3 "Air_Volume" 4 "Air_Distribution" 5 "Driving_modes" 6 "iClimate" 7 "MapZoom" ;
VAL_ 2463978863 BedienDisp_vm_Press 0 "Init" 1 "No_function_availible" 2 "Druck_normal" 3 "Druck_lange" 4 "Druck_Bestaetigung" 15 "Fehler" ;
VAL_ 2463978863 BedienDisp_vm_Aktive_Ebene 0 "ohne_Verwendung" 1 "Ebene_1_aktiv" 2 "Ebene_2_aktiv" ;
VAL_ 2463978863 BedienDisp_vm_Ist_Profil 0 "nicht_belegt" 1 "Profil_Comfort" 2 "Profil_Normal" 3 "Profil_Sport" 4 "Profil_Offroad" 5 "Profil_Eco" 6 "Profil_Race" 7 "Profil_Individual" 8 "Profil_Range" 9 "Profil_Lift" 10 "Profil_Snow" 11 "Profil_Offroad_Expert" 12 "nicht_belegt" 13 "nicht_belegt" 14 "nicht_belegt" 15 "nicht_belegt" 16 "Profil_Drift" 17 "Profil_Special" 18 "nicht_belegt" 19 "Profil_Traction" ;
VAL_ 2463978863 BedienDisp_vm_Taster 0 "nicht_betaetigt" 1 "betaetigt" 2 "reserviert" 3 "reserviert_Tastenklemmer" ;
VAL_ 2463978863 BedienDisp_vm_defekt 0 "nicht_defekt" 1 "Funktion_defekt" 2 "AMB_Fluegel_defekt" 3 "nicht_belegt" 4 "nicht_belegt" 5 "nicht_belegt" 6 "nicht_belegt" 7 "nicht_belegt" 8 "nicht_belegt" 9 "nicht_belegt" 10 "nicht_belegt" 11 "nicht_belegt" 12 "nicht_belegt" 13 "nicht_belegt" 14 "nicht_belegt" 15 "nicht_belegt" ;
VAL_ 2463978863 BedienDisp_vm_Touch 0 "nicht_betaetigt" 1 "Tippen" 2 "Wischen_Slide" 3 "Geste" 4 "Doppeltippen_Doppelklick" 5 "Longpress_1_Halten_1" 6 "Longpress_2_Halten_2" 7 "Longpress_3_Halten_3" 8 "Press" 9 "Strong_Press" 10 "reserviert" 11 "reserviert" 12 "reserviert" 13 "reserviert" 14 "Taktgeber_Inkrement" 15 "Fehler" ;
VAL_ 1635 NVEM_Abschaltstufe 0 "Stufe_0_keine_Einschraenkung" 1 "Stufe_1" 2 "Stufe_2" 3 "Stufe_3" ;
VAL_ 1635 BEM_STH_Zielzeit 14 "Init" 15 "Fehler" ;
VAL_ 1635 BEM_MMI_Vorwarnung 0 "keine Anzeige" 1 "Anzeige MMI-Vorwarnung" ;
VAL_ 1635 NVEM_Freigabe_ZusBatt_Laden 0 "keine_Freigabe_Laderelais" 1 "Freigabe_Laderelais_schliessen" ;
VAL_ 1635 NVEM_Anf_SD_schalten 0 "Anf_SD_Nachlauf_nicht_aktiv" 1 "Anf_SD_Nachlauf_aktiv" ;
VAL_ 1635 BEM_Generatordiagnose 0 "keine Anzeige" 1 "Ladekontrollanzeige ein (Vorhalt)" 2 "rotes Batteriesymbol und Text (Generator defekt)" 3 "Hybrid_DCDC_Wandler_defekt" ;
VAL_ 1635 BEM_Red_Innengeblaese 0 "keine Reduzierung" 1 "Reduzierung Stufe 1" 2 "Reduzierung Stufe 2" 3 "Reduzierung Stufe 2 und Abschaltung Kompressor" ;
VAL_ 1635 BEM_STH_Einschaltverbot 0 "volle Verfuegbarkeit Standheizung/-lueftung" 1 "Standheizung/-lueftung nicht aktivierbar" ;
VAL_ 1635 BEM_HL_Regelung_Status 0 "HL_Regelung_inaktiv_(vor_und_waehrend_Motorstart)" 1 "HL_Regelung_Stufe_1" 2 "HL_Regelung_Stufe_2" 3 "HL_Regelung_Stufe_3" 4 "Verbrauchernotabschaltung_(VNA)" 5 "HL_Regelung_Stufe_5" 7 "Default" ;
VAL_ 1635 BEM_Ladezustand 14 "Init" 15 "Fehler" ;
VAL_ 1635 BEM_Batteriediagnose 0 "keine_Anzeige" 1 "nicht_belegt" 2 "Anzeige_aberkannte_Batterie" 3 "Anzeige_schwache_Batterie" 4 "Anzeige_Batterie_OK" 5 "Anzeige_Batterie_Laden" 6 "Anzeige_Batterie_Pruefen" 7 "Fehler" ;
VAL_ 1635 MIB_Stromsparmodus 0 "inaktiv" 1 "aktiv" ;
VAL_ 1635 BEM_REK_aktiv 0 "keine_Rekuperationsfreigabe" 1 "Rekuperationsfreigabe" ;
VAL_ 1635 BEM_EMLIN_ungueltig 0 "Signale_gueltig" 1 "Signale_ungueltig" ;
VAL_ 1635 BEM_Batt_Ab 0 "verbunden" 1 "nicht_verbunden" ;
VAL_ 1635 BEM_UBDM 0 "Init" 255 "Fehler" ;
VAL_ 1635 BEM_Anf_KL15_schalten 0 "Keine_Einschraenkung_Kl15" 1 "Empfehlung_auto_Abschaltung_Kl15" 2 "Veto_auto_Abschaltung_Kl15" 3 "Veto_auto_Abschaltung_Fahrtbetrieb" ;
VAL_ 1635 NVEM_Batterie_Service 0 "kein_Service" 1 "Service_Information1" 2 "Service_Information2" 3 "Service_Information3" ;
VAL_ 1635 NVEM_Freigabe_OnlineUpdate 0 "keine_Freigabe" 1 "Freigabe" ;
VAL_ 1635 NVEM_Freigabe_ORU4 0 "Init" 1 "keine_Freigabe" 2 "Freigabe_erteilt" 3 "Veto_Freigabe" ;
VAL_ 1635 NVEM_Verbraucherabsch_Anz 0 "keine_Anzeige" 1 "Anzeige_aktiv" ;
VAL_ 2463978850 NVEM_Bordnetz_Information 0 "keine_Anzeige" 1 "NV_Batterie_iO" 2 "NV_Batterie_laden" 3 "NV_Batterie_pruefen" 4 "NV_Batterie_schwach" 5 "NV_Batterie_Ab" 6 "NV_Batterie_Service" 7 "NV_Energiesystem_unplausibel" 8 "Ladekontrollleuchte" 9 "Generator_defekt" 10 "reserviert" 11 "reserviert" 12 "reserviert" 13 "reserviert" 14 "Init" 15 "Fehler" ;
VAL_ 2463978850 NVEM_Verbraucher_Information 0 "Keine_Anzeige" 1 "MMI_Vorwarnung" 2 "Anzeige_Verbraucherabschaltung" 3 "reserviert" 4 "reserviert" 5 "reserviert" 6 "Init" 7 "Fehler" ;
VAL_ 2463978850 NVEM2_VerbrZustandsAnf 0 "Freigabe" 1 "Verbraucher_Sperren" 2 "Verbr_Sperren_KL_Red" 3 "reserved" 4 "reserved" 5 "reserved" 6 "Verbr_Sperren_KL_Anf" 7 "Teilweise_Anschalt_Anf" 8 "Anschalt_Anf" 9 "reserved" 10 "reserved" 11 "Abschaltstufe_1" 12 "Abschaltstufe_2" 13 "Abschaltstufe_3" 14 "Init" 15 "Fehler" ;
VAL_ 2463978850 NVEM_NVStuetzungAnf 0 "keine_Anforderung" 1 "Anforderung_sichere_Versorgung" 2 "Anforderung_Abschaltung" 3 "Fehler" ;
VAL_ 2463978850 NVEM3_Absch_SCR 0 "Init" 1 "Abschaltung_SCR" ;
VAL_ 2463978850 NVEM_Batt_Temp_Hinweis 0 "Keine_Anzeige" 1 "Hinweis_Aussenhuelle_zu" 2 "Hinweis_Klima_ein" 3 "Wunsch_Aussenhuelle_zu" 4 "Wunsch_Klima_ein" ;
VAL_ 870 BM_ZV_auf 0 "inaktiv" 1 "aktiv" ;
VAL_ 870 BM_ZV_zu 0 "inaktiv" 1 "aktiv" ;
VAL_ 870 BM_DWA_ein 0 "inaktiv" 1 "aktiv" ;
VAL_ 870 BM_DWA_Alarm 0 "inaktiv" 1 "aktiv" ;
VAL_ 870 BM_Crash 0 "inaktiv" 1 "aktiv" ;
VAL_ 870 BM_Panik 0 "inaktiv" 1 "aktiv" ;
VAL_ 870 BM_Not_Bremsung 0 "kein_blinken" 1 "Notbremswarnblinken_aktiv" ;
VAL_ 870 BM_GDO 0 "inaktiv" 1 "aktiv" ;
VAL_ 870 BM_Warnblinken 0 "inaktiv" 1 "aktiv" ;
VAL_ 870 BM_Taxi_Notalarm 0 "inaktiv" 1 "aktiv" ;
VAL_ 870 BM_Telematik 0 "inaktiv" 1 "aktiv" ;
VAL_ 870 BM_links 0 "inaktiv" 1 "aktiv" ;
VAL_ 870 BM_rechts 0 "inaktiv" 1 "aktiv" ;
VAL_ 870 Blinken_li_Fzg_Takt 0 "Blinker_links_ausgeschaltet" 1 "Blinker_links_eingeschaltet" ;
VAL_ 870 Blinken_re_Fzg_Takt 0 "Blinker_rechts_ausgeschaltet" 1 "Blinker_rechts_eingeschaltet" ;
VAL_ 870 Blinken_li_Kombi_Takt 0 "Blinkerkontrolllampe_links_ausgeschaltet" 1 "Blinkerkontrolllampe_links_eingeschaltet" ;
VAL_ 870 Blinken_re_Kombi_Takt 0 "Blinkerkontrolllampe_rechts_ausgeschaltet" 1 "Blinkerkontrolllampe_rechts_eingeschaltet" ;
VAL_ 870 BM_NBA_n_codiert_n_aktiv 0 "codiert_AND_kein_Fehler" 1 "nicht_codiert_OR_Fehler_erkannt" ;
VAL_ 870 BM_NBA_Status 0 "NBA_nicht_aktiv" 1 "BRL_Dunkelphase" 3 "BRL_Hellphase" ;
VAL_ 870 BM_WBT_Beleuchtung 0 "inaktiv" 1 "aktiv" ;
VAL_ 870 BM_HD_Oeffnung_angelernt 0 "keine_Quittierung" 1 "Quittierung" ;
VAL_ 870 BM_Autobahn 0 "inaktiv" 1 "aktiv" ;
VAL_ 870 BM_Rollenmodus_Blinken 0 "inaktiv" 1 "aktiv" ;
VAL_ 870 BM_Recas 0 "kein_blinken" 1 "Recasblinken_aktiv" ;
VAL_ 870 BM_Wischblinken 0 "inaktiv" 1 "aktiv" ;
VAL_ 870 BM_Telematik_Abbruchgrund 0 "Init" 1 "speed_out_of_range" 2 "defect" 3 "clamp_s_on" 4 "clamp_15_on" 5 "door_open" 6 "engine_hood_open" 7 "trunk_open" 8 "convertible_top_not_locked" 9 "horn_activated_by_user" 10 "Higher_Prioritiy_Function_active" 11 "Central_Lock_status_changed" 12 "Request_Dropped_by_Requester" 13 "Service_Duration_Expired" 14 "not_possible_due_to_coding" 15 "no_reason_or_unknown_timeout" ;
VAL_ 870 BM_PiloPa 0 "PiloPa_Blinkerquittierung_inaktiv" 1 "PiloPa_Blinkerquittierung_aktiv" ;
VAL_ 870 SAL_TA_Blinken_Status 0 "init" 1 "nicht_bereit" 2 "bereit" 3 "aktiv_links" 4 "aktiv_rechts" ;
VAL_ 870 BM_WBA_Warnblinken 0 "WBA_Warnblinken_inaktiv" 1 "WBA_Warnblinken_aktiv" ;
VAL_ 870 SAL_RHP_Blinken_Status 0 "init" 1 "nicht_bereit" 2 "bereit" 3 "aktiv_links" 4 "aktiv_rechts" ;
VAL_ 870 SAL_RHP_Warnblinken 0 "inaktiv" 1 "aktiv" ;
VAL_ 2589283664 BMS_Balancing_Aktiv 0 "Init" 1 "aktiv" 2 "nicht_aktiv" ;
VAL_ 2589283664 BMS_Ladevorgang_aktiv 0 "inaktiv" 1 "aktiv" ;
VAL_ 2589283664 BMS_RIso_Ext 4094 "Init" 4095 "Fehler" ;
VAL_ 2589283664 BMS_Min_Ladezustand 2046 "Init" ;
VAL_ 2589283664 BMS_Max_Energie 8190 "Init" ;
VAL_ 2589283664 BMS_Max_Ladezustand 2046 "Init" ;
VAL_ 2589283941 CHA_Drehschalter_AktivesProfil 0 "nicht_belegt" 1 "Profil_Comfort" 2 "Profil_Normal" 3 "Profil_Sport" 4 "Profil_Offroad" 5 "Profil_Eco" 6 "Profil_Race" 7 "Profil_Individual" 8 "Profil_Range" 9 "Profil_Lift" 10 "Profil_Snow" 11 "Profil_Offroad_Expert" 12 "nicht_belegt" 13 "nicht_belegt" 14 "nicht_belegt" 15 "nicht_belegt" 16 "Profil_Drift" 17 "Profil_Special" 18 "nicht_belegt" 19 "Profil_Traction" ;
VAL_ 2589283941 CHA_Drehschalter_Profil_1 0 "Kein_Profil" 1 "Profil_1" 2 "Profil_2" 3 "Profil_3" 4 "Profil_4" 5 "Profil_5" 6 "Profil_6" 7 "Profil_7" 8 "Profil_8" 9 "Profil_9" 10 "Profil_10" 11 "Profil_11" 12 "Profil_12" 13 "Profil_13" 14 "Profil_14" 15 "Profil_15" 16 "Profil_16" 17 "Profil_17" 18 "Profil_18" 19 "Profil_19" 20 "Profil_20" 21 "Profil_21" 22 "Profil_22" 23 "Profil_23" 24 "Profil_24" 25 "Profil_25" 26 "Profil_26" 27 "Profil_27" 28 "Profil_28" 29 "Profil_29" 30 "Profil_30" 31 "Profil_31" 32 "Profil_32" ;
VAL_ 2589283941 CHA_Drehschalter_Profil_2 0 "Kein_Profil" 1 "Profil_1" 2 "Profil_2" 3 "Profil_3" 4 "Profil_4" 5 "Profil_5" 6 "Profil_6" 7 "Profil_7" 8 "Profil_8" 9 "Profil_9" 10 "Profil_10" 11 "Profil_11" 12 "Profil_12" 13 "Profil_13" 14 "Profil_14" 15 "Profil_15" 16 "Profil_16" 17 "Profil_17" 18 "Profil_18" 19 "Profil_19" 20 "Profil_20" 21 "Profil_21" 22 "Profil_22" 23 "Profil_23" 24 "Profil_24" 25 "Profil_25" 26 "Profil_26" 27 "Profil_27" 28 "Profil_28" 29 "Profil_29" 30 "Profil_30" 31 "Profil_31" 32 "Profil_32" ;
VAL_ 2589283941 CHA_Drehschalter_Profil_3 0 "Kein_Profil" 1 "Profil_1" 2 "Profil_2" 3 "Profil_3" 4 "Profil_4" 5 "Profil_5" 6 "Profil_6" 7 "Profil_7" 8 "Profil_8" 9 "Profil_9" 10 "Profil_10" 11 "Profil_11" 12 "Profil_12" 13 "Profil_13" 14 "Profil_14" 15 "Profil_15" 16 "Profil_16" 17 "Profil_17" 18 "Profil_18" 19 "Profil_19" 20 "Profil_20" 21 "Profil_21" 22 "Profil_22" 23 "Profil_23" 24 "Profil_24" 25 "Profil_25" 26 "Profil_26" 27 "Profil_27" 28 "Profil_28" 29 "Profil_29" 30 "Profil_30" 31 "Profil_31" 32 "Profil_32" ;
VAL_ 2589283941 CHA_Drehschalter_Profil_4 0 "Kein_Profil" 1 "Profil_1" 2 "Profil_2" 3 "Profil_3" 4 "Profil_4" 5 "Profil_5" 6 "Profil_6" 7 "Profil_7" 8 "Profil_8" 9 "Profil_9" 10 "Profil_10" 11 "Profil_11" 12 "Profil_12" 13 "Profil_13" 14 "Profil_14" 15 "Profil_15" 16 "Profil_16" 17 "Profil_17" 18 "Profil_18" 19 "Profil_19" 20 "Profil_20" 21 "Profil_21" 22 "Profil_22" 23 "Profil_23" 24 "Profil_24" 25 "Profil_25" 26 "Profil_26" 27 "Profil_27" 28 "Profil_28" 29 "Profil_29" 30 "Profil_30" 31 "Profil_31" 32 "Profil_32" ;
VAL_ 2589283941 CHA_Drehschalter_Profil_5 0 "Kein_Profil" 1 "Profil_1" 2 "Profil_2" 3 "Profil_3" 4 "Profil_4" 5 "Profil_5" 6 "Profil_6" 7 "Profil_7" 8 "Profil_8" 9 "Profil_9" 10 "Profil_10" 11 "Profil_11" 12 "Profil_12" 13 "Profil_13" 14 "Profil_14" 15 "Profil_15" 16 "Profil_16" 17 "Profil_17" 18 "Profil_18" 19 "Profil_19" 20 "Profil_20" 21 "Profil_21" 22 "Profil_22" 23 "Profil_23" 24 "Profil_24" 25 "Profil_25" 26 "Profil_26" 27 "Profil_27" 28 "Profil_28" 29 "Profil_29" 30 "Profil_30" 31 "Profil_31" 32 "Profil_32" ;
VAL_ 2589283941 CHA_Drehschalter_Profil_6 0 "Kein_Profil" 1 "Profil_1" 2 "Profil_2" 3 "Profil_3" 4 "Profil_4" 5 "Profil_5" 6 "Profil_6" 7 "Profil_7" 8 "Profil_8" 9 "Profil_9" 10 "Profil_10" 11 "Profil_11" 12 "Profil_12" 13 "Profil_13" 14 "Profil_14" 15 "Profil_15" 16 "Profil_16" 17 "Profil_17" 18 "Profil_18" 19 "Profil_19" 20 "Profil_20" 21 "Profil_21" 22 "Profil_22" 23 "Profil_23" 24 "Profil_24" 25 "Profil_25" 26 "Profil_26" 27 "Profil_27" 28 "Profil_28" 29 "Profil_29" 30 "Profil_30" 31 "Profil_31" 32 "Profil_32" ;
VAL_ 2589283941 CHA_Drehschalter_Profil_7 0 "Kein_Profil" 1 "Profil_1" 2 "Profil_2" 3 "Profil_3" 4 "Profil_4" 5 "Profil_5" 6 "Profil_6" 7 "Profil_7" 8 "Profil_8" 9 "Profil_9" 10 "Profil_10" 11 "Profil_11" 12 "Profil_12" 13 "Profil_13" 14 "Profil_14" 15 "Profil_15" 16 "Profil_16" 17 "Profil_17" 18 "Profil_18" 19 "Profil_19" 20 "Profil_20" 21 "Profil_21" 22 "Profil_22" 23 "Profil_23" 24 "Profil_24" 25 "Profil_25" 26 "Profil_26" 27 "Profil_27" 28 "Profil_28" 29 "Profil_29" 30 "Profil_30" 31 "Profil_31" 32 "Profil_32" ;
VAL_ 902 CHA_Charisma_Taste2_LED 0 "LED_aus" 1 "LED_ein" 2 "LED_blinken" 3 "Fehler" ;
VAL_ 902 CHA_ReqPrgDispSetup 0 "init" 1 "layout_comfort" 2 "layout_eco" 3 "layout_sport" 4 "layout_offroad" 5 "layout_sportplus" 6 "program_6" 7 "program_7" 8 "program_8" 9 "program_9" 10 "program_10" 11 "program_11" 12 "program_12" 13 "program_13" 14 "program_14" 15 "program_15" ;
VAL_ 902 CHA_Current_Mode_FPA 0 "keine_Funktion" 1 "Programm_1" 2 "Programm_2" 3 "Programm_3" 4 "Programm_4" 5 "Programm_5" 6 "Programm_6" 7 "Programm_7" 8 "Programm_8" 9 "Programm_9" 10 "Programm_10" 11 "Programm_11" 12 "Programm_12" 13 "Programm_13" 14 "Programm_14" 15 "Programm_15" 16 "Programm_16" 17 "Programm_17" 18 "Programm_18" 19 "Programm_19" 20 "Programm_20" 21 "Programm_21" 22 "Programm_22" 23 "Programm_23" 24 "Programm_24" 25 "Programm_25" 26 "Programm_26" 27 "Programm_27" 28 "Programm_28" 29 "Programm_29" 30 "Programm_30" 31 "Programm_31" 32 "Programm_32" ;
VAL_ 902 CHA_Eco_Charisma_LED 0 "LED_aus_und_Blinken_aus" 1 "LED_ein_und_Blinken_aus" 2 "LED_ein_und_Blinken_ein_50_percent" 3 "reserviert" ;
VAL_ 902 CHA_Fahrer_Umschaltung 0 "keine_oder_automatische_Umschaltung" 1 "manuelle_Umschaltung" ;
VAL_ 902 CHA_EV_LED 0 "LED_aus" 1 "LED_an" ;
VAL_ 902 CHA_Ziel_FahrPr_AMB 0 "keine_Funktion" 1 "Programm_1" 2 "Programm_2" 3 "Programm_3" 4 "Programm_4" 5 "Programm_5" 6 "Programm_6" 7 "Programm_7" 8 "Programm_8" 9 "Programm_9" 10 "Programm_10" 11 "Programm_11" 12 "Programm_12" 13 "Programm_13" 14 "Programm_14" 15 "Programm_15" ;
VAL_ 902 CHA_Ziel_FahrPr_IVB 0 "keine_Funktion" 1 "Programm_1" 2 "Programm_2" 3 "Programm_3" 4 "Programm_4" 5 "Programm_5" 6 "Programm_6" 7 "Programm_7" 8 "Programm_8" 9 "Programm_9" 10 "Programm_10" 11 "Programm_11" 12 "Programm_12" 13 "Programm_13" 14 "Programm_14" 15 "Programm_15" ;
VAL_ 902 CHA_Kombi_Texte 0 "keine_Anzeige" 1 "Text_1" 2 "Text_2" 3 "Text_3" 4 "Text_4" 5 "Text_5" 6 "Text_6" 7 "Text_7" 8 "Text_8" 9 "Text_9" 10 "Text_10" 11 "Text_11" 12 "Text_12" 13 "Text_13" 14 "Text_14" 15 "Text_15" ;
VAL_ 902 CHA_Ziel_FahrPr_KL 0 "keine_Funktion" 1 "Programm_1" 2 "Programm_2" 3 "Programm_3" 4 "Programm_4" 5 "Programm_5" 6 "Programm_6" 7 "Programm_7" 8 "Programm_8" 9 "Programm_9" 10 "Programm_10" 11 "Programm_11" 12 "Programm_12" 13 "Programm_13" 14 "Programm_14" 15 "Programm_15" ;
VAL_ 902 CHA_Ziel_FahrPr_HSP 0 "keine_Funktion" 1 "Programm_1" 2 "Programm_2" 3 "Programm_3" 4 "Programm_4" 5 "Programm_5" 6 "Programm_6" 7 "Programm_7" 8 "Programm_8" 9 "Programm_9" 10 "Programm_10" 11 "Programm_11" 12 "Programm_12" 13 "Programm_13" 14 "Programm_14" 15 "Programm_15" ;
VAL_ 902 CHA_StCurProfDft 0 "Init" 1 "profile_is_not_configurable" 2 "profile_is_default" 3 "profile_is_not_default" ;
VAL_ 902 CHA_Ziel_FahrPr_RWB 0 "keine_Funktion" 1 "Programm_1" 2 "Programm_2" 3 "Programm_3" 4 "Programm_4" 5 "Programm_5" 6 "Programm_6" 7 "Programm_7" 8 "Programm_8" 9 "Programm_9" 10 "Programm_10" 11 "Programm_11" 12 "Programm_12" 13 "Programm_13" 14 "Programm_14" 15 "Programm_15" ;
VAL_ 902 CHA_Ziel_FahrPr_03_01 0 "keine_Funktion" 1 "Programm_1" 2 "Programm_2" 3 "Programm_3" 4 "Programm_4" 5 "Programm_5" 6 "Programm_6" 7 "Programm_7" 8 "Programm_8" 9 "Programm_9" 10 "Programm_10" 11 "Programm_11" 12 "Programm_12" 13 "Programm_13" 14 "Programm_14" 15 "Programm_15" ;
VAL_ 902 CHA_Ziel_FahrPr_03_02 0 "keine_Funktion" 1 "Programm_1" 2 "Programm_2" 3 "Programm_3" 4 "Programm_4" 5 "Programm_5" 6 "Programm_6" 7 "Programm_7" 8 "Programm_8" 9 "Programm_9" 10 "Programm_10" 11 "Programm_11" 12 "Programm_12" 13 "Programm_13" 14 "Programm_14" 15 "Programm_15" ;
VAL_ 902 CHA_Current_Mode 0 "keine_Funktion" 1 "Programm_1" 2 "Programm_2" 3 "Programm_3" 4 "Programm_4" 5 "Programm_5" 6 "Programm_6" 7 "Programm_7" 8 "Programm_8" 9 "Programm_9" 10 "Programm_10" 11 "Programm_11" 12 "Programm_12" 13 "Programm_13" 14 "Programm_14" 15 "Programm_15" ;
VAL_ 902 CHA_Charge_LED 0 "LED_aus" 1 "LED_ein" ;
VAL_ 902 CHA_Offroad_LED 0 "LED_aus" 1 "LED_ein" 2 "LED_blinken" 3 "Fehler" ;
VAL_ 902 CHA_Kombi_Texte_02 0 "Init" 1 "Text_1" 2 "Text_2" 3 "Text_3" 4 "Text_4" 5 "Text_5" 6 "Text_6" 7 "Text_7" 8 "Text_8" 9 "Text_9" 10 "Text_10" 11 "Text_11" 12 "Text_12" 13 "Text_13" 14 "Text_14" 15 "Text_15" ;
VAL_ 2527679921 CPD_CallCenter 0 "Init_keine_Alarmierung_CallCenter" 1 "CPD_Alarmierung_CallCenter" 2 "CPD_Abbruch_CallCenter" 3 "reserved" ;
VAL_ 2527679921 CPD_Deaktivierung_Temp 0 "InitWert" 1 "keine_Deaktivierung_Temp" 2 "CPD_Deaktivierung_Temp" ;
VAL_ 2527679921 CPD_Deaktivierung_Permanent 0 "InitWert" 1 "keine_Deaktivierung_Permanent" 2 "CPD_Deaktivierung_Permanent" ;
VAL_ 2527679921 CPD_Mobiltelefon_GSM 0 "Init_keine_Warnung_GSM" 1 "CPD_Warnung_GSM" 2 "reserved" 3 "reserved" ;
VAL_ 2527679921 CPD_Mobiltelefon_BLE 0 "Init_keine_Warnung_BT" 1 "CPD_Warnung_BT" ;
VAL_ 2527679921 CPDFct_Warnung 0 "keine_Anzeige" 1 "Warnung_mit_Ton" 2 "Warnung_ohne_Ton" 3 "Anzeige_Funktion_deaktiviert" 4 "Anzeige_Systemfehler" ;
VAL_ 2527679921 CPDFct_Symbol 0 "Keine_Anzeige" 1 "aktiv" ;
VAL_ 2527679921 CPDFct_Deakt 0 "keine_Anzeige" 1 "Anzeige_Funktion_deaktiviert" ;
VAL_ 1714 DGN_Verlernzaehler 255 "ungültiger Zählerstand oder kein gültiger Fahrzyklus" ;
VAL_ 1714 KBI_Kilometerstand 1048574 "Init" 1048575 "Fehler" ;
VAL_ 1714 UH_Monat 0 "Init" 14 "Relatives_Datum" 15 "Fehler" ;
VAL_ 1714 UH_Tag 0 "Init" ;
VAL_ 1714 Vehicle_Driving_Cycle 0 "kein_Driving_Cycle_erkannt" 1 "Driving_Cycle_erkannt" ;
VAL_ 1714 Kombi_02_alt 0 "aktuell" 1 "veraltet" ;
VAL_ 1714 Uhrzeit_01_alt 0 "aktuell" 1 "veraltet" ;
VAL_ 851 DiETa_Status 0 "DiETa_betriebsbereit" 2 "Init" 3 "Fehler_oder_defekt" ;
VAL_ 851 DiETa_ResponseError 0 "normal" 1 "Fehler" ;
VAL_ 851 DiETa_Car 0 "Init_oder_nicht_verbaut" 1 "Taste_unbetaetigt" 2 "Taste_betaetigt" 3 "Fehler" ;
VAL_ 851 DiETa_Klima 0 "Init_oder_nicht_verbaut" 1 "Taste_unbetaetigt" 2 "Taste_betaetigt" 3 "Fehler" ;
VAL_ 851 DiETa_Mode 0 "Init_oder_nicht_verbaut" 1 "Taste_unbetaetigt" 2 "Taste_betaetigt" 3 "Fehler" ;
VAL_ 851 DiETa_Parken 0 "Init_oder_nicht_verbaut" 1 "Taste_unbetaetigt" 2 "Taste_betaetigt" 3 "Fehler" ;
VAL_ 851 DiETa_FSH_Taste 0 "Init_oder_nicht_verbaut" 1 "Taste_unbetaetigt" 2 "Taste_betaetigt" 3 "Fehler" ;
VAL_ 851 DiETa_HSH_Taste 0 "Init_oder_nicht_verbaut" 1 "Taste_unbetaetigt" 2 "Taste_betaetigt" 3 "Fehler" ;
VAL_ 851 DiETa_Warnblink_Taste 0 "Init_oder_nicht_verbaut" 1 "Taste_unbetaetigt" 2 "Taste_betaetigt" 3 "Fehler" ;
VAL_ 851 DiETa_FAS_Stufe 0 "Init_oder_nicht_verbaut" 1 "Taste_unbetaetigt" 2 "Taste_betaetigt" 3 "Fehler" ;
VAL_ 851 DiETa_PAO_ON_Status 0 "LED_Aus" 1 "LED_Ein" 2 "LED_Blinkt" 3 "LED_defekt" ;
VAL_ 851 DiETa_PAO_OFF_Status 0 "LED_Aus" 1 "LED_Ein" 2 "LED_Blinkt" 3 "LED_defekt" ;
VAL_ 851 DiETa_Defrost_Taste 0 "Init_oder_nicht_verbaut" 1 "Taste_unbetaetigt" 2 "Taste_betaetigt" 3 "Fehler" ;
VAL_ 851 DiETa_Mode2 0 "Init_oder_nicht_verbaut" 1 "Taste_unbetaetigt" 2 "Taste_betaetigt" 3 "Fehler" ;
VAL_ 851 DiETa_Lock_Unlock_Taste 0 "Init" 1 "Taste_unbetaetigt" 2 "Taste_betaetigt_unlock" 3 "Taste_betaetigt_lock" 4 "Reserviert" 5 "Reserviert" 6 "Reserviert" 7 "Fehler" ;
VAL_ 851 DiETa_Mode_roh 0 "Taste_unbetaetigt" 1 "Taste_betaetigt" ;
VAL_ 851 ESP_Off_Taster 0 "Taste_nicht_betaetigt" 1 "Taste_entprellt_betaetigt" 2 "Init_oder_nicht_verbaut" 3 "Fehler" ;
VAL_ 851 DiETa_Touch_Event 0 "nicht_betaetigt" 1 "Tippen" 2 "Wischen_Slide" 3 "Geste" 4 "Doppeltippen" 5 "Longpress_1" 6 "Longpress_2" 7 "Longpress_3" 8 "Press" 9 "Strongpress" 10 "reserviert" 11 "reserviert" 12 "reserviert" 13 "reserviert" 14 "Taktgeber_Inkrement" 15 "Fehler" ;
